VERSION ""

NS_ :

BS_:

BU_: GENERIC_GWMWakeup Generic_BCM TRM GWM _delete APIM SODL RTM FCIM PDM SCMH SCMG HSWM GPSM RSM SODR DDM RBM DSM SCME TSTR

BO_ 292 ClmtCtrlSeatSet_Cmd: 8 FCIM
 SG_ ClmtCtrlSeat_SetCmd_Psgr : 15|8@0+ (1,0) [0|254] "SED"  SCME
 SG_ ClmtCtrlSeat_SetCmd_Dvr : 7|8@0+ (1,0) [0|254] "SED"  SCME

BO_ 1284 DDM_Network_MgmtM: 8 DDM
 SG_ DDM_Network_Mgmt : 7|64@0+ (1,0) [0|1.844674407371E+019] "unitless"  PDM,GWM,TRM,RTM,FCIM,RBM,GPSM,DSM,SCME

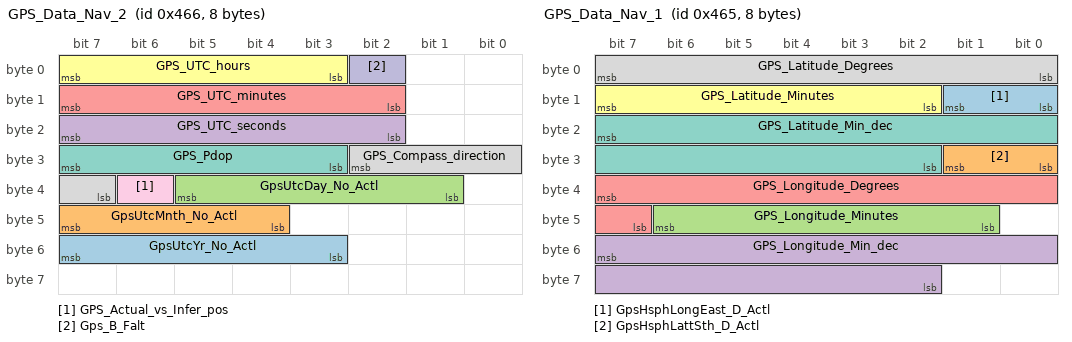
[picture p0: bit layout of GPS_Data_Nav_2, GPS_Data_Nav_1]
BO_ 1126 GPS_Data_Nav_2: 8 GPSM
 SG_ GpsUtcYr_No_Actl : 55|5@0+ (1,2010) [2010|2040] "Year"  RSM,APIM,GWM
 SG_ GpsUtcMnth_No_Actl : 47|4@0+ (1,1) [1|15] "Month"  RSM,APIM,GWM
 SG_ GpsUtcDay_No_Actl : 37|5@0+ (1,1) [1|31] "Day"  RSM,APIM,GWM
 SG_ GPS_UTC_seconds : 23|6@0+ (1,0) [0|59] "seconds"  RSM,APIM,GWM
 SG_ GPS_UTC_minutes : 15|6@0+ (1,0) [0|59] "Minutes"  RSM,APIM,GWM
 SG_ GPS_UTC_hours : 7|5@0+ (1,0) [0|23] "Hours"  RSM,APIM,GWM
 SG_ GPS_Pdop : 31|5@0+ (0.2,0) [0|5.8] "unitless"  RSM,APIM,GWM
 SG_ GPS_Compass_direction : 26|4@0+ (1,0) [0|15] "SED"  RSM,APIM,GWM
 SG_ GPS_Actual_vs_Infer_pos : 38|1@0+ (1,0) [0|1] "SED"  RSM,APIM,GWM
 SG_ Gps_B_Falt : 2|1@0+ (1,0) [0|1] "SED"  RSM,APIM,GWM

BO_ 1125 GPS_Data_Nav_1: 8 GPSM
 SG_ GpsHsphLongEast_D_Actl : 9|2@0+ (1,0) [0|3] "SED"  RSM,APIM,GWM
 SG_ GpsHsphLattSth_D_Actl : 25|2@0+ (1,0) [0|3] "SED"  RSM,APIM,GWM
 SG_ GPS_Longitude_Minutes : 46|6@0+ (1,0) [0|61] "Minutes"  RSM,APIM,GWM
 SG_ GPS_Longitude_Min_dec : 55|14@0+ (0.0001,0) [0|1.6381] "Minutes"  RSM,APIM,GWM
 SG_ GPS_Longitude_Degrees : 39|9@0+ (1,-179) [-179|330] "Degrees"  RSM,APIM,GWM
 SG_ GPS_Latitude_Minutes : 15|6@0+ (1,0) [0|61] "Minutes"  RSM,APIM,GWM
 SG_ GPS_Latitude_Min_dec : 23|14@0+ (0.0001,0) [0|1.6381] "Minutes"  RSM,APIM,GWM
 SG_ GPS_Latitude_Degrees : 7|8@0+ (1,-89) [-89|164] "Degrees"  RSM,APIM,GWM

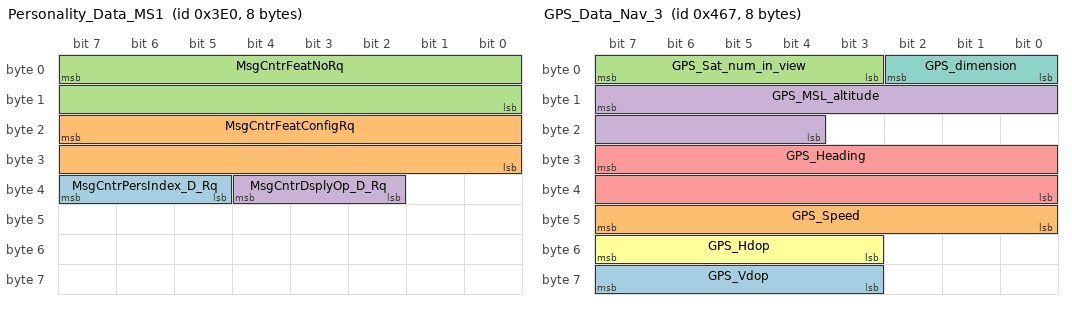
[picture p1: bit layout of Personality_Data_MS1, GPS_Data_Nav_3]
BO_ 992 Personality_Data_MS1: 8 GWM
 SG_ MsgCntrPersIndex_D_Rq : 39|3@0+ (1,0) [0|7] "SED"  DDM,FCIM,DSM
 SG_ MsgCntrFeatConfigRq : 23|16@0+ (1,0) [0|65535] "Undefined"  DDM,FCIM,DSM
 SG_ MsgCntrFeatNoRq : 7|16@0+ (1,0) [0|65535] "Number"  DDM,FCIM,DSM
 SG_ MsgCntrDsplyOp_D_Rq : 36|3@0+ (1,0) [0|7] "SED"  DDM,FCIM,DSM

BO_ 1127 GPS_Data_Nav_3: 8 GPSM
 SG_ GPS_Vdop : 63|5@0+ (0.2,0) [0|5.8] "unitless"  RSM,APIM,GWM
 SG_ GPS_Speed : 47|8@0+ (1,0) [0|253] "MPH"  RSM,APIM,GWM
 SG_ GPS_Sat_num_in_view : 7|5@0+ (1,0) [0|29] "unitless"  RSM,APIM,GWM
 SG_ GPS_MSL_altitude : 15|12@0+ (10,-20460) [-20460|20470] "feet"  RSM,APIM,GWM
 SG_ GPS_Heading : 31|16@0+ (0.01,0) [0|655.33] "Degrees"  RSM,APIM,GWM
 SG_ GPS_Hdop : 55|5@0+ (0.2,0) [0|5.8] "unitless"  RSM,APIM,GWM
 SG_ GPS_dimension : 2|3@0+ (1,0) [0|7] "SED"  RSM,APIM,GWM

BO_ 861 HSWheel_CC_Info_Stat: 8 HSWM
 SG_ SteWhlHeat_D_Stat : 7|4@0+ (1,0) [0|15] "SED"  FCIM

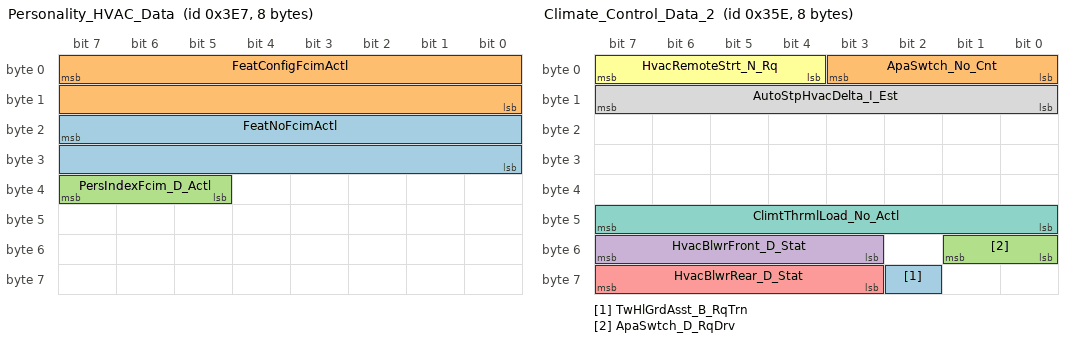
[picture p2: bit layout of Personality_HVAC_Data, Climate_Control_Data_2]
BO_ 999 Personality_HVAC_Data: 8 FCIM
 SG_ FeatNoFcimActl : 23|16@0+ (1,0) [0|65535] "Number"  GWM
 SG_ FeatConfigFcimActl : 7|16@0+ (1,0) [0|65535] "Undefined"  GWM
 SG_ PersIndexFcim_D_Actl : 39|3@0+ (1,0) [0|7] "SED"  GWM

BO_ 1998 TesterPhysicalResSODR: 8 SODR
 SG_ TesterPhysicalResSODR : 7|64@0+ (1,0) [0|1.84467E+019] "unitless"  TSTR

BO_ 1990 TesterPhysicalReqSODR: 8 TSTR
 SG_ TesterPhysicalReqSODR : 7|64@0+ (1,0) [0|1.84467E+019] "unitless"  SODR

BO_ 1996 TesterPhysicalResSODL: 8 SODL
 SG_ TesterPhysicalResSODL : 7|64@0+ (1,0) [0|1.84467E+019] "unitless"  TSTR

BO_ 1988 TesterPhysicalReqSODL: 8 TSTR
 SG_ TesterPhysicalReqSODL : 7|64@0+ (1,0) [0|1.84467E+019] "unitless"  SODL

BO_ 862 Climate_Control_Data_2: 8 FCIM
 SG_ TwHlGrdAsst_B_RqTrn : 58|1@0+ (1,0) [0|1] "SED"  GWM
 SG_ ApaSwtch_No_Cnt : 3|4@0+ (1,0) [0|15] "Unitless"  GWM
 SG_ ApaSwtch_D_RqDrv : 49|2@0+ (1,0) [0|3] "SED"  GWM
 SG_ HvacBlwrFront_D_Stat : 55|5@0+ (1,0) [0|31] "SED"  GWM
 SG_ HvacBlwrRear_D_Stat : 63|5@0+ (1,0) [0|31] "SED"  GWM
 SG_ HvacRemoteStrt_N_Rq : 7|4@0+ (100,450) [450|1950] "RPM"  GWM
 SG_ ClimtThrmlLoad_No_Actl : 47|8@0+ (1,0) [0|254] "unitless"  GWM
 SG_ AutoStpHvacDelta_I_Est : 15|8@0+ (1,-192) [-192|62] "ampere"  GWM

BO_ 828 Pass_Window_Stat: 8 PDM
 SG_ RearPassWindowPos : 4|3@0+ (1,0) [0|7] "SED"  FCIM,GWM,Generic_BCM
 SG_ PassWindowPosition : 7|3@0+ (1,0) [0|7] "SED"  FCIM,GWM,Generic_BCM

BO_ 2000 TesterPhysicalReqAPIM: 8 TSTR
 SG_ TesterPhysicalReqAPIM : 7|64@0+ (1,0) [0|1.84467E+019] "unitless"  APIM

BO_ 1894 TesterPhysicalReqRBM: 8 TSTR
 SG_ TesterPhysicalReqRBM : 7|64@0+ (1,0) [0|1.84467E+019] "unitless"  RBM

BO_ 1349 RBM_Network_MgmtM: 8 RBM
 SG_ RBM_Network_Mgmt : 7|64@0+ (1,0) [0|1.844674407371E+019] "unitless"  APIM,PDM,TRM,GWM,RTM,FCIM,GPSM,DSM,DDM,SCME

BO_ 1902 TesterPhysicalResRBM: 8 RBM
 SG_ TesterPhysicalResRBM : 7|64@0+ (1,0) [0|1.84467E+019] "unitless"  TSTR

BO_ 1860 TesterPhysicalReqDSM: 8 TSTR
 SG_ TesterPhysicalReqDSM : 7|64@0+ (1,0) [0|1.84467E+019] "unitless"  DSM

BO_ 1868 TesterPhysicalResDSM: 8 DSM
 SG_ TesterPhysicalResDSM : 7|64@0+ (1,0) [0|1.84467E+019] "unitless"  TSTR

BO_ 1918 TesterPhysicalResSCME: 8 SCME
 SG_ TesterPhysicalResSCME : 7|64@0+ (1,0) [0|1.84467E+019] "unitless"  TSTR

BO_ 1910 TesterPhysicalReqSCME: 8 TSTR
 SG_ TesterPhysicalReqSCME : 7|64@0+ (1,0) [0|1.84467E+019] "unitless"  SCME

BO_ 1814 TesterPhysicalReqGWM_M1: 8 TSTR
 SG_ TesterPhysicalReqGWM_M1 : 7|64@0+ (1,0) [0|1.84467E+019] "unitless"  GWM

BO_ 1822 TesterPhysicalResGWM_MS1: 8 GWM
 SG_ TesterPhysicalResGWM_M1 : 7|64@0+ (1,0) [0|1.84467E+019] "unitless"  TSTR

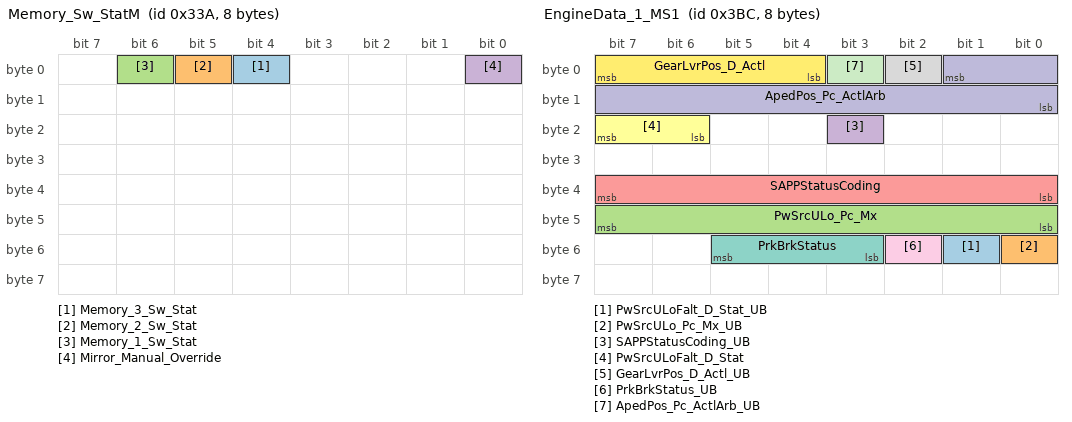
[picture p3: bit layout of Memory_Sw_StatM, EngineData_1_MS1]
BO_ 826 Memory_Sw_StatM: 8 DDM
 SG_ Memory_3_Sw_Stat : 4|1@0+ (1,0) [0|1] "SED"  DSM
 SG_ Memory_2_Sw_Stat : 5|1@0+ (1,0) [0|1] "SED"  DSM
 SG_ Memory_1_Sw_Stat : 6|1@0+ (1,0) [0|1] "SED"  DSM
 SG_ Mirror_Manual_Override : 0|1@0+ (1,0) [0|1] "SED"  DSM

BO_ 853 Clmt_Button_Stat1: 8 FCIM
 SG_ RHS_Cond_Seat_Status : 63|3@0+ (1,0) [0|7] "SED"  GWM
 SG_ LHS_Cond_Seat_Status : 10|3@0+ (1,0) [0|7] "SED"  GWM
 SG_ Htd_Strg_Whl_Status : 27|2@0+ (1,0) [0|3] "SED"  GWM
 SG_ Htd_Strg_Whl_Btn_Stt : 29|2@0+ (1,0) [0|3] "SED"  GWM
 SG_ Defrost_Btn_Stt : 3|2@0+ (1,0) [0|3] "SED"  GWM
 SG_ CC_Fr_Btn_User_Adj : 15|5@0+ (1,0) [0|31] "SED"  GWM
 SG_ RHS_Htd_Seat_Btn_Stt : 53|2@0+ (1,0) [0|3] "SED"  GWM
 SG_ RHS_Cld_Seat_Btn_Stt : 55|2@0+ (1,0) [0|3] "SED"  GWM
 SG_ Outside_Btn_Stt : 47|2@0+ (1,0) [0|3] "SED"  GWM
 SG_ LHS_Htd_Seat_Btn_Stt : 39|2@0+ (1,0) [0|3] "SED"  GWM
 SG_ LHS_Cld_Seat_Btn_Stt : 25|2@0+ (1,0) [0|3] "SED"  GWM
 SG_ Htd_Frt_Wsh_Btn_Stt : 31|2@0+ (1,0) [0|3] "SED"  GWM
 SG_ Auto_Recirc_Btn_Stt : 5|2@0+ (1,0) [0|3] "SED"  GWM
 SG_ Recirc_Btn_Stt : 41|2@0+ (1,0) [0|3] "SED"  GWM
 SG_ Rear_Defrost_Btn_Stt : 43|2@0+ (1,0) [0|3] "SED"  GWM
 SG_ My_Temp_Btn_Stt : 33|2@0+ (1,0) [0|3] "SED"  GWM
 SG_ Max_Defrost_Btn_Stt : 35|2@0+ (1,0) [0|3] "SED"  GWM
 SG_ Max_AC_Btn_Stt : 37|2@0+ (1,0) [0|3] "SED"  GWM
 SG_ Front_AUTO_Label : 19|2@0+ (1,0) [0|3] "SED"  GWM
 SG_ Windscreen_Btn_Stt : 51|2@0+ (1,0) [0|3] "SED"  GWM
 SG_ Panel_Btn_Stt : 45|2@0+ (1,0) [0|3] "SED"  GWM
 SG_ Front_Power_Btn_Stt : 17|2@0+ (1,0) [0|3] "SED"  GWM
 SG_ Front_AUTO_Btn_Stt : 21|2@0+ (1,0) [0|3] "SED"  GWM
 SG_ Floor_Btn_Stt : 23|2@0+ (1,0) [0|3] "SED"  GWM
 SG_ Dual_Button_Stt : 1|2@0+ (1,0) [0|3] "SED"  GWM
 SG_ AC_Btn_Stt : 7|2@0+ (1,0) [0|3] "SED"  GWM

BO_ 1034 GGCC_Config_Mgmt_ID_1_MS1: 8 GWM
 SG_ VehicleGGCCData : 7|64@0+ (1,0) [0|1.84467E+019] "mixed"  TRM,PDM,RTM,DDM,FCIM,GPSM,RBM,SODL,SODR

BO_ 956 EngineData_1_MS1: 8 GWM
 SG_ PwSrcULoFalt_D_Stat_UB : 49|1@0+ (1,0) [0|1] "SED" Vector__XXX
 SG_ PwSrcULo_Pc_Mx_UB : 48|1@0+ (1,0) [0|1] "SED"  FCIM
 SG_ PwSrcULo_Pc_Mx : 47|8@0+ (0.4,0) [0|101.6] "%"  FCIM
 SG_ SAPPStatusCoding_UB : 19|1@0+ (1,0) [0|1] "SED"  FCIM,SODL,SODR
 SG_ SAPPStatusCoding : 39|8@0+ (1,0) [0|255] "unitless"  FCIM,SODL,SODR
 SG_ PwSrcULoFalt_D_Stat : 23|2@0+ (1,0) [0|3] "SED" Vector__XXX
 SG_ PrkBrkStatus : 53|3@0+ (1,0) [0|7] "SED"  FCIM
 SG_ GearLvrPos_D_Actl_UB : 2|1@0+ (1,0) [0|1] "SED"  RBM,FCIM,DSM,SCMG,SCMH,DDM,PDM,GPSM,SODL,SODR
 SG_ PrkBrkStatus_UB : 50|1@0+ (1,0) [0|1] "SED"  FCIM
 SG_ ApedPos_Pc_ActlArb : 1|10@0+ (0.1,0) [0|102.3] "%"  FCIM
 SG_ ApedPos_Pc_ActlArb_UB : 3|1@0+ (1,0) [0|1] "SED"  FCIM
 SG_ GearLvrPos_D_Actl : 7|4@0+ (1,0) [0|15] "SED"  RBM,FCIM,DSM,SCMG,SCMH,DDM,PDM,GPSM,SODR,SODL

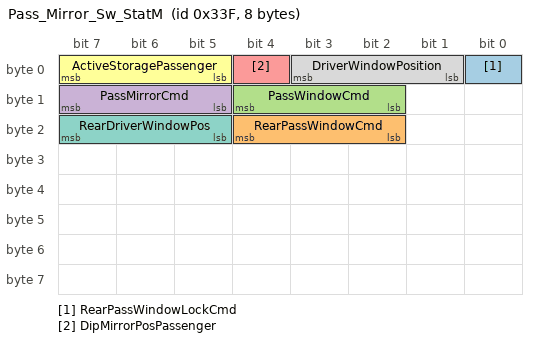
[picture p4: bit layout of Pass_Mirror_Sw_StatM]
BO_ 831 Pass_Mirror_Sw_StatM: 8 DDM
 SG_ RearPassWindowLockCmd : 0|1@0+ (1,0) [0|1] "SED"  PDM
 SG_ RearPassWindowCmd : 20|3@0+ (1,0) [0|7] "SED"  PDM
 SG_ PassWindowCmd : 12|3@0+ (1,0) [0|7] "SED"  PDM
 SG_ PassMirrorCmd : 15|3@0+ (1,0) [0|7] "SED"  PDM
 SG_ DipMirrorPosPassenger : 4|1@0+ (1,0) [0|1] "SED"  PDM
 SG_ ActiveStoragePassenger : 7|3@0+ (1,0) [0|7] "SED"  PDM
 SG_ RearDriverWindowPos : 23|3@0+ (1,0) [0|7] "SED"  FCIM,GWM
 SG_ DriverWindowPosition : 3|3@0+ (1,0) [0|7] "SED"  FCIM,Generic_BCM,GWM

BO_ 1820 TesterPhysicalResHSWM: 8 HSWM
 SG_ TesterPhysicalResHSWM : 7|64@0+ (1,0) [0|1.84467E+019] "unitless"  TSTR

BO_ 1812 TesterPhysicalReqHSWM: 8 TSTR
 SG_ TesterPhysicalReqHSWM : 7|64@0+ (1,0) [0|1.84467E+019] "unitless"  HSWM

BO_ 1291 DSM_Network_MgmtM: 8 DSM
 SG_ DSM_Network_Mgmt : 7|8@0+ (1,0) [0|254] "unitless"  APIM,PDM,TRM,GWM,RTM,FCIM,RBM,GPSM,DDM,SCME

BO_ 1319 SCME_Network_MgmtM: 8 SCME
 SG_ SCME_Network_Mgmt : 7|64@0+ (1,0) [0|1.844674407371E+019] "unitless"  APIM,PDM,TRM,RTM,FCIM,GWM,RBM,GPSM,DSM,DDM

BO_ 1388 GPSM_Network_MgmtM: 8 GPSM
 SG_ GPSM_Network_Mgmt : 7|64@0+ (1,0) [0|1.844674407371E+019] "unitless"  APIM,PDM,TRM,GWM,FCIM,RTM,SCME,DDM,DSM,RBM

BO_ 1801 TesterPhysicalResGPSM: 8 GPSM
 SG_ TesterPhysicalResGPSM : 7|64@0+ (1,0) [0|1.84467E+019] "unitless"  TSTR

BO_ 1793 TesterPhysicalReqGPSM: 8 TSTR
 SG_ TesterPhysicalReqGPSM : 7|64@0+ (1,0) [0|1.84467E+019] "unitless"  GPSM

BO_TX_BU_ 1126 : GWM,GPSM;
BO_TX_BU_ 1125 : GWM,GPSM;
BO_TX_BU_ 1127 : GWM,GPSM;
CM_ BO_ 1126 "Only NAV ACM & GPS need to Transmit this message. 
Non-NAV ACM shall not transmit it.";
CM_ BO_ 1125 "Only NAV ACM & GPS need to Transmit this message. 
Non-NAV ACM shall not transmit it.";
CM_ BO_ 1127 "Only NAV ACM & GPS need to Transmit this message. 
Non-NAV ACM shall not transmit it.";
CM_ BO_ 828 "Set GenSigSendType = NoSigSendType (Cyclic) for the following signals, D.Card 3/31/08
Driver_Lock_Sw_Stat
";
CM_ SG_ 1034 VehicleGGCCData "RCMGenSigTimeout=6000";
CM_ SG_ 956 ApedPos_Pc_ActlArb "ABSGenSigTimeoutTime=1000";
BA_DEF_ SG_  "U_V36X_MY18_5_Gas_Rx" ENUM  "No","Yes";
BA_DEF_ SG_  "U_V36X_MY18_5_Hev_Rx" ENUM  "No","Yes";
BA_DEF_ SG_  "U_U55x_MY18_Gas_Rx" ENUM  "No","Yes";
BA_DEF_ SG_  "U_V408_MY18_Gas_Rx" ENUM  "No","Yes";
BA_DEF_ SG_  "U_V408_MY18_Diesel_Rx" ENUM  "No","Yes";
BA_DEF_ SG_  "U_V36X_MY18_5_Diesel_Rx" ENUM  "No","Yes";
BA_DEF_ SG_  "U_V36X_MY19_5_Diesel_Rx" ENUM  "No","Yes";
BA_DEF_ SG_  "U_V363E_N_MY19_5_20_Gas_Rx" ENUM  "No","Yes";
BA_DEF_ SG_  "U_V363E_N_MY19_5_20_Diesel_Rx" ENUM  "No","Yes";
BA_DEF_ SG_  "U_U55x_MY18_Gas_Tx" ENUM  "No","Yes";
BA_DEF_ SG_  "GenSigTimeoutTime_SCMJ" INT 0 100000;
BA_DEF_ BO_  "FrameGatewayNetwork" STRING ;
BA_DEF_ SG_  "U_CD42_MY16_Diesel_Rx" ENUM  "No","Yes";
BA_DEF_ SG_  "U_CD42_MY16_Gas_Rx" ENUM  "No","Yes";
BA_DEF_ SG_  "U_CD43_MY17_Gas_Rx" ENUM  "No","Yes";
BA_DEF_ SG_  "U_P552_MY17_Gas_Rx" ENUM  "No","Yes";
BA_DEF_ SG_  "U_P552_MY17_Gas_Tx" ENUM  "No","Yes";
BA_DEF_ SG_  "GenSigTimeoutTime_SOBDMD_AHCM_F" INT 0 100000;
BA_DEF_ SG_  "GenSigTimeoutTime_SFMA" INT 0 100000;
BA_DEF_ SG_  "GenSigTimeoutTime_SFMB" INT 0 100000;
BA_DEF_ SG_  "GenSigTimeoutTime_SCMD" INT 0 100000;
BA_DEF_ SG_  "GenSigTimeoutTime_DCMH" INT 0 100000;
BA_DEF_ SG_  "GenSigTimeoutTime_DCMG" INT 0 100000;
BA_DEF_ SG_  "GenSigTimeoutTime_DCMF" INT 0 100000;
BA_DEF_ SG_  "GenSigTimeoutTime_DCME" INT 0 100000;
BA_DEF_ SG_  "GenSigTimeoutTime_BCMB_ABM" INT 0 100000;
BA_DEF_ SG_  "GenSigTimeoutTime_SCMC" INT 0 100000;
BA_DEF_ SG_  "GenSigTimeoutTime_BCMB_CAPM" INT 0 100000;
BA_DEF_ SG_  "GenSigTimeoutTime_GFM_ASM" INT 0 100000;
BA_DEF_ SG_  "GenSigTimeoutTime_SCMB_PSM" INT 0 100000;
BA_DEF_ SG_  "GenSigTimeoutTime_BCMB_ALCM" INT 0 100000;
BA_DEF_ SG_  "U_CD42_MY15_Diesel_Rx" ENUM  "No","Yes";
BA_DEF_ SG_  "U_CD42_MY15_Gas_Rx" ENUM  "No","Yes";
BA_DEF_ SG_  "U_U502_MY16_Gas_Rx" ENUM  "No","Yes";
BA_DEF_ SG_  "U_P558_MY17_Gas_Rx" ENUM  "No","Yes";
BA_DEF_ SG_  "U_P558_MY17_Diesel_Rx" ENUM  "No","Yes";
BA_DEF_ SG_  "U_CD42_MY15_Diesel_Tx" ENUM  "No","Yes";
BA_DEF_ SG_  "U_CD42_MY15_Gas_Tx" ENUM  "No","Yes";
BA_DEF_ SG_  "U_CD4_MY15_Diesel_Tx" ENUM  "No","Yes";
BA_DEF_ SG_  "U_CD4_MY15_Gas_Tx" ENUM  "No","Yes";
BA_DEF_ SG_  "U_CD4_MY15_Hev_Tx" ENUM  "No","Yes";
BA_DEF_ SG_  "U_CD4_MY15_Phev_Tx" ENUM  "No","Yes";
BA_DEF_ SG_  "U_P558_MY17_Gas_Tx" ENUM  "No","Yes";
BA_DEF_ SG_  "U_P558_MY17_Diesel_Tx" ENUM  "No","Yes";
BA_DEF_ SG_  "GenSigTimeoutTime_SCMF" INT 0 100000;
BA_DEF_ SG_  "GenSigTimeoutTime_RGTM" INT 0 100000;
BA_DEF_ SG_  "GenSigTimeoutTime_GENERIC" INT 0 100000;
BA_DEF_ SG_  "GenSigTimeoutTime_AHCM_FOH" INT 0 100000;
BA_DEF_ SG_  "GenSigTimeoutTime_RLCMA" INT 0 100000;
BA_DEF_ SG_  "GenSigTimeoutTime_BCMB" INT 0 100000;
BA_DEF_ SG_  "GenSigTimeoutTime_RHVAC" INT 0 100000;
BA_DEF_ SG_  "GenSigTimeoutTime_MRCMB" INT 0 100000;
BA_DEF_ SG_  "GenSigTimeoutTime_MRCMA" INT 0 100000;
BA_DEF_ SG_  "GenSigTimeoutTime_HVAC_RCCM" INT 0 100000;
BA_DEF_ SG_  "Gateway_ID" INT 0 0;
BA_DEF_ SG_  "GenSigTimeoutTime__delete" INT 0 100000;
BA_DEF_ SG_  "GenSigTimeoutTime_APIM" INT 0 100000;
BA_DEF_ SG_  "GenSigTimeoutTime_Generic_BCM" INT 0 100000;
BA_DEF_ SG_  "GenSigTimeoutTime_RSM" INT 0 100000;
BA_DEF_ SG_  "GenSigTimeoutTime_PDM" INT 0 100000;
BA_DEF_ SG_  "GenSigTimeoutTime_TRM" INT 0 100000;
BA_DEF_ SG_  "GenSigTimeoutTime_SCMG" INT 0 100000;
BA_DEF_ SG_  "GenSigTimeoutTime_SCMH" INT 0 100000;
BA_DEF_ SG_  "GenSigTimeoutTime_RTM" INT 0 100000;
BA_DEF_ SG_  "GenSigTimeoutTime_GWM" INT 0 100000;
BA_DEF_ SG_  "GenSigTimeoutTime_FCIM" INT 0 100000;
BA_DEF_ SG_  "GenSigTimeoutTime_HSWM" INT 0 100000;
BA_DEF_ SG_  "GenSigTimeoutTime_GPSM" INT 0 100000;
BA_DEF_ SG_  "GenSigTimeoutTime_RBM" INT 0 100000;
BA_DEF_ SG_  "GenSigTimeoutTime_DDM" INT 0 100000;
BA_DEF_ SG_  "GenSigTimeoutTime_DSM" INT 0 100000;
BA_DEF_ SG_  "GenSigTimeoutTime_SODR" INT 0 100000;
BA_DEF_ SG_  "GenSigTimeoutTime_SODL" INT 0 100000;
BA_DEF_ SG_  "GenSigTimeoutTime_TSTR" INT 0 100000;
BA_DEF_ SG_  "GenSigTimeoutTime_SCME" INT 0 100000;
BA_DEF_ BO_  "FrameGatewayMS1" HEX 0 1407;
BA_DEF_ BO_  "FrameGatewayHS3" HEX 0 1407;
BA_DEF_ BO_  "FrameGatewayHS2" HEX 0 1407;
BA_DEF_ BO_  "FrameGatewayHS1" HEX 0 1407;
BA_DEF_ BO_  "NetworkInitialization" ENUM  "No","Yes";
BA_DEF_ BO_  "FrameGatewayId" HEX 0 1407;
BA_DEF_ BO_  "EventRateOfChange" INT 10 10000;
BA_DEF_ BO_  "GenMsgStartDelayTime" INT 0 10000;
BA_DEF_ BO_  "GenMsgNrOfRepetition" INT 0 100;
BA_DEF_ BO_  "GenMsgDelayTime" INT 0 1000;
BA_DEF_ BO_  "GenMsgCycleTime" INT 0 100000;
BA_DEF_ BO_  "GenMsgSendType" ENUM  "FixedPeriodic","Event","EnabledPeriodic","NotUsed","NotUsed","EventPeriodic","NotUsed","NotUsed","NoMsgSendType";
BA_DEF_ SG_  "U_CD4_MY14_Phev_Tx" ENUM  "No","Yes";
BA_DEF_ SG_  "U_CD4_MY14_Hev_Tx" ENUM  "No","Yes";
BA_DEF_ SG_  "U_CD4_MY14_Gas_Tx" ENUM  "No","Yes";
BA_DEF_ SG_  "U_CD4_MY14_Diesel_Tx" ENUM  "No","Yes";
BA_DEF_ SG_  "U_CD43_MY16_Gas_Tx" ENUM  "No","Yes";
BA_DEF_ SG_  "U_UP375_MY15_Diesel_Tx" ENUM  "No","Yes";
BA_DEF_ SG_  "U_UP375_MY15_Gas_Tx" ENUM  "No","Yes";
BA_DEF_ SG_  "U_U502_MY15_Gas_Tx" ENUM  "No","Yes";
BA_DEF_ SG_  "U_B562LC_MY14_Gas_Tx" ENUM  "No","Yes";
BA_DEF_ SG_  "U_B562LC_MY14_Diesel_Tx" ENUM  "No","Yes";
BA_DEF_ SG_  "U_C489_MY14_Gas_Tx" ENUM  "No","Yes";
BA_DEF_ SG_  "U_S550_MY15_Gas_Tx" ENUM  "No","Yes";
BA_DEF_ SG_  "U_P552_MY15_Gas_Tx" ENUM  "No","Yes";
BA_DEF_ SG_  "U_CD42_MY14_Gas_Tx" ENUM  "No","Yes";
BA_DEF_ SG_  "U_CD42_MY14_Diesel_Tx" ENUM  "No","Yes";
BA_DEF_ SG_  "U_CD4_MY13_Phev_Tx" ENUM  "No","Yes";
BA_DEF_ SG_  "U_CD4_MY13_Hev_Tx" ENUM  "No","Yes";
BA_DEF_ SG_  "U_CD4_MY13_Gas_Tx" ENUM  "No","Yes";
BA_DEF_ SG_  "U_CD4_MY13_Diesel_Tx" ENUM  "No","Yes";
BA_DEF_ SG_  "U_CD4_MY14_Phev_Rx" ENUM  "No","Yes";
BA_DEF_ SG_  "U_CD4_MY14_Hev_Rx" ENUM  "No","Yes";
BA_DEF_ SG_  "U_CD4_MY14_Gas_Rx" ENUM  "No","Yes";
BA_DEF_ SG_  "U_CD4_MY14_Diesel_Rx" ENUM  "No","Yes";
BA_DEF_ SG_  "U_CD43_MY16_Gas_Rx" ENUM  "No","Yes";
BA_DEF_ SG_  "U_UP375_MY15_Diesel_Rx" ENUM  "No","Yes";
BA_DEF_ SG_  "U_UP375_MY15_Gas_Rx" ENUM  "No","Yes";
BA_DEF_ SG_  "U_B479_MY15_Gas_Rx" ENUM  "No","Yes";
BA_DEF_ SG_  "U_U502_MY15_Gas_Rx" ENUM  "No","Yes";
BA_DEF_ SG_  "U_B562LC_MY14_Gas_Rx" ENUM  "No","Yes";
BA_DEF_ SG_  "U_B562LC_MY14_Diesel_Rx" ENUM  "No","Yes";
BA_DEF_ SG_  "U_C489_MY14_Gas_Rx" ENUM  "No","Yes";
BA_DEF_ SG_  "U_S550_MY15_Gas_Rx" ENUM  "No","Yes";
BA_DEF_ SG_  "U_P552_MY15_Gas_Rx" ENUM  "No","Yes";
BA_DEF_ SG_  "U_CD42_MY14_Gas_Rx" ENUM  "No","Yes";
BA_DEF_ SG_  "U_CD42_MY14_Diesel_Rx" ENUM  "No","Yes";
BA_DEF_ SG_  "U_CD4_MY13_Phev_Rx" ENUM  "No","Yes";
BA_DEF_ SG_  "U_CD4_MY13_Hev_Rx" ENUM  "No","Yes";
BA_DEF_ SG_  "U_CD4_MY13_Gas_Rx" ENUM  "No","Yes";
BA_DEF_ SG_  "U_CD4_MY13_Diesel_Rx" ENUM  "No","Yes";
BA_DEF_ SG_  "ContentDependant" ENUM  "No","Yes";
BA_DEF_ SG_  "GenSigStartValue" INT 0 1000000000;
BA_DEF_ SG_  "UsedOnPgmDBC" ENUM  "No","Yes";
BA_DEF_ SG_  "CrossOver_LIN" ENUM  "No","Yes";
BA_DEF_ SG_  "CrossOver_InfoCAN" ENUM  "No","Yes";
BA_DEF_ SG_  "WakeupSignal" ENUM  "No","Yes";
BA_DEF_ SG_  "FMC_SIG_SSPEC" STRING ;
BA_DEF_ SG_  "GenSigMissingSourceValue" INT 0 1000000000;
BA_DEF_ SG_  "GenSigInactiveValue" INT 0 100000;
BA_DEF_ SG_  "GenSigSendType" ENUM  "Cyclic","OnWrite","vector_leerstring","OnChange","vector_leerstring","IfActive","vector_leerstring","NoSigSendType";
BA_DEF_ BO_  "DiagState" ENUM  "No","Yes";
BA_DEF_ BO_  "TpTxIndex" INT 0 255;
BA_DEF_ BO_  "DiagRequest" ENUM  "No","Yes";
BA_DEF_ BO_  "DiagResponse" ENUM  "No","Yes";
BA_DEF_ BO_  "NmMessage" ENUM  "No","Yes";
BA_DEF_ BO_  "GenMsgILSupport" ENUM  "No","Yes";
BA_DEF_DEF_  "U_V36X_MY18_5_Gas_Rx" "No";
BA_DEF_DEF_  "U_V36X_MY18_5_Hev_Rx" "No";
BA_DEF_DEF_  "U_U55x_MY18_Gas_Rx" "No";
BA_DEF_DEF_  "U_V408_MY18_Gas_Rx" "No";
BA_DEF_DEF_  "U_V408_MY18_Diesel_Rx" "No";
BA_DEF_DEF_  "U_V36X_MY18_5_Diesel_Rx" "No";
BA_DEF_DEF_  "U_V36X_MY19_5_Diesel_Rx" "No";
BA_DEF_DEF_  "U_V363E_N_MY19_5_20_Gas_Rx" "No";
BA_DEF_DEF_  "U_V363E_N_MY19_5_20_Diesel_Rx" "No";
BA_DEF_DEF_  "U_U55x_MY18_Gas_Tx" "No";
BA_DEF_DEF_  "GenSigTimeoutTime_SCMJ" 5000;
BA_DEF_DEF_  "FrameGatewayNetwork" "NONE";
BA_DEF_DEF_  "U_CD42_MY16_Diesel_Rx" "No";
BA_DEF_DEF_  "U_CD42_MY16_Gas_Rx" "No";
BA_DEF_DEF_  "U_CD43_MY17_Gas_Rx" "No";
BA_DEF_DEF_  "U_P552_MY17_Gas_Rx" "No";
BA_DEF_DEF_  "U_P552_MY17_Gas_Tx" "No";
BA_DEF_DEF_  "GenSigTimeoutTime_SOBDMD_AHCM_F" 5000;
BA_DEF_DEF_  "GenSigTimeoutTime_SFMA" 5000;
BA_DEF_DEF_  "GenSigTimeoutTime_SFMB" 5000;
BA_DEF_DEF_  "GenSigTimeoutTime_SCMD" 5000;
BA_DEF_DEF_  "GenSigTimeoutTime_DCMH" 5000;
BA_DEF_DEF_  "GenSigTimeoutTime_DCMG" 5000;
BA_DEF_DEF_  "GenSigTimeoutTime_DCMF" 5000;
BA_DEF_DEF_  "GenSigTimeoutTime_DCME" 5000;
BA_DEF_DEF_  "GenSigTimeoutTime_BCMB_ABM" 5000;
BA_DEF_DEF_  "GenSigTimeoutTime_SCMC" 5000;
BA_DEF_DEF_  "GenSigTimeoutTime_BCMB_CAPM" 5000;
BA_DEF_DEF_  "GenSigTimeoutTime_GFM_ASM" 5000;
BA_DEF_DEF_  "GenSigTimeoutTime_SCMB_PSM" 5000;
BA_DEF_DEF_  "GenSigTimeoutTime_BCMB_ALCM" 5000;
BA_DEF_DEF_  "U_CD42_MY15_Diesel_Rx" "No";
BA_DEF_DEF_  "U_CD42_MY15_Gas_Rx" "No";
BA_DEF_DEF_  "U_U502_MY16_Gas_Rx" "No";
BA_DEF_DEF_  "U_P558_MY17_Gas_Rx" "No";
BA_DEF_DEF_  "U_P558_MY17_Diesel_Rx" "No";
BA_DEF_DEF_  "U_CD42_MY15_Diesel_Tx" "No";
BA_DEF_DEF_  "U_CD42_MY15_Gas_Tx" "No";
BA_DEF_DEF_  "U_CD4_MY15_Diesel_Tx" "No";
BA_DEF_DEF_  "U_CD4_MY15_Gas_Tx" "No";
BA_DEF_DEF_  "U_CD4_MY15_Hev_Tx" "No";
BA_DEF_DEF_  "U_CD4_MY15_Phev_Tx" "No";
BA_DEF_DEF_  "U_P558_MY17_Gas_Tx" "No";
BA_DEF_DEF_  "U_P558_MY17_Diesel_Tx" "No";
BA_DEF_DEF_  "GenSigTimeoutTime_SCMF" 5000;
BA_DEF_DEF_  "GenSigTimeoutTime_RGTM" 5000;
BA_DEF_DEF_  "GenSigTimeoutTime_GENERIC" 5000;
BA_DEF_DEF_  "GenSigTimeoutTime_AHCM_FOH" 5000;
BA_DEF_DEF_  "GenSigTimeoutTime_RLCMA" 5000;
BA_DEF_DEF_  "GenSigTimeoutTime_BCMB" 5000;
BA_DEF_DEF_  "GenSigTimeoutTime_RHVAC" 5000;
BA_DEF_DEF_  "GenSigTimeoutTime_MRCMB" 5000;
BA_DEF_DEF_  "GenSigTimeoutTime_MRCMA" 5000;
BA_DEF_DEF_  "GenSigTimeoutTime_HVAC_RCCM" 5000;
BA_DEF_DEF_  "Gateway_ID" 0;
BA_DEF_DEF_  "GenSigTimeoutTime__delete" 5000;
BA_DEF_DEF_  "GenSigTimeoutTime_APIM" 5000;
BA_DEF_DEF_  "GenSigTimeoutTime_Generic_BCM" 5000;
BA_DEF_DEF_  "GenSigTimeoutTime_RSM" 5000;
BA_DEF_DEF_  "GenSigTimeoutTime_PDM" 5000;
BA_DEF_DEF_  "GenSigTimeoutTime_TRM" 5000;
BA_DEF_DEF_  "GenSigTimeoutTime_SCMG" 5000;
BA_DEF_DEF_  "GenSigTimeoutTime_SCMH" 5000;
BA_DEF_DEF_  "GenSigTimeoutTime_RTM" 5000;
BA_DEF_DEF_  "GenSigTimeoutTime_GWM" 5000;
BA_DEF_DEF_  "GenSigTimeoutTime_FCIM" 5000;
BA_DEF_DEF_  "GenSigTimeoutTime_HSWM" 5000;
BA_DEF_DEF_  "GenSigTimeoutTime_GPSM" 5000;
BA_DEF_DEF_  "GenSigTimeoutTime_RBM" 5000;
BA_DEF_DEF_  "GenSigTimeoutTime_DDM" 5000;
BA_DEF_DEF_  "GenSigTimeoutTime_DSM" 5000;
BA_DEF_DEF_  "GenSigTimeoutTime_SODR" 5000;
BA_DEF_DEF_  "GenSigTimeoutTime_SODL" 5000;
BA_DEF_DEF_  "GenSigTimeoutTime_TSTR" 5000;
BA_DEF_DEF_  "GenSigTimeoutTime_SCME" 5000;
BA_DEF_DEF_  "FrameGatewayMS1" 0;
BA_DEF_DEF_  "FrameGatewayHS3" 0;
BA_DEF_DEF_  "FrameGatewayHS2" 0;
BA_DEF_DEF_  "FrameGatewayHS1" 0;
BA_DEF_DEF_  "NetworkInitialization" "No";
BA_DEF_DEF_  "FrameGatewayId" 0;
BA_DEF_DEF_  "EventRateOfChange" 10000;
BA_DEF_DEF_  "GenMsgStartDelayTime" 0;
BA_DEF_DEF_  "GenMsgNrOfRepetition" 1;
BA_DEF_DEF_  "GenMsgDelayTime" 20;
BA_DEF_DEF_  "GenMsgCycleTime" 0;
BA_DEF_DEF_  "GenMsgSendType" "NoMsgSendType";
BA_DEF_DEF_  "U_CD4_MY14_Phev_Tx" "No";
BA_DEF_DEF_  "U_CD4_MY14_Hev_Tx" "No";
BA_DEF_DEF_  "U_CD4_MY14_Gas_Tx" "No";
BA_DEF_DEF_  "U_CD4_MY14_Diesel_Tx" "No";
BA_DEF_DEF_  "U_CD43_MY16_Gas_Tx" "No";
BA_DEF_DEF_  "U_UP375_MY15_Diesel_Tx" "No";
BA_DEF_DEF_  "U_UP375_MY15_Gas_Tx" "No";
BA_DEF_DEF_  "U_U502_MY15_Gas_Tx" "No";
BA_DEF_DEF_  "U_B562LC_MY14_Gas_Tx" "No";
BA_DEF_DEF_  "U_B562LC_MY14_Diesel_Tx" "No";
BA_DEF_DEF_  "U_C489_MY14_Gas_Tx" "No";
BA_DEF_DEF_  "U_S550_MY15_Gas_Tx" "No";
BA_DEF_DEF_  "U_P552_MY15_Gas_Tx" "No";
BA_DEF_DEF_  "U_CD42_MY14_Gas_Tx" "No";
BA_DEF_DEF_  "U_CD42_MY14_Diesel_Tx" "No";
BA_DEF_DEF_  "U_CD4_MY13_Phev_Tx" "No";
BA_DEF_DEF_  "U_CD4_MY13_Hev_Tx" "No";
BA_DEF_DEF_  "U_CD4_MY13_Gas_Tx" "No";
BA_DEF_DEF_  "U_CD4_MY13_Diesel_Tx" "No";
BA_DEF_DEF_  "U_CD4_MY14_Phev_Rx" "No";
BA_DEF_DEF_  "U_CD4_MY14_Hev_Rx" "No";
BA_DEF_DEF_  "U_CD4_MY14_Gas_Rx" "No";
BA_DEF_DEF_  "U_CD4_MY14_Diesel_Rx" "No";
BA_DEF_DEF_  "U_CD43_MY16_Gas_Rx" "No";
BA_DEF_DEF_  "U_UP375_MY15_Diesel_Rx" "No";
BA_DEF_DEF_  "U_UP375_MY15_Gas_Rx" "No";
BA_DEF_DEF_  "U_B479_MY15_Gas_Rx" "No";
BA_DEF_DEF_  "U_U502_MY15_Gas_Rx" "No";
BA_DEF_DEF_  "U_B562LC_MY14_Gas_Rx" "No";
BA_DEF_DEF_  "U_B562LC_MY14_Diesel_Rx" "No";
BA_DEF_DEF_  "U_C489_MY14_Gas_Rx" "No";
BA_DEF_DEF_  "U_S550_MY15_Gas_Rx" "No";
BA_DEF_DEF_  "U_P552_MY15_Gas_Rx" "No";
BA_DEF_DEF_  "U_CD42_MY14_Gas_Rx" "No";
BA_DEF_DEF_  "U_CD42_MY14_Diesel_Rx" "No";
BA_DEF_DEF_  "U_CD4_MY13_Phev_Rx" "No";
BA_DEF_DEF_  "U_CD4_MY13_Hev_Rx" "No";
BA_DEF_DEF_  "U_CD4_MY13_Gas_Rx" "No";
BA_DEF_DEF_  "U_CD4_MY13_Diesel_Rx" "No";
BA_DEF_DEF_  "ContentDependant" "No";
BA_DEF_DEF_  "GenSigStartValue" 0;
BA_DEF_DEF_  "UsedOnPgmDBC" "Yes";
BA_DEF_DEF_  "CrossOver_LIN" "No";
BA_DEF_DEF_  "CrossOver_InfoCAN" "No";
BA_DEF_DEF_  "WakeupSignal" "No";
BA_DEF_DEF_  "FMC_SIG_SSPEC" "Unknown";
BA_DEF_DEF_  "GenSigMissingSourceValue" 0;
BA_DEF_DEF_  "GenSigInactiveValue" 0;
BA_DEF_DEF_  "GenSigSendType" "NoSigSendType";
BA_DEF_DEF_  "DiagState" "No";
BA_DEF_DEF_  "TpTxIndex" 0;
BA_DEF_DEF_  "DiagRequest" "No";
BA_DEF_DEF_  "DiagResponse" "No";
BA_DEF_DEF_  "NmMessage" "No";
BA_DEF_DEF_  "GenMsgILSupport" "Yes";
BA_ "GenMsgSendType" BO_ 292 5;
BA_ "GenMsgCycleTime" BO_ 292 1000;
BA_ "GenMsgILSupport" BO_ 1284 0;
BA_ "NmMessage" BO_ 1284 1;
BA_ "GenMsgSendType" BO_ 1284 1;
BA_ "FrameGatewayNetwork" BO_ 1126 "HS3_CAN";
BA_ "GenMsgSendType" BO_ 1126 1;
BA_ "GenMsgDelayTime" BO_ 1126 50;
BA_ "EventRateOfChange" BO_ 1126 1000;
BA_ "FrameGatewayId" BO_ 1126 1123;
BA_ "FrameGatewayNetwork" BO_ 1125 "HS3_CAN";
BA_ "GenMsgSendType" BO_ 1125 1;
BA_ "GenMsgDelayTime" BO_ 1125 50;
BA_ "EventRateOfChange" BO_ 1125 1000;
BA_ "FrameGatewayId" BO_ 1125 1122;
BA_ "FrameGatewayNetwork" BO_ 992 "HS3_CAN";
BA_ "FrameGatewayId" BO_ 992 992;
BA_ "FrameGatewayHS3" BO_ 992 992;
BA_ "FrameGatewayNetwork" BO_ 1127 "HS3_CAN";
BA_ "GenMsgSendType" BO_ 1127 1;
BA_ "GenMsgDelayTime" BO_ 1127 50;
BA_ "EventRateOfChange" BO_ 1127 1000;
BA_ "FrameGatewayId" BO_ 1127 1124;
BA_ "GenMsgSendType" BO_ 861 5;
BA_ "GenMsgCycleTime" BO_ 861 1000;
BA_ "GenMsgSendType" BO_ 999 5;
BA_ "GenMsgCycleTime" BO_ 999 1000;
BA_ "GenMsgILSupport" BO_ 1998 0;
BA_ "DiagResponse" BO_ 1998 1;
BA_ "GenMsgSendType" BO_ 1998 1;
BA_ "GenMsgDelayTime" BO_ 1998 0;
BA_ "GenMsgILSupport" BO_ 1990 0;
BA_ "DiagRequest" BO_ 1990 1;
BA_ "GenMsgSendType" BO_ 1990 1;
BA_ "GenMsgDelayTime" BO_ 1990 0;
BA_ "GenMsgILSupport" BO_ 1996 0;
BA_ "DiagResponse" BO_ 1996 1;
BA_ "GenMsgSendType" BO_ 1996 1;
BA_ "GenMsgDelayTime" BO_ 1996 0;
BA_ "GenMsgILSupport" BO_ 1988 0;
BA_ "DiagRequest" BO_ 1988 1;
BA_ "GenMsgSendType" BO_ 1988 1;
BA_ "GenMsgDelayTime" BO_ 1988 0;
BA_ "GenMsgSendType" BO_ 862 5;
BA_ "GenMsgCycleTime" BO_ 862 1000;
BA_ "GenMsgSendType" BO_ 828 5;
BA_ "GenMsgCycleTime" BO_ 828 1000;
BA_ "GenMsgILSupport" BO_ 2000 0;
BA_ "DiagRequest" BO_ 2000 1;
BA_ "GenMsgSendType" BO_ 2000 1;
BA_ "GenMsgDelayTime" BO_ 2000 0;
BA_ "GenMsgILSupport" BO_ 1894 0;
BA_ "DiagRequest" BO_ 1894 1;
BA_ "GenMsgSendType" BO_ 1894 1;
BA_ "GenMsgDelayTime" BO_ 1894 0;
BA_ "GenMsgILSupport" BO_ 1349 0;
BA_ "NmMessage" BO_ 1349 1;
BA_ "GenMsgSendType" BO_ 1349 1;
BA_ "GenMsgILSupport" BO_ 1902 0;
BA_ "DiagResponse" BO_ 1902 1;
BA_ "GenMsgSendType" BO_ 1902 1;
BA_ "GenMsgDelayTime" BO_ 1902 0;
BA_ "GenMsgILSupport" BO_ 1860 0;
BA_ "DiagRequest" BO_ 1860 1;
BA_ "GenMsgSendType" BO_ 1860 1;
BA_ "GenMsgDelayTime" BO_ 1860 0;
BA_ "GenMsgILSupport" BO_ 1868 0;
BA_ "DiagResponse" BO_ 1868 1;
BA_ "GenMsgSendType" BO_ 1868 1;
BA_ "GenMsgDelayTime" BO_ 1868 0;
BA_ "GenMsgILSupport" BO_ 1918 0;
BA_ "DiagResponse" BO_ 1918 1;
BA_ "GenMsgSendType" BO_ 1918 1;
BA_ "GenMsgDelayTime" BO_ 1918 0;
BA_ "GenMsgILSupport" BO_ 1910 0;
BA_ "DiagRequest" BO_ 1910 1;
BA_ "GenMsgSendType" BO_ 1910 1;
BA_ "GenMsgDelayTime" BO_ 1910 0;
BA_ "GenMsgILSupport" BO_ 1814 0;
BA_ "DiagRequest" BO_ 1814 1;
BA_ "GenMsgSendType" BO_ 1814 1;
BA_ "GenMsgDelayTime" BO_ 1814 0;
BA_ "GenMsgILSupport" BO_ 1822 0;
BA_ "DiagResponse" BO_ 1822 1;
BA_ "GenMsgSendType" BO_ 1822 1;
BA_ "GenMsgDelayTime" BO_ 1822 0;
BA_ "GenMsgSendType" BO_ 826 5;
BA_ "GenMsgCycleTime" BO_ 826 100;
BA_ "GenMsgStartDelayTime" BO_ 826 100;
BA_ "GenMsgSendType" BO_ 853 5;
BA_ "GenMsgCycleTime" BO_ 853 1000;
BA_ "FrameGatewayNetwork" BO_ 1034 "HS1_CAN";
BA_ "FrameGatewayId" BO_ 1034 1034;
BA_ "FrameGatewayHS1" BO_ 1034 1034;
BA_ "GenMsgSendType" BO_ 956 0;
BA_ "GenMsgCycleTime" BO_ 956 50;
BA_ "NetworkInitialization" BO_ 956 1;
BA_ "GenMsgSendType" BO_ 831 5;
BA_ "GenMsgCycleTime" BO_ 831 1000;
BA_ "GenMsgILSupport" BO_ 1820 0;
BA_ "DiagResponse" BO_ 1820 1;
BA_ "GenMsgSendType" BO_ 1820 1;
BA_ "GenMsgDelayTime" BO_ 1820 0;
BA_ "GenMsgILSupport" BO_ 1812 0;
BA_ "DiagRequest" BO_ 1812 1;
BA_ "GenMsgSendType" BO_ 1812 1;
BA_ "GenMsgDelayTime" BO_ 1812 0;
BA_ "GenMsgILSupport" BO_ 1291 0;
BA_ "NmMessage" BO_ 1291 1;
BA_ "GenMsgSendType" BO_ 1291 1;
BA_ "GenMsgILSupport" BO_ 1319 0;
BA_ "NmMessage" BO_ 1319 1;
BA_ "GenMsgSendType" BO_ 1319 1;
BA_ "GenMsgILSupport" BO_ 1388 0;
BA_ "NmMessage" BO_ 1388 1;
BA_ "GenMsgSendType" BO_ 1388 1;
BA_ "GenMsgILSupport" BO_ 1801 0;
BA_ "DiagResponse" BO_ 1801 1;
BA_ "GenMsgSendType" BO_ 1801 1;
BA_ "GenMsgDelayTime" BO_ 1801 0;
BA_ "GenMsgILSupport" BO_ 1793 0;
BA_ "DiagRequest" BO_ 1793 1;
BA_ "GenMsgSendType" BO_ 1793 1;
BA_ "GenMsgDelayTime" BO_ 1793 0;
BA_ "GenSigSendType" SG_ 292 ClmtCtrlSeat_SetCmd_Psgr 3;
BA_ "U_CD4_MY13_Diesel_Rx" SG_ 292 ClmtCtrlSeat_SetCmd_Psgr 1;
BA_ "U_CD4_MY13_Gas_Rx" SG_ 292 ClmtCtrlSeat_SetCmd_Psgr 1;
BA_ "U_CD4_MY13_Hev_Rx" SG_ 292 ClmtCtrlSeat_SetCmd_Psgr 1;
BA_ "U_CD4_MY13_Phev_Rx" SG_ 292 ClmtCtrlSeat_SetCmd_Psgr 1;
BA_ "U_CD42_MY14_Diesel_Rx" SG_ 292 ClmtCtrlSeat_SetCmd_Psgr 1;
BA_ "U_CD42_MY14_Gas_Rx" SG_ 292 ClmtCtrlSeat_SetCmd_Psgr 1;
BA_ "U_P552_MY15_Gas_Rx" SG_ 292 ClmtCtrlSeat_SetCmd_Psgr 1;
BA_ "U_S550_MY15_Gas_Rx" SG_ 292 ClmtCtrlSeat_SetCmd_Psgr 1;
BA_ "U_C489_MY14_Gas_Rx" SG_ 292 ClmtCtrlSeat_SetCmd_Psgr 1;
BA_ "U_U502_MY15_Gas_Rx" SG_ 292 ClmtCtrlSeat_SetCmd_Psgr 1;
BA_ "U_CD43_MY16_Gas_Rx" SG_ 292 ClmtCtrlSeat_SetCmd_Psgr 1;
BA_ "U_CD4_MY14_Diesel_Rx" SG_ 292 ClmtCtrlSeat_SetCmd_Psgr 1;
BA_ "U_CD4_MY14_Gas_Rx" SG_ 292 ClmtCtrlSeat_SetCmd_Psgr 1;
BA_ "U_CD4_MY14_Hev_Rx" SG_ 292 ClmtCtrlSeat_SetCmd_Psgr 1;
BA_ "U_CD4_MY14_Phev_Rx" SG_ 292 ClmtCtrlSeat_SetCmd_Psgr 1;
BA_ "U_CD4_MY13_Diesel_Tx" SG_ 292 ClmtCtrlSeat_SetCmd_Psgr 1;
BA_ "U_CD4_MY13_Gas_Tx" SG_ 292 ClmtCtrlSeat_SetCmd_Psgr 1;
BA_ "U_CD4_MY13_Hev_Tx" SG_ 292 ClmtCtrlSeat_SetCmd_Psgr 1;
BA_ "U_CD4_MY13_Phev_Tx" SG_ 292 ClmtCtrlSeat_SetCmd_Psgr 1;
BA_ "U_CD42_MY14_Diesel_Tx" SG_ 292 ClmtCtrlSeat_SetCmd_Psgr 1;
BA_ "U_CD42_MY14_Gas_Tx" SG_ 292 ClmtCtrlSeat_SetCmd_Psgr 1;
BA_ "U_P552_MY15_Gas_Tx" SG_ 292 ClmtCtrlSeat_SetCmd_Psgr 1;
BA_ "U_S550_MY15_Gas_Tx" SG_ 292 ClmtCtrlSeat_SetCmd_Psgr 1;
BA_ "U_C489_MY14_Gas_Tx" SG_ 292 ClmtCtrlSeat_SetCmd_Psgr 1;
BA_ "U_U502_MY15_Gas_Tx" SG_ 292 ClmtCtrlSeat_SetCmd_Psgr 1;
BA_ "U_UP375_MY15_Gas_Tx" SG_ 292 ClmtCtrlSeat_SetCmd_Psgr 1;
BA_ "U_UP375_MY15_Diesel_Tx" SG_ 292 ClmtCtrlSeat_SetCmd_Psgr 1;
BA_ "U_CD43_MY16_Gas_Tx" SG_ 292 ClmtCtrlSeat_SetCmd_Psgr 1;
BA_ "GenSigSendType" SG_ 292 ClmtCtrlSeat_SetCmd_Dvr 3;
BA_ "U_CD4_MY13_Diesel_Rx" SG_ 292 ClmtCtrlSeat_SetCmd_Dvr 1;
BA_ "U_CD4_MY13_Gas_Rx" SG_ 292 ClmtCtrlSeat_SetCmd_Dvr 1;
BA_ "U_CD4_MY13_Hev_Rx" SG_ 292 ClmtCtrlSeat_SetCmd_Dvr 1;
BA_ "U_CD4_MY13_Phev_Rx" SG_ 292 ClmtCtrlSeat_SetCmd_Dvr 1;
BA_ "U_CD42_MY14_Diesel_Rx" SG_ 292 ClmtCtrlSeat_SetCmd_Dvr 1;
BA_ "U_CD42_MY14_Gas_Rx" SG_ 292 ClmtCtrlSeat_SetCmd_Dvr 1;
BA_ "U_P552_MY15_Gas_Rx" SG_ 292 ClmtCtrlSeat_SetCmd_Dvr 1;
BA_ "U_S550_MY15_Gas_Rx" SG_ 292 ClmtCtrlSeat_SetCmd_Dvr 1;
BA_ "U_C489_MY14_Gas_Rx" SG_ 292 ClmtCtrlSeat_SetCmd_Dvr 1;
BA_ "U_U502_MY15_Gas_Rx" SG_ 292 ClmtCtrlSeat_SetCmd_Dvr 1;
BA_ "U_CD43_MY16_Gas_Rx" SG_ 292 ClmtCtrlSeat_SetCmd_Dvr 1;
BA_ "U_CD4_MY14_Diesel_Rx" SG_ 292 ClmtCtrlSeat_SetCmd_Dvr 1;
BA_ "U_CD4_MY14_Gas_Rx" SG_ 292 ClmtCtrlSeat_SetCmd_Dvr 1;
BA_ "U_CD4_MY14_Hev_Rx" SG_ 292 ClmtCtrlSeat_SetCmd_Dvr 1;
BA_ "U_CD4_MY14_Phev_Rx" SG_ 292 ClmtCtrlSeat_SetCmd_Dvr 1;
BA_ "U_CD4_MY13_Diesel_Tx" SG_ 292 ClmtCtrlSeat_SetCmd_Dvr 1;
BA_ "U_CD4_MY13_Gas_Tx" SG_ 292 ClmtCtrlSeat_SetCmd_Dvr 1;
BA_ "U_CD4_MY13_Hev_Tx" SG_ 292 ClmtCtrlSeat_SetCmd_Dvr 1;
BA_ "U_CD4_MY13_Phev_Tx" SG_ 292 ClmtCtrlSeat_SetCmd_Dvr 1;
BA_ "U_CD42_MY14_Diesel_Tx" SG_ 292 ClmtCtrlSeat_SetCmd_Dvr 1;
BA_ "U_CD42_MY14_Gas_Tx" SG_ 292 ClmtCtrlSeat_SetCmd_Dvr 1;
BA_ "U_P552_MY15_Gas_Tx" SG_ 292 ClmtCtrlSeat_SetCmd_Dvr 1;
BA_ "U_S550_MY15_Gas_Tx" SG_ 292 ClmtCtrlSeat_SetCmd_Dvr 1;
BA_ "U_C489_MY14_Gas_Tx" SG_ 292 ClmtCtrlSeat_SetCmd_Dvr 1;
BA_ "U_U502_MY15_Gas_Tx" SG_ 292 ClmtCtrlSeat_SetCmd_Dvr 1;
BA_ "U_UP375_MY15_Gas_Tx" SG_ 292 ClmtCtrlSeat_SetCmd_Dvr 1;
BA_ "U_UP375_MY15_Diesel_Tx" SG_ 292 ClmtCtrlSeat_SetCmd_Dvr 1;
BA_ "U_CD43_MY16_Gas_Tx" SG_ 292 ClmtCtrlSeat_SetCmd_Dvr 1;
BA_ "GenSigSendType" SG_ 1284 DDM_Network_Mgmt 3;
BA_ "U_CD4_MY13_Diesel_Rx" SG_ 1284 DDM_Network_Mgmt 1;
BA_ "U_CD4_MY13_Gas_Rx" SG_ 1284 DDM_Network_Mgmt 1;
BA_ "U_CD4_MY13_Hev_Rx" SG_ 1284 DDM_Network_Mgmt 1;
BA_ "U_CD4_MY13_Phev_Rx" SG_ 1284 DDM_Network_Mgmt 1;
BA_ "U_CD42_MY14_Diesel_Rx" SG_ 1284 DDM_Network_Mgmt 1;
BA_ "U_CD42_MY14_Gas_Rx" SG_ 1284 DDM_Network_Mgmt 1;
BA_ "U_P552_MY15_Gas_Rx" SG_ 1284 DDM_Network_Mgmt 1;
BA_ "U_S550_MY15_Gas_Rx" SG_ 1284 DDM_Network_Mgmt 1;
BA_ "U_C489_MY14_Gas_Rx" SG_ 1284 DDM_Network_Mgmt 1;
BA_ "U_U502_MY15_Gas_Rx" SG_ 1284 DDM_Network_Mgmt 1;
BA_ "U_UP375_MY15_Gas_Rx" SG_ 1284 DDM_Network_Mgmt 1;
BA_ "U_UP375_MY15_Diesel_Rx" SG_ 1284 DDM_Network_Mgmt 1;
BA_ "U_CD43_MY16_Gas_Rx" SG_ 1284 DDM_Network_Mgmt 1;
BA_ "U_CD4_MY14_Diesel_Rx" SG_ 1284 DDM_Network_Mgmt 1;
BA_ "U_CD4_MY14_Gas_Rx" SG_ 1284 DDM_Network_Mgmt 1;
BA_ "U_CD4_MY14_Hev_Rx" SG_ 1284 DDM_Network_Mgmt 1;
BA_ "U_CD4_MY14_Phev_Rx" SG_ 1284 DDM_Network_Mgmt 1;
BA_ "U_CD4_MY13_Diesel_Tx" SG_ 1284 DDM_Network_Mgmt 1;
BA_ "U_CD4_MY13_Gas_Tx" SG_ 1284 DDM_Network_Mgmt 1;
BA_ "U_CD4_MY13_Hev_Tx" SG_ 1284 DDM_Network_Mgmt 1;
BA_ "U_CD4_MY13_Phev_Tx" SG_ 1284 DDM_Network_Mgmt 1;
BA_ "U_CD42_MY14_Diesel_Tx" SG_ 1284 DDM_Network_Mgmt 1;
BA_ "U_CD42_MY14_Gas_Tx" SG_ 1284 DDM_Network_Mgmt 1;
BA_ "U_P552_MY15_Gas_Tx" SG_ 1284 DDM_Network_Mgmt 1;
BA_ "U_S550_MY15_Gas_Tx" SG_ 1284 DDM_Network_Mgmt 1;
BA_ "U_C489_MY14_Gas_Tx" SG_ 1284 DDM_Network_Mgmt 1;
BA_ "U_U502_MY15_Gas_Tx" SG_ 1284 DDM_Network_Mgmt 1;
BA_ "U_UP375_MY15_Gas_Tx" SG_ 1284 DDM_Network_Mgmt 1;
BA_ "U_UP375_MY15_Diesel_Tx" SG_ 1284 DDM_Network_Mgmt 1;
BA_ "U_CD43_MY16_Gas_Tx" SG_ 1284 DDM_Network_Mgmt 1;
BA_ "U_CD4_MY14_Diesel_Tx" SG_ 1284 DDM_Network_Mgmt 1;
BA_ "U_CD4_MY14_Gas_Tx" SG_ 1284 DDM_Network_Mgmt 1;
BA_ "U_CD4_MY14_Hev_Tx" SG_ 1284 DDM_Network_Mgmt 1;
BA_ "U_CD4_MY14_Phev_Tx" SG_ 1284 DDM_Network_Mgmt 1;
BA_ "CrossOver_InfoCAN" SG_ 1126 GpsUtcYr_No_Actl 1;
BA_ "U_CD4_MY13_Diesel_Rx" SG_ 1126 GpsUtcYr_No_Actl 1;
BA_ "U_CD4_MY13_Gas_Rx" SG_ 1126 GpsUtcYr_No_Actl 1;
BA_ "U_CD4_MY13_Hev_Rx" SG_ 1126 GpsUtcYr_No_Actl 1;
BA_ "U_CD4_MY13_Phev_Rx" SG_ 1126 GpsUtcYr_No_Actl 1;
BA_ "U_CD42_MY14_Diesel_Rx" SG_ 1126 GpsUtcYr_No_Actl 1;
BA_ "U_CD42_MY14_Gas_Rx" SG_ 1126 GpsUtcYr_No_Actl 1;
BA_ "U_P552_MY15_Gas_Rx" SG_ 1126 GpsUtcYr_No_Actl 1;
BA_ "U_S550_MY15_Gas_Rx" SG_ 1126 GpsUtcYr_No_Actl 1;
BA_ "U_C489_MY14_Gas_Rx" SG_ 1126 GpsUtcYr_No_Actl 1;
BA_ "U_U502_MY15_Gas_Rx" SG_ 1126 GpsUtcYr_No_Actl 1;
BA_ "U_UP375_MY15_Gas_Rx" SG_ 1126 GpsUtcYr_No_Actl 1;
BA_ "U_UP375_MY15_Diesel_Rx" SG_ 1126 GpsUtcYr_No_Actl 1;
BA_ "U_CD43_MY16_Gas_Rx" SG_ 1126 GpsUtcYr_No_Actl 1;
BA_ "U_CD4_MY14_Diesel_Rx" SG_ 1126 GpsUtcYr_No_Actl 1;
BA_ "U_CD4_MY14_Gas_Rx" SG_ 1126 GpsUtcYr_No_Actl 1;
BA_ "U_CD4_MY14_Hev_Rx" SG_ 1126 GpsUtcYr_No_Actl 1;
BA_ "U_CD4_MY14_Phev_Rx" SG_ 1126 GpsUtcYr_No_Actl 1;
BA_ "U_CD4_MY13_Diesel_Tx" SG_ 1126 GpsUtcYr_No_Actl 1;
BA_ "U_CD4_MY13_Gas_Tx" SG_ 1126 GpsUtcYr_No_Actl 1;
BA_ "U_CD4_MY13_Hev_Tx" SG_ 1126 GpsUtcYr_No_Actl 1;
BA_ "U_CD4_MY13_Phev_Tx" SG_ 1126 GpsUtcYr_No_Actl 1;
BA_ "U_CD42_MY14_Diesel_Tx" SG_ 1126 GpsUtcYr_No_Actl 1;
BA_ "U_CD42_MY14_Gas_Tx" SG_ 1126 GpsUtcYr_No_Actl 1;
BA_ "U_P552_MY15_Gas_Tx" SG_ 1126 GpsUtcYr_No_Actl 1;
BA_ "U_S550_MY15_Gas_Tx" SG_ 1126 GpsUtcYr_No_Actl 1;
BA_ "U_C489_MY14_Gas_Tx" SG_ 1126 GpsUtcYr_No_Actl 1;
BA_ "U_U502_MY15_Gas_Tx" SG_ 1126 GpsUtcYr_No_Actl 1;
BA_ "U_UP375_MY15_Gas_Tx" SG_ 1126 GpsUtcYr_No_Actl 1;
BA_ "U_UP375_MY15_Diesel_Tx" SG_ 1126 GpsUtcYr_No_Actl 1;
BA_ "U_CD43_MY16_Gas_Tx" SG_ 1126 GpsUtcYr_No_Actl 1;
BA_ "CrossOver_InfoCAN" SG_ 1126 GpsUtcMnth_No_Actl 1;
BA_ "U_CD4_MY13_Diesel_Rx" SG_ 1126 GpsUtcMnth_No_Actl 1;
BA_ "U_CD4_MY13_Gas_Rx" SG_ 1126 GpsUtcMnth_No_Actl 1;
BA_ "U_CD4_MY13_Hev_Rx" SG_ 1126 GpsUtcMnth_No_Actl 1;
BA_ "U_CD4_MY13_Phev_Rx" SG_ 1126 GpsUtcMnth_No_Actl 1;
BA_ "U_CD42_MY14_Diesel_Rx" SG_ 1126 GpsUtcMnth_No_Actl 1;
BA_ "U_CD42_MY14_Gas_Rx" SG_ 1126 GpsUtcMnth_No_Actl 1;
BA_ "U_P552_MY15_Gas_Rx" SG_ 1126 GpsUtcMnth_No_Actl 1;
BA_ "U_S550_MY15_Gas_Rx" SG_ 1126 GpsUtcMnth_No_Actl 1;
BA_ "U_C489_MY14_Gas_Rx" SG_ 1126 GpsUtcMnth_No_Actl 1;
BA_ "U_U502_MY15_Gas_Rx" SG_ 1126 GpsUtcMnth_No_Actl 1;
BA_ "U_UP375_MY15_Gas_Rx" SG_ 1126 GpsUtcMnth_No_Actl 1;
BA_ "U_UP375_MY15_Diesel_Rx" SG_ 1126 GpsUtcMnth_No_Actl 1;
BA_ "U_CD43_MY16_Gas_Rx" SG_ 1126 GpsUtcMnth_No_Actl 1;
BA_ "U_CD4_MY14_Diesel_Rx" SG_ 1126 GpsUtcMnth_No_Actl 1;
BA_ "U_CD4_MY14_Gas_Rx" SG_ 1126 GpsUtcMnth_No_Actl 1;
BA_ "U_CD4_MY14_Hev_Rx" SG_ 1126 GpsUtcMnth_No_Actl 1;
BA_ "U_CD4_MY14_Phev_Rx" SG_ 1126 GpsUtcMnth_No_Actl 1;
BA_ "U_CD4_MY13_Diesel_Tx" SG_ 1126 GpsUtcMnth_No_Actl 1;
BA_ "U_CD4_MY13_Gas_Tx" SG_ 1126 GpsUtcMnth_No_Actl 1;
BA_ "U_CD4_MY13_Hev_Tx" SG_ 1126 GpsUtcMnth_No_Actl 1;
BA_ "U_CD4_MY13_Phev_Tx" SG_ 1126 GpsUtcMnth_No_Actl 1;
BA_ "U_CD42_MY14_Diesel_Tx" SG_ 1126 GpsUtcMnth_No_Actl 1;
BA_ "U_CD42_MY14_Gas_Tx" SG_ 1126 GpsUtcMnth_No_Actl 1;
BA_ "U_P552_MY15_Gas_Tx" SG_ 1126 GpsUtcMnth_No_Actl 1;
BA_ "U_S550_MY15_Gas_Tx" SG_ 1126 GpsUtcMnth_No_Actl 1;
BA_ "U_C489_MY14_Gas_Tx" SG_ 1126 GpsUtcMnth_No_Actl 1;
BA_ "U_U502_MY15_Gas_Tx" SG_ 1126 GpsUtcMnth_No_Actl 1;
BA_ "U_UP375_MY15_Gas_Tx" SG_ 1126 GpsUtcMnth_No_Actl 1;
BA_ "U_UP375_MY15_Diesel_Tx" SG_ 1126 GpsUtcMnth_No_Actl 1;
BA_ "U_CD43_MY16_Gas_Tx" SG_ 1126 GpsUtcMnth_No_Actl 1;
BA_ "CrossOver_InfoCAN" SG_ 1126 GpsUtcDay_No_Actl 1;
BA_ "U_CD4_MY13_Diesel_Rx" SG_ 1126 GpsUtcDay_No_Actl 1;
BA_ "U_CD4_MY13_Gas_Rx" SG_ 1126 GpsUtcDay_No_Actl 1;
BA_ "U_CD4_MY13_Hev_Rx" SG_ 1126 GpsUtcDay_No_Actl 1;
BA_ "U_CD4_MY13_Phev_Rx" SG_ 1126 GpsUtcDay_No_Actl 1;
BA_ "U_CD42_MY14_Diesel_Rx" SG_ 1126 GpsUtcDay_No_Actl 1;
BA_ "U_CD42_MY14_Gas_Rx" SG_ 1126 GpsUtcDay_No_Actl 1;
BA_ "U_P552_MY15_Gas_Rx" SG_ 1126 GpsUtcDay_No_Actl 1;
BA_ "U_S550_MY15_Gas_Rx" SG_ 1126 GpsUtcDay_No_Actl 1;
BA_ "U_C489_MY14_Gas_Rx" SG_ 1126 GpsUtcDay_No_Actl 1;
BA_ "U_U502_MY15_Gas_Rx" SG_ 1126 GpsUtcDay_No_Actl 1;
BA_ "U_UP375_MY15_Gas_Rx" SG_ 1126 GpsUtcDay_No_Actl 1;
BA_ "U_UP375_MY15_Diesel_Rx" SG_ 1126 GpsUtcDay_No_Actl 1;
BA_ "U_CD43_MY16_Gas_Rx" SG_ 1126 GpsUtcDay_No_Actl 1;
BA_ "U_CD4_MY14_Diesel_Rx" SG_ 1126 GpsUtcDay_No_Actl 1;
BA_ "U_CD4_MY14_Gas_Rx" SG_ 1126 GpsUtcDay_No_Actl 1;
BA_ "U_CD4_MY14_Hev_Rx" SG_ 1126 GpsUtcDay_No_Actl 1;
BA_ "U_CD4_MY14_Phev_Rx" SG_ 1126 GpsUtcDay_No_Actl 1;
BA_ "U_CD4_MY13_Diesel_Tx" SG_ 1126 GpsUtcDay_No_Actl 1;
BA_ "U_CD4_MY13_Gas_Tx" SG_ 1126 GpsUtcDay_No_Actl 1;
BA_ "U_CD4_MY13_Hev_Tx" SG_ 1126 GpsUtcDay_No_Actl 1;
BA_ "U_CD4_MY13_Phev_Tx" SG_ 1126 GpsUtcDay_No_Actl 1;
BA_ "U_CD42_MY14_Diesel_Tx" SG_ 1126 GpsUtcDay_No_Actl 1;
BA_ "U_CD42_MY14_Gas_Tx" SG_ 1126 GpsUtcDay_No_Actl 1;
BA_ "U_P552_MY15_Gas_Tx" SG_ 1126 GpsUtcDay_No_Actl 1;
BA_ "U_S550_MY15_Gas_Tx" SG_ 1126 GpsUtcDay_No_Actl 1;
BA_ "U_C489_MY14_Gas_Tx" SG_ 1126 GpsUtcDay_No_Actl 1;
BA_ "U_U502_MY15_Gas_Tx" SG_ 1126 GpsUtcDay_No_Actl 1;
BA_ "U_UP375_MY15_Gas_Tx" SG_ 1126 GpsUtcDay_No_Actl 1;
BA_ "U_UP375_MY15_Diesel_Tx" SG_ 1126 GpsUtcDay_No_Actl 1;
BA_ "U_CD43_MY16_Gas_Tx" SG_ 1126 GpsUtcDay_No_Actl 1;
BA_ "CrossOver_InfoCAN" SG_ 1126 GPS_UTC_seconds 1;
BA_ "U_CD4_MY13_Diesel_Rx" SG_ 1126 GPS_UTC_seconds 1;
BA_ "U_CD4_MY13_Gas_Rx" SG_ 1126 GPS_UTC_seconds 1;
BA_ "U_CD4_MY13_Hev_Rx" SG_ 1126 GPS_UTC_seconds 1;
BA_ "U_CD4_MY13_Phev_Rx" SG_ 1126 GPS_UTC_seconds 1;
BA_ "U_CD42_MY14_Diesel_Rx" SG_ 1126 GPS_UTC_seconds 1;
BA_ "U_CD42_MY14_Gas_Rx" SG_ 1126 GPS_UTC_seconds 1;
BA_ "U_P552_MY15_Gas_Rx" SG_ 1126 GPS_UTC_seconds 1;
BA_ "U_S550_MY15_Gas_Rx" SG_ 1126 GPS_UTC_seconds 1;
BA_ "U_C489_MY14_Gas_Rx" SG_ 1126 GPS_UTC_seconds 1;
BA_ "U_U502_MY15_Gas_Rx" SG_ 1126 GPS_UTC_seconds 1;
BA_ "U_UP375_MY15_Gas_Rx" SG_ 1126 GPS_UTC_seconds 1;
BA_ "U_UP375_MY15_Diesel_Rx" SG_ 1126 GPS_UTC_seconds 1;
BA_ "U_CD43_MY16_Gas_Rx" SG_ 1126 GPS_UTC_seconds 1;
BA_ "U_CD4_MY14_Diesel_Rx" SG_ 1126 GPS_UTC_seconds 1;
BA_ "U_CD4_MY14_Gas_Rx" SG_ 1126 GPS_UTC_seconds 1;
BA_ "U_CD4_MY14_Hev_Rx" SG_ 1126 GPS_UTC_seconds 1;
BA_ "U_CD4_MY14_Phev_Rx" SG_ 1126 GPS_UTC_seconds 1;
BA_ "U_CD4_MY13_Diesel_Tx" SG_ 1126 GPS_UTC_seconds 1;
BA_ "U_CD4_MY13_Gas_Tx" SG_ 1126 GPS_UTC_seconds 1;
BA_ "U_CD4_MY13_Hev_Tx" SG_ 1126 GPS_UTC_seconds 1;
BA_ "U_CD4_MY13_Phev_Tx" SG_ 1126 GPS_UTC_seconds 1;
BA_ "U_CD42_MY14_Diesel_Tx" SG_ 1126 GPS_UTC_seconds 1;
BA_ "U_CD42_MY14_Gas_Tx" SG_ 1126 GPS_UTC_seconds 1;
BA_ "U_P552_MY15_Gas_Tx" SG_ 1126 GPS_UTC_seconds 1;
BA_ "U_S550_MY15_Gas_Tx" SG_ 1126 GPS_UTC_seconds 1;
BA_ "U_C489_MY14_Gas_Tx" SG_ 1126 GPS_UTC_seconds 1;
BA_ "U_U502_MY15_Gas_Tx" SG_ 1126 GPS_UTC_seconds 1;
BA_ "U_UP375_MY15_Gas_Tx" SG_ 1126 GPS_UTC_seconds 1;
BA_ "U_UP375_MY15_Diesel_Tx" SG_ 1126 GPS_UTC_seconds 1;
BA_ "U_CD43_MY16_Gas_Tx" SG_ 1126 GPS_UTC_seconds 1;
BA_ "CrossOver_InfoCAN" SG_ 1126 GPS_UTC_minutes 1;
BA_ "U_CD4_MY13_Diesel_Rx" SG_ 1126 GPS_UTC_minutes 1;
BA_ "U_CD4_MY13_Gas_Rx" SG_ 1126 GPS_UTC_minutes 1;
BA_ "U_CD4_MY13_Hev_Rx" SG_ 1126 GPS_UTC_minutes 1;
BA_ "U_CD4_MY13_Phev_Rx" SG_ 1126 GPS_UTC_minutes 1;
BA_ "U_CD42_MY14_Diesel_Rx" SG_ 1126 GPS_UTC_minutes 1;
BA_ "U_CD42_MY14_Gas_Rx" SG_ 1126 GPS_UTC_minutes 1;
BA_ "U_P552_MY15_Gas_Rx" SG_ 1126 GPS_UTC_minutes 1;
BA_ "U_S550_MY15_Gas_Rx" SG_ 1126 GPS_UTC_minutes 1;
BA_ "U_C489_MY14_Gas_Rx" SG_ 1126 GPS_UTC_minutes 1;
BA_ "U_U502_MY15_Gas_Rx" SG_ 1126 GPS_UTC_minutes 1;
BA_ "U_UP375_MY15_Gas_Rx" SG_ 1126 GPS_UTC_minutes 1;
BA_ "U_UP375_MY15_Diesel_Rx" SG_ 1126 GPS_UTC_minutes 1;
BA_ "U_CD43_MY16_Gas_Rx" SG_ 1126 GPS_UTC_minutes 1;
BA_ "U_CD4_MY14_Diesel_Rx" SG_ 1126 GPS_UTC_minutes 1;
BA_ "U_CD4_MY14_Gas_Rx" SG_ 1126 GPS_UTC_minutes 1;
BA_ "U_CD4_MY14_Hev_Rx" SG_ 1126 GPS_UTC_minutes 1;
BA_ "U_CD4_MY14_Phev_Rx" SG_ 1126 GPS_UTC_minutes 1;
BA_ "U_CD4_MY13_Diesel_Tx" SG_ 1126 GPS_UTC_minutes 1;
BA_ "U_CD4_MY13_Gas_Tx" SG_ 1126 GPS_UTC_minutes 1;
BA_ "U_CD4_MY13_Hev_Tx" SG_ 1126 GPS_UTC_minutes 1;
BA_ "U_CD4_MY13_Phev_Tx" SG_ 1126 GPS_UTC_minutes 1;
BA_ "U_CD42_MY14_Diesel_Tx" SG_ 1126 GPS_UTC_minutes 1;
BA_ "U_CD42_MY14_Gas_Tx" SG_ 1126 GPS_UTC_minutes 1;
BA_ "U_P552_MY15_Gas_Tx" SG_ 1126 GPS_UTC_minutes 1;
BA_ "U_S550_MY15_Gas_Tx" SG_ 1126 GPS_UTC_minutes 1;
BA_ "U_C489_MY14_Gas_Tx" SG_ 1126 GPS_UTC_minutes 1;
BA_ "U_U502_MY15_Gas_Tx" SG_ 1126 GPS_UTC_minutes 1;
BA_ "U_UP375_MY15_Gas_Tx" SG_ 1126 GPS_UTC_minutes 1;
BA_ "U_UP375_MY15_Diesel_Tx" SG_ 1126 GPS_UTC_minutes 1;
BA_ "U_CD43_MY16_Gas_Tx" SG_ 1126 GPS_UTC_minutes 1;
BA_ "CrossOver_InfoCAN" SG_ 1126 GPS_UTC_hours 1;
BA_ "U_CD4_MY13_Diesel_Rx" SG_ 1126 GPS_UTC_hours 1;
BA_ "U_CD4_MY13_Gas_Rx" SG_ 1126 GPS_UTC_hours 1;
BA_ "U_CD4_MY13_Hev_Rx" SG_ 1126 GPS_UTC_hours 1;
BA_ "U_CD4_MY13_Phev_Rx" SG_ 1126 GPS_UTC_hours 1;
BA_ "U_CD42_MY14_Diesel_Rx" SG_ 1126 GPS_UTC_hours 1;
BA_ "U_CD42_MY14_Gas_Rx" SG_ 1126 GPS_UTC_hours 1;
BA_ "U_P552_MY15_Gas_Rx" SG_ 1126 GPS_UTC_hours 1;
BA_ "U_S550_MY15_Gas_Rx" SG_ 1126 GPS_UTC_hours 1;
BA_ "U_C489_MY14_Gas_Rx" SG_ 1126 GPS_UTC_hours 1;
BA_ "U_U502_MY15_Gas_Rx" SG_ 1126 GPS_UTC_hours 1;
BA_ "U_UP375_MY15_Gas_Rx" SG_ 1126 GPS_UTC_hours 1;
BA_ "U_UP375_MY15_Diesel_Rx" SG_ 1126 GPS_UTC_hours 1;
BA_ "U_CD43_MY16_Gas_Rx" SG_ 1126 GPS_UTC_hours 1;
BA_ "U_CD4_MY14_Diesel_Rx" SG_ 1126 GPS_UTC_hours 1;
BA_ "U_CD4_MY14_Gas_Rx" SG_ 1126 GPS_UTC_hours 1;
BA_ "U_CD4_MY14_Hev_Rx" SG_ 1126 GPS_UTC_hours 1;
BA_ "U_CD4_MY14_Phev_Rx" SG_ 1126 GPS_UTC_hours 1;
BA_ "U_CD4_MY13_Diesel_Tx" SG_ 1126 GPS_UTC_hours 1;
BA_ "U_CD4_MY13_Gas_Tx" SG_ 1126 GPS_UTC_hours 1;
BA_ "U_CD4_MY13_Hev_Tx" SG_ 1126 GPS_UTC_hours 1;
BA_ "U_CD4_MY13_Phev_Tx" SG_ 1126 GPS_UTC_hours 1;
BA_ "U_CD42_MY14_Diesel_Tx" SG_ 1126 GPS_UTC_hours 1;
BA_ "U_CD42_MY14_Gas_Tx" SG_ 1126 GPS_UTC_hours 1;
BA_ "U_P552_MY15_Gas_Tx" SG_ 1126 GPS_UTC_hours 1;
BA_ "U_S550_MY15_Gas_Tx" SG_ 1126 GPS_UTC_hours 1;
BA_ "U_C489_MY14_Gas_Tx" SG_ 1126 GPS_UTC_hours 1;
BA_ "U_U502_MY15_Gas_Tx" SG_ 1126 GPS_UTC_hours 1;
BA_ "U_UP375_MY15_Gas_Tx" SG_ 1126 GPS_UTC_hours 1;
BA_ "U_UP375_MY15_Diesel_Tx" SG_ 1126 GPS_UTC_hours 1;
BA_ "U_CD43_MY16_Gas_Tx" SG_ 1126 GPS_UTC_hours 1;
BA_ "CrossOver_InfoCAN" SG_ 1126 GPS_Pdop 1;
BA_ "U_CD4_MY13_Diesel_Rx" SG_ 1126 GPS_Pdop 1;
BA_ "U_CD4_MY13_Gas_Rx" SG_ 1126 GPS_Pdop 1;
BA_ "U_CD4_MY13_Hev_Rx" SG_ 1126 GPS_Pdop 1;
BA_ "U_CD4_MY13_Phev_Rx" SG_ 1126 GPS_Pdop 1;
BA_ "U_CD42_MY14_Diesel_Rx" SG_ 1126 GPS_Pdop 1;
BA_ "U_CD42_MY14_Gas_Rx" SG_ 1126 GPS_Pdop 1;
BA_ "U_P552_MY15_Gas_Rx" SG_ 1126 GPS_Pdop 1;
BA_ "U_S550_MY15_Gas_Rx" SG_ 1126 GPS_Pdop 1;
BA_ "U_C489_MY14_Gas_Rx" SG_ 1126 GPS_Pdop 1;
BA_ "U_U502_MY15_Gas_Rx" SG_ 1126 GPS_Pdop 1;
BA_ "U_UP375_MY15_Gas_Rx" SG_ 1126 GPS_Pdop 1;
BA_ "U_UP375_MY15_Diesel_Rx" SG_ 1126 GPS_Pdop 1;
BA_ "U_CD43_MY16_Gas_Rx" SG_ 1126 GPS_Pdop 1;
BA_ "U_CD4_MY14_Diesel_Rx" SG_ 1126 GPS_Pdop 1;
BA_ "U_CD4_MY14_Gas_Rx" SG_ 1126 GPS_Pdop 1;
BA_ "U_CD4_MY14_Hev_Rx" SG_ 1126 GPS_Pdop 1;
BA_ "U_CD4_MY14_Phev_Rx" SG_ 1126 GPS_Pdop 1;
BA_ "U_CD4_MY13_Diesel_Tx" SG_ 1126 GPS_Pdop 1;
BA_ "U_CD4_MY13_Gas_Tx" SG_ 1126 GPS_Pdop 1;
BA_ "U_CD4_MY13_Hev_Tx" SG_ 1126 GPS_Pdop 1;
BA_ "U_CD4_MY13_Phev_Tx" SG_ 1126 GPS_Pdop 1;
BA_ "U_CD42_MY14_Diesel_Tx" SG_ 1126 GPS_Pdop 1;
BA_ "U_CD42_MY14_Gas_Tx" SG_ 1126 GPS_Pdop 1;
BA_ "U_P552_MY15_Gas_Tx" SG_ 1126 GPS_Pdop 1;
BA_ "U_S550_MY15_Gas_Tx" SG_ 1126 GPS_Pdop 1;
BA_ "U_C489_MY14_Gas_Tx" SG_ 1126 GPS_Pdop 1;
BA_ "U_U502_MY15_Gas_Tx" SG_ 1126 GPS_Pdop 1;
BA_ "U_UP375_MY15_Gas_Tx" SG_ 1126 GPS_Pdop 1;
BA_ "U_UP375_MY15_Diesel_Tx" SG_ 1126 GPS_Pdop 1;
BA_ "U_CD43_MY16_Gas_Tx" SG_ 1126 GPS_Pdop 1;
BA_ "CrossOver_InfoCAN" SG_ 1126 GPS_Compass_direction 1;
BA_ "U_CD4_MY13_Diesel_Rx" SG_ 1126 GPS_Compass_direction 1;
BA_ "U_CD4_MY13_Gas_Rx" SG_ 1126 GPS_Compass_direction 1;
BA_ "U_CD4_MY13_Hev_Rx" SG_ 1126 GPS_Compass_direction 1;
BA_ "U_CD4_MY13_Phev_Rx" SG_ 1126 GPS_Compass_direction 1;
BA_ "U_CD42_MY14_Diesel_Rx" SG_ 1126 GPS_Compass_direction 1;
BA_ "U_CD42_MY14_Gas_Rx" SG_ 1126 GPS_Compass_direction 1;
BA_ "U_P552_MY15_Gas_Rx" SG_ 1126 GPS_Compass_direction 1;
BA_ "U_S550_MY15_Gas_Rx" SG_ 1126 GPS_Compass_direction 1;
BA_ "U_C489_MY14_Gas_Rx" SG_ 1126 GPS_Compass_direction 1;
BA_ "U_U502_MY15_Gas_Rx" SG_ 1126 GPS_Compass_direction 1;
BA_ "U_UP375_MY15_Gas_Rx" SG_ 1126 GPS_Compass_direction 1;
BA_ "U_UP375_MY15_Diesel_Rx" SG_ 1126 GPS_Compass_direction 1;
BA_ "U_CD43_MY16_Gas_Rx" SG_ 1126 GPS_Compass_direction 1;
BA_ "U_CD4_MY14_Diesel_Rx" SG_ 1126 GPS_Compass_direction 1;
BA_ "U_CD4_MY14_Gas_Rx" SG_ 1126 GPS_Compass_direction 1;
BA_ "U_CD4_MY14_Hev_Rx" SG_ 1126 GPS_Compass_direction 1;
BA_ "U_CD4_MY14_Phev_Rx" SG_ 1126 GPS_Compass_direction 1;
BA_ "U_CD4_MY13_Diesel_Tx" SG_ 1126 GPS_Compass_direction 1;
BA_ "U_CD4_MY13_Gas_Tx" SG_ 1126 GPS_Compass_direction 1;
BA_ "U_CD4_MY13_Hev_Tx" SG_ 1126 GPS_Compass_direction 1;
BA_ "U_CD4_MY13_Phev_Tx" SG_ 1126 GPS_Compass_direction 1;
BA_ "U_CD42_MY14_Diesel_Tx" SG_ 1126 GPS_Compass_direction 1;
BA_ "U_CD42_MY14_Gas_Tx" SG_ 1126 GPS_Compass_direction 1;
BA_ "U_P552_MY15_Gas_Tx" SG_ 1126 GPS_Compass_direction 1;
BA_ "U_S550_MY15_Gas_Tx" SG_ 1126 GPS_Compass_direction 1;
BA_ "U_C489_MY14_Gas_Tx" SG_ 1126 GPS_Compass_direction 1;
BA_ "U_U502_MY15_Gas_Tx" SG_ 1126 GPS_Compass_direction 1;
BA_ "U_UP375_MY15_Gas_Tx" SG_ 1126 GPS_Compass_direction 1;
BA_ "U_UP375_MY15_Diesel_Tx" SG_ 1126 GPS_Compass_direction 1;
BA_ "U_CD43_MY16_Gas_Tx" SG_ 1126 GPS_Compass_direction 1;
BA_ "CrossOver_InfoCAN" SG_ 1126 GPS_Actual_vs_Infer_pos 1;
BA_ "GenSigSendType" SG_ 1126 GPS_Actual_vs_Infer_pos 1;
BA_ "U_CD4_MY13_Diesel_Rx" SG_ 1126 GPS_Actual_vs_Infer_pos 1;
BA_ "U_CD4_MY13_Gas_Rx" SG_ 1126 GPS_Actual_vs_Infer_pos 1;
BA_ "U_CD4_MY13_Hev_Rx" SG_ 1126 GPS_Actual_vs_Infer_pos 1;
BA_ "U_CD4_MY13_Phev_Rx" SG_ 1126 GPS_Actual_vs_Infer_pos 1;
BA_ "U_CD42_MY14_Diesel_Rx" SG_ 1126 GPS_Actual_vs_Infer_pos 1;
BA_ "U_CD42_MY14_Gas_Rx" SG_ 1126 GPS_Actual_vs_Infer_pos 1;
BA_ "U_P552_MY15_Gas_Rx" SG_ 1126 GPS_Actual_vs_Infer_pos 1;
BA_ "U_S550_MY15_Gas_Rx" SG_ 1126 GPS_Actual_vs_Infer_pos 1;
BA_ "U_C489_MY14_Gas_Rx" SG_ 1126 GPS_Actual_vs_Infer_pos 1;
BA_ "U_U502_MY15_Gas_Rx" SG_ 1126 GPS_Actual_vs_Infer_pos 1;
BA_ "U_UP375_MY15_Gas_Rx" SG_ 1126 GPS_Actual_vs_Infer_pos 1;
BA_ "U_UP375_MY15_Diesel_Rx" SG_ 1126 GPS_Actual_vs_Infer_pos 1;
BA_ "U_CD43_MY16_Gas_Rx" SG_ 1126 GPS_Actual_vs_Infer_pos 1;
BA_ "U_CD4_MY14_Diesel_Rx" SG_ 1126 GPS_Actual_vs_Infer_pos 1;
BA_ "U_CD4_MY14_Gas_Rx" SG_ 1126 GPS_Actual_vs_Infer_pos 1;
BA_ "U_CD4_MY14_Hev_Rx" SG_ 1126 GPS_Actual_vs_Infer_pos 1;
BA_ "U_CD4_MY14_Phev_Rx" SG_ 1126 GPS_Actual_vs_Infer_pos 1;
BA_ "U_CD4_MY13_Diesel_Tx" SG_ 1126 GPS_Actual_vs_Infer_pos 1;
BA_ "U_CD4_MY13_Gas_Tx" SG_ 1126 GPS_Actual_vs_Infer_pos 1;
BA_ "U_CD4_MY13_Hev_Tx" SG_ 1126 GPS_Actual_vs_Infer_pos 1;
BA_ "U_CD4_MY13_Phev_Tx" SG_ 1126 GPS_Actual_vs_Infer_pos 1;
BA_ "U_CD42_MY14_Diesel_Tx" SG_ 1126 GPS_Actual_vs_Infer_pos 1;
BA_ "U_CD42_MY14_Gas_Tx" SG_ 1126 GPS_Actual_vs_Infer_pos 1;
BA_ "U_P552_MY15_Gas_Tx" SG_ 1126 GPS_Actual_vs_Infer_pos 1;
BA_ "U_S550_MY15_Gas_Tx" SG_ 1126 GPS_Actual_vs_Infer_pos 1;
BA_ "U_C489_MY14_Gas_Tx" SG_ 1126 GPS_Actual_vs_Infer_pos 1;
BA_ "U_U502_MY15_Gas_Tx" SG_ 1126 GPS_Actual_vs_Infer_pos 1;
BA_ "U_UP375_MY15_Gas_Tx" SG_ 1126 GPS_Actual_vs_Infer_pos 1;
BA_ "U_UP375_MY15_Diesel_Tx" SG_ 1126 GPS_Actual_vs_Infer_pos 1;
BA_ "U_CD43_MY16_Gas_Tx" SG_ 1126 GPS_Actual_vs_Infer_pos 1;
BA_ "CrossOver_InfoCAN" SG_ 1126 Gps_B_Falt 1;
BA_ "U_CD4_MY13_Diesel_Rx" SG_ 1126 Gps_B_Falt 1;
BA_ "U_CD4_MY13_Gas_Rx" SG_ 1126 Gps_B_Falt 1;
BA_ "U_CD4_MY13_Hev_Rx" SG_ 1126 Gps_B_Falt 1;
BA_ "U_CD4_MY13_Phev_Rx" SG_ 1126 Gps_B_Falt 1;
BA_ "U_CD42_MY14_Diesel_Rx" SG_ 1126 Gps_B_Falt 1;
BA_ "U_CD42_MY14_Gas_Rx" SG_ 1126 Gps_B_Falt 1;
BA_ "U_P552_MY15_Gas_Rx" SG_ 1126 Gps_B_Falt 1;
BA_ "U_S550_MY15_Gas_Rx" SG_ 1126 Gps_B_Falt 1;
BA_ "U_C489_MY14_Gas_Rx" SG_ 1126 Gps_B_Falt 1;
BA_ "U_U502_MY15_Gas_Rx" SG_ 1126 Gps_B_Falt 1;
BA_ "U_UP375_MY15_Gas_Rx" SG_ 1126 Gps_B_Falt 1;
BA_ "U_UP375_MY15_Diesel_Rx" SG_ 1126 Gps_B_Falt 1;
BA_ "U_CD43_MY16_Gas_Rx" SG_ 1126 Gps_B_Falt 1;
BA_ "U_CD4_MY14_Diesel_Rx" SG_ 1126 Gps_B_Falt 1;
BA_ "U_CD4_MY14_Gas_Rx" SG_ 1126 Gps_B_Falt 1;
BA_ "U_CD4_MY14_Hev_Rx" SG_ 1126 Gps_B_Falt 1;
BA_ "U_CD4_MY14_Phev_Rx" SG_ 1126 Gps_B_Falt 1;
BA_ "U_CD4_MY13_Diesel_Tx" SG_ 1126 Gps_B_Falt 1;
BA_ "U_CD4_MY13_Gas_Tx" SG_ 1126 Gps_B_Falt 1;
BA_ "U_CD4_MY13_Hev_Tx" SG_ 1126 Gps_B_Falt 1;
BA_ "U_CD4_MY13_Phev_Tx" SG_ 1126 Gps_B_Falt 1;
BA_ "U_CD42_MY14_Diesel_Tx" SG_ 1126 Gps_B_Falt 1;
BA_ "U_CD42_MY14_Gas_Tx" SG_ 1126 Gps_B_Falt 1;
BA_ "U_P552_MY15_Gas_Tx" SG_ 1126 Gps_B_Falt 1;
BA_ "U_S550_MY15_Gas_Tx" SG_ 1126 Gps_B_Falt 1;
BA_ "U_C489_MY14_Gas_Tx" SG_ 1126 Gps_B_Falt 1;
BA_ "U_U502_MY15_Gas_Tx" SG_ 1126 Gps_B_Falt 1;
BA_ "U_UP375_MY15_Gas_Tx" SG_ 1126 Gps_B_Falt 1;
BA_ "U_UP375_MY15_Diesel_Tx" SG_ 1126 Gps_B_Falt 1;
BA_ "U_CD43_MY16_Gas_Tx" SG_ 1126 Gps_B_Falt 1;
BA_ "CrossOver_InfoCAN" SG_ 1125 GpsHsphLongEast_D_Actl 1;
BA_ "GenSigSendType" SG_ 1125 GpsHsphLongEast_D_Actl 1;
BA_ "U_CD4_MY13_Diesel_Rx" SG_ 1125 GpsHsphLongEast_D_Actl 1;
BA_ "U_CD4_MY13_Gas_Rx" SG_ 1125 GpsHsphLongEast_D_Actl 1;
BA_ "U_CD4_MY13_Hev_Rx" SG_ 1125 GpsHsphLongEast_D_Actl 1;
BA_ "U_CD4_MY13_Phev_Rx" SG_ 1125 GpsHsphLongEast_D_Actl 1;
BA_ "U_CD42_MY14_Diesel_Rx" SG_ 1125 GpsHsphLongEast_D_Actl 1;
BA_ "U_CD42_MY14_Gas_Rx" SG_ 1125 GpsHsphLongEast_D_Actl 1;
BA_ "U_P552_MY15_Gas_Rx" SG_ 1125 GpsHsphLongEast_D_Actl 1;
BA_ "U_S550_MY15_Gas_Rx" SG_ 1125 GpsHsphLongEast_D_Actl 1;
BA_ "U_C489_MY14_Gas_Rx" SG_ 1125 GpsHsphLongEast_D_Actl 1;
BA_ "U_U502_MY15_Gas_Rx" SG_ 1125 GpsHsphLongEast_D_Actl 1;
BA_ "U_UP375_MY15_Gas_Rx" SG_ 1125 GpsHsphLongEast_D_Actl 1;
BA_ "U_UP375_MY15_Diesel_Rx" SG_ 1125 GpsHsphLongEast_D_Actl 1;
BA_ "U_CD43_MY16_Gas_Rx" SG_ 1125 GpsHsphLongEast_D_Actl 1;
BA_ "U_CD4_MY14_Diesel_Rx" SG_ 1125 GpsHsphLongEast_D_Actl 1;
BA_ "U_CD4_MY14_Gas_Rx" SG_ 1125 GpsHsphLongEast_D_Actl 1;
BA_ "U_CD4_MY14_Hev_Rx" SG_ 1125 GpsHsphLongEast_D_Actl 1;
BA_ "U_CD4_MY14_Phev_Rx" SG_ 1125 GpsHsphLongEast_D_Actl 1;
BA_ "U_CD4_MY13_Diesel_Tx" SG_ 1125 GpsHsphLongEast_D_Actl 1;
BA_ "U_CD4_MY13_Gas_Tx" SG_ 1125 GpsHsphLongEast_D_Actl 1;
BA_ "U_CD4_MY13_Hev_Tx" SG_ 1125 GpsHsphLongEast_D_Actl 1;
BA_ "U_CD4_MY13_Phev_Tx" SG_ 1125 GpsHsphLongEast_D_Actl 1;
BA_ "U_CD42_MY14_Diesel_Tx" SG_ 1125 GpsHsphLongEast_D_Actl 1;
BA_ "U_CD42_MY14_Gas_Tx" SG_ 1125 GpsHsphLongEast_D_Actl 1;
BA_ "U_P552_MY15_Gas_Tx" SG_ 1125 GpsHsphLongEast_D_Actl 1;
BA_ "U_S550_MY15_Gas_Tx" SG_ 1125 GpsHsphLongEast_D_Actl 1;
BA_ "U_C489_MY14_Gas_Tx" SG_ 1125 GpsHsphLongEast_D_Actl 1;
BA_ "U_U502_MY15_Gas_Tx" SG_ 1125 GpsHsphLongEast_D_Actl 1;
BA_ "U_UP375_MY15_Gas_Tx" SG_ 1125 GpsHsphLongEast_D_Actl 1;
BA_ "U_UP375_MY15_Diesel_Tx" SG_ 1125 GpsHsphLongEast_D_Actl 1;
BA_ "U_CD43_MY16_Gas_Tx" SG_ 1125 GpsHsphLongEast_D_Actl 1;
BA_ "CrossOver_InfoCAN" SG_ 1125 GpsHsphLattSth_D_Actl 1;
BA_ "U_CD4_MY13_Diesel_Rx" SG_ 1125 GpsHsphLattSth_D_Actl 1;
BA_ "U_CD4_MY13_Gas_Rx" SG_ 1125 GpsHsphLattSth_D_Actl 1;
BA_ "U_CD4_MY13_Hev_Rx" SG_ 1125 GpsHsphLattSth_D_Actl 1;
BA_ "U_CD4_MY13_Phev_Rx" SG_ 1125 GpsHsphLattSth_D_Actl 1;
BA_ "U_CD42_MY14_Diesel_Rx" SG_ 1125 GpsHsphLattSth_D_Actl 1;
BA_ "U_CD42_MY14_Gas_Rx" SG_ 1125 GpsHsphLattSth_D_Actl 1;
BA_ "U_P552_MY15_Gas_Rx" SG_ 1125 GpsHsphLattSth_D_Actl 1;
BA_ "U_S550_MY15_Gas_Rx" SG_ 1125 GpsHsphLattSth_D_Actl 1;
BA_ "U_C489_MY14_Gas_Rx" SG_ 1125 GpsHsphLattSth_D_Actl 1;
BA_ "U_U502_MY15_Gas_Rx" SG_ 1125 GpsHsphLattSth_D_Actl 1;
BA_ "U_UP375_MY15_Gas_Rx" SG_ 1125 GpsHsphLattSth_D_Actl 1;
BA_ "U_UP375_MY15_Diesel_Rx" SG_ 1125 GpsHsphLattSth_D_Actl 1;
BA_ "U_CD43_MY16_Gas_Rx" SG_ 1125 GpsHsphLattSth_D_Actl 1;
BA_ "U_CD4_MY14_Diesel_Rx" SG_ 1125 GpsHsphLattSth_D_Actl 1;
BA_ "U_CD4_MY14_Gas_Rx" SG_ 1125 GpsHsphLattSth_D_Actl 1;
BA_ "U_CD4_MY14_Hev_Rx" SG_ 1125 GpsHsphLattSth_D_Actl 1;
BA_ "U_CD4_MY14_Phev_Rx" SG_ 1125 GpsHsphLattSth_D_Actl 1;
BA_ "U_CD4_MY13_Diesel_Tx" SG_ 1125 GpsHsphLattSth_D_Actl 1;
BA_ "U_CD4_MY13_Gas_Tx" SG_ 1125 GpsHsphLattSth_D_Actl 1;
BA_ "U_CD4_MY13_Hev_Tx" SG_ 1125 GpsHsphLattSth_D_Actl 1;
BA_ "U_CD4_MY13_Phev_Tx" SG_ 1125 GpsHsphLattSth_D_Actl 1;
BA_ "U_CD42_MY14_Diesel_Tx" SG_ 1125 GpsHsphLattSth_D_Actl 1;
BA_ "U_CD42_MY14_Gas_Tx" SG_ 1125 GpsHsphLattSth_D_Actl 1;
BA_ "U_P552_MY15_Gas_Tx" SG_ 1125 GpsHsphLattSth_D_Actl 1;
BA_ "U_S550_MY15_Gas_Tx" SG_ 1125 GpsHsphLattSth_D_Actl 1;
BA_ "U_C489_MY14_Gas_Tx" SG_ 1125 GpsHsphLattSth_D_Actl 1;
BA_ "U_U502_MY15_Gas_Tx" SG_ 1125 GpsHsphLattSth_D_Actl 1;
BA_ "U_UP375_MY15_Gas_Tx" SG_ 1125 GpsHsphLattSth_D_Actl 1;
BA_ "U_UP375_MY15_Diesel_Tx" SG_ 1125 GpsHsphLattSth_D_Actl 1;
BA_ "U_CD43_MY16_Gas_Tx" SG_ 1125 GpsHsphLattSth_D_Actl 1;
BA_ "CrossOver_InfoCAN" SG_ 1125 GPS_Longitude_Minutes 1;
BA_ "U_CD4_MY13_Diesel_Rx" SG_ 1125 GPS_Longitude_Minutes 1;
BA_ "U_CD4_MY13_Gas_Rx" SG_ 1125 GPS_Longitude_Minutes 1;
BA_ "U_CD4_MY13_Hev_Rx" SG_ 1125 GPS_Longitude_Minutes 1;
BA_ "U_CD4_MY13_Phev_Rx" SG_ 1125 GPS_Longitude_Minutes 1;
BA_ "U_CD42_MY14_Diesel_Rx" SG_ 1125 GPS_Longitude_Minutes 1;
BA_ "U_CD42_MY14_Gas_Rx" SG_ 1125 GPS_Longitude_Minutes 1;
BA_ "U_P552_MY15_Gas_Rx" SG_ 1125 GPS_Longitude_Minutes 1;
BA_ "U_S550_MY15_Gas_Rx" SG_ 1125 GPS_Longitude_Minutes 1;
BA_ "U_C489_MY14_Gas_Rx" SG_ 1125 GPS_Longitude_Minutes 1;
BA_ "U_U502_MY15_Gas_Rx" SG_ 1125 GPS_Longitude_Minutes 1;
BA_ "U_UP375_MY15_Gas_Rx" SG_ 1125 GPS_Longitude_Minutes 1;
BA_ "U_UP375_MY15_Diesel_Rx" SG_ 1125 GPS_Longitude_Minutes 1;
BA_ "U_CD43_MY16_Gas_Rx" SG_ 1125 GPS_Longitude_Minutes 1;
BA_ "U_CD4_MY14_Diesel_Rx" SG_ 1125 GPS_Longitude_Minutes 1;
BA_ "U_CD4_MY14_Gas_Rx" SG_ 1125 GPS_Longitude_Minutes 1;
BA_ "U_CD4_MY14_Hev_Rx" SG_ 1125 GPS_Longitude_Minutes 1;
BA_ "U_CD4_MY14_Phev_Rx" SG_ 1125 GPS_Longitude_Minutes 1;
BA_ "U_CD4_MY13_Diesel_Tx" SG_ 1125 GPS_Longitude_Minutes 1;
BA_ "U_CD4_MY13_Gas_Tx" SG_ 1125 GPS_Longitude_Minutes 1;
BA_ "U_CD4_MY13_Hev_Tx" SG_ 1125 GPS_Longitude_Minutes 1;
BA_ "U_CD4_MY13_Phev_Tx" SG_ 1125 GPS_Longitude_Minutes 1;
BA_ "U_CD42_MY14_Diesel_Tx" SG_ 1125 GPS_Longitude_Minutes 1;
BA_ "U_CD42_MY14_Gas_Tx" SG_ 1125 GPS_Longitude_Minutes 1;
BA_ "U_P552_MY15_Gas_Tx" SG_ 1125 GPS_Longitude_Minutes 1;
BA_ "U_S550_MY15_Gas_Tx" SG_ 1125 GPS_Longitude_Minutes 1;
BA_ "U_C489_MY14_Gas_Tx" SG_ 1125 GPS_Longitude_Minutes 1;
BA_ "U_U502_MY15_Gas_Tx" SG_ 1125 GPS_Longitude_Minutes 1;
BA_ "U_UP375_MY15_Gas_Tx" SG_ 1125 GPS_Longitude_Minutes 1;
BA_ "U_UP375_MY15_Diesel_Tx" SG_ 1125 GPS_Longitude_Minutes 1;
BA_ "U_CD43_MY16_Gas_Tx" SG_ 1125 GPS_Longitude_Minutes 1;
BA_ "CrossOver_InfoCAN" SG_ 1125 GPS_Longitude_Min_dec 1;
BA_ "U_CD4_MY13_Diesel_Rx" SG_ 1125 GPS_Longitude_Min_dec 1;
BA_ "U_CD4_MY13_Gas_Rx" SG_ 1125 GPS_Longitude_Min_dec 1;
BA_ "U_CD4_MY13_Hev_Rx" SG_ 1125 GPS_Longitude_Min_dec 1;
BA_ "U_CD4_MY13_Phev_Rx" SG_ 1125 GPS_Longitude_Min_dec 1;
BA_ "U_CD42_MY14_Diesel_Rx" SG_ 1125 GPS_Longitude_Min_dec 1;
BA_ "U_CD42_MY14_Gas_Rx" SG_ 1125 GPS_Longitude_Min_dec 1;
BA_ "U_P552_MY15_Gas_Rx" SG_ 1125 GPS_Longitude_Min_dec 1;
BA_ "U_S550_MY15_Gas_Rx" SG_ 1125 GPS_Longitude_Min_dec 1;
BA_ "U_C489_MY14_Gas_Rx" SG_ 1125 GPS_Longitude_Min_dec 1;
BA_ "U_U502_MY15_Gas_Rx" SG_ 1125 GPS_Longitude_Min_dec 1;
BA_ "U_UP375_MY15_Gas_Rx" SG_ 1125 GPS_Longitude_Min_dec 1;
BA_ "U_UP375_MY15_Diesel_Rx" SG_ 1125 GPS_Longitude_Min_dec 1;
BA_ "U_CD43_MY16_Gas_Rx" SG_ 1125 GPS_Longitude_Min_dec 1;
BA_ "U_CD4_MY14_Diesel_Rx" SG_ 1125 GPS_Longitude_Min_dec 1;
BA_ "U_CD4_MY14_Gas_Rx" SG_ 1125 GPS_Longitude_Min_dec 1;
BA_ "U_CD4_MY14_Hev_Rx" SG_ 1125 GPS_Longitude_Min_dec 1;
BA_ "U_CD4_MY14_Phev_Rx" SG_ 1125 GPS_Longitude_Min_dec 1;
BA_ "U_CD4_MY13_Diesel_Tx" SG_ 1125 GPS_Longitude_Min_dec 1;
BA_ "U_CD4_MY13_Gas_Tx" SG_ 1125 GPS_Longitude_Min_dec 1;
BA_ "U_CD4_MY13_Hev_Tx" SG_ 1125 GPS_Longitude_Min_dec 1;
BA_ "U_CD4_MY13_Phev_Tx" SG_ 1125 GPS_Longitude_Min_dec 1;
BA_ "U_CD42_MY14_Diesel_Tx" SG_ 1125 GPS_Longitude_Min_dec 1;
BA_ "U_CD42_MY14_Gas_Tx" SG_ 1125 GPS_Longitude_Min_dec 1;
BA_ "U_P552_MY15_Gas_Tx" SG_ 1125 GPS_Longitude_Min_dec 1;
BA_ "U_S550_MY15_Gas_Tx" SG_ 1125 GPS_Longitude_Min_dec 1;
BA_ "U_C489_MY14_Gas_Tx" SG_ 1125 GPS_Longitude_Min_dec 1;
BA_ "U_U502_MY15_Gas_Tx" SG_ 1125 GPS_Longitude_Min_dec 1;
BA_ "U_UP375_MY15_Gas_Tx" SG_ 1125 GPS_Longitude_Min_dec 1;
BA_ "U_UP375_MY15_Diesel_Tx" SG_ 1125 GPS_Longitude_Min_dec 1;
BA_ "U_CD43_MY16_Gas_Tx" SG_ 1125 GPS_Longitude_Min_dec 1;
BA_ "CrossOver_InfoCAN" SG_ 1125 GPS_Longitude_Degrees 1;
BA_ "GenSigStartValue" SG_ 1125 GPS_Longitude_Degrees 179;
BA_ "U_CD4_MY13_Diesel_Rx" SG_ 1125 GPS_Longitude_Degrees 1;
BA_ "U_CD4_MY13_Gas_Rx" SG_ 1125 GPS_Longitude_Degrees 1;
BA_ "U_CD4_MY13_Hev_Rx" SG_ 1125 GPS_Longitude_Degrees 1;
BA_ "U_CD4_MY13_Phev_Rx" SG_ 1125 GPS_Longitude_Degrees 1;
BA_ "U_CD42_MY14_Diesel_Rx" SG_ 1125 GPS_Longitude_Degrees 1;
BA_ "U_CD42_MY14_Gas_Rx" SG_ 1125 GPS_Longitude_Degrees 1;
BA_ "U_P552_MY15_Gas_Rx" SG_ 1125 GPS_Longitude_Degrees 1;
BA_ "U_S550_MY15_Gas_Rx" SG_ 1125 GPS_Longitude_Degrees 1;
BA_ "U_C489_MY14_Gas_Rx" SG_ 1125 GPS_Longitude_Degrees 1;
BA_ "U_U502_MY15_Gas_Rx" SG_ 1125 GPS_Longitude_Degrees 1;
BA_ "U_UP375_MY15_Gas_Rx" SG_ 1125 GPS_Longitude_Degrees 1;
BA_ "U_UP375_MY15_Diesel_Rx" SG_ 1125 GPS_Longitude_Degrees 1;
BA_ "U_CD43_MY16_Gas_Rx" SG_ 1125 GPS_Longitude_Degrees 1;
BA_ "U_CD4_MY14_Diesel_Rx" SG_ 1125 GPS_Longitude_Degrees 1;
BA_ "U_CD4_MY14_Gas_Rx" SG_ 1125 GPS_Longitude_Degrees 1;
BA_ "U_CD4_MY14_Hev_Rx" SG_ 1125 GPS_Longitude_Degrees 1;
BA_ "U_CD4_MY14_Phev_Rx" SG_ 1125 GPS_Longitude_Degrees 1;
BA_ "U_CD4_MY13_Diesel_Tx" SG_ 1125 GPS_Longitude_Degrees 1;
BA_ "U_CD4_MY13_Gas_Tx" SG_ 1125 GPS_Longitude_Degrees 1;
BA_ "U_CD4_MY13_Hev_Tx" SG_ 1125 GPS_Longitude_Degrees 1;
BA_ "U_CD4_MY13_Phev_Tx" SG_ 1125 GPS_Longitude_Degrees 1;
BA_ "U_CD42_MY14_Diesel_Tx" SG_ 1125 GPS_Longitude_Degrees 1;
BA_ "U_CD42_MY14_Gas_Tx" SG_ 1125 GPS_Longitude_Degrees 1;
BA_ "U_P552_MY15_Gas_Tx" SG_ 1125 GPS_Longitude_Degrees 1;
BA_ "U_S550_MY15_Gas_Tx" SG_ 1125 GPS_Longitude_Degrees 1;
BA_ "U_C489_MY14_Gas_Tx" SG_ 1125 GPS_Longitude_Degrees 1;
BA_ "U_U502_MY15_Gas_Tx" SG_ 1125 GPS_Longitude_Degrees 1;
BA_ "U_UP375_MY15_Gas_Tx" SG_ 1125 GPS_Longitude_Degrees 1;
BA_ "U_UP375_MY15_Diesel_Tx" SG_ 1125 GPS_Longitude_Degrees 1;
BA_ "U_CD43_MY16_Gas_Tx" SG_ 1125 GPS_Longitude_Degrees 1;
BA_ "CrossOver_InfoCAN" SG_ 1125 GPS_Latitude_Minutes 1;
BA_ "U_CD4_MY13_Diesel_Rx" SG_ 1125 GPS_Latitude_Minutes 1;
BA_ "U_CD4_MY13_Gas_Rx" SG_ 1125 GPS_Latitude_Minutes 1;
BA_ "U_CD4_MY13_Hev_Rx" SG_ 1125 GPS_Latitude_Minutes 1;
BA_ "U_CD4_MY13_Phev_Rx" SG_ 1125 GPS_Latitude_Minutes 1;
BA_ "U_CD42_MY14_Diesel_Rx" SG_ 1125 GPS_Latitude_Minutes 1;
BA_ "U_CD42_MY14_Gas_Rx" SG_ 1125 GPS_Latitude_Minutes 1;
BA_ "U_P552_MY15_Gas_Rx" SG_ 1125 GPS_Latitude_Minutes 1;
BA_ "U_S550_MY15_Gas_Rx" SG_ 1125 GPS_Latitude_Minutes 1;
BA_ "U_C489_MY14_Gas_Rx" SG_ 1125 GPS_Latitude_Minutes 1;
BA_ "U_U502_MY15_Gas_Rx" SG_ 1125 GPS_Latitude_Minutes 1;
BA_ "U_UP375_MY15_Gas_Rx" SG_ 1125 GPS_Latitude_Minutes 1;
BA_ "U_UP375_MY15_Diesel_Rx" SG_ 1125 GPS_Latitude_Minutes 1;
BA_ "U_CD43_MY16_Gas_Rx" SG_ 1125 GPS_Latitude_Minutes 1;
BA_ "U_CD4_MY14_Diesel_Rx" SG_ 1125 GPS_Latitude_Minutes 1;
BA_ "U_CD4_MY14_Gas_Rx" SG_ 1125 GPS_Latitude_Minutes 1;
BA_ "U_CD4_MY14_Hev_Rx" SG_ 1125 GPS_Latitude_Minutes 1;
BA_ "U_CD4_MY14_Phev_Rx" SG_ 1125 GPS_Latitude_Minutes 1;
BA_ "U_CD4_MY13_Diesel_Tx" SG_ 1125 GPS_Latitude_Minutes 1;
BA_ "U_CD4_MY13_Gas_Tx" SG_ 1125 GPS_Latitude_Minutes 1;
BA_ "U_CD4_MY13_Hev_Tx" SG_ 1125 GPS_Latitude_Minutes 1;
BA_ "U_CD4_MY13_Phev_Tx" SG_ 1125 GPS_Latitude_Minutes 1;
BA_ "U_CD42_MY14_Diesel_Tx" SG_ 1125 GPS_Latitude_Minutes 1;
BA_ "U_CD42_MY14_Gas_Tx" SG_ 1125 GPS_Latitude_Minutes 1;
BA_ "U_P552_MY15_Gas_Tx" SG_ 1125 GPS_Latitude_Minutes 1;
BA_ "U_S550_MY15_Gas_Tx" SG_ 1125 GPS_Latitude_Minutes 1;
BA_ "U_C489_MY14_Gas_Tx" SG_ 1125 GPS_Latitude_Minutes 1;
BA_ "U_U502_MY15_Gas_Tx" SG_ 1125 GPS_Latitude_Minutes 1;
BA_ "U_UP375_MY15_Gas_Tx" SG_ 1125 GPS_Latitude_Minutes 1;
BA_ "U_UP375_MY15_Diesel_Tx" SG_ 1125 GPS_Latitude_Minutes 1;
BA_ "U_CD43_MY16_Gas_Tx" SG_ 1125 GPS_Latitude_Minutes 1;
BA_ "CrossOver_InfoCAN" SG_ 1125 GPS_Latitude_Min_dec 1;
BA_ "U_CD4_MY13_Diesel_Rx" SG_ 1125 GPS_Latitude_Min_dec 1;
BA_ "U_CD4_MY13_Gas_Rx" SG_ 1125 GPS_Latitude_Min_dec 1;
BA_ "U_CD4_MY13_Hev_Rx" SG_ 1125 GPS_Latitude_Min_dec 1;
BA_ "U_CD4_MY13_Phev_Rx" SG_ 1125 GPS_Latitude_Min_dec 1;
BA_ "U_CD42_MY14_Diesel_Rx" SG_ 1125 GPS_Latitude_Min_dec 1;
BA_ "U_CD42_MY14_Gas_Rx" SG_ 1125 GPS_Latitude_Min_dec 1;
BA_ "U_P552_MY15_Gas_Rx" SG_ 1125 GPS_Latitude_Min_dec 1;
BA_ "U_S550_MY15_Gas_Rx" SG_ 1125 GPS_Latitude_Min_dec 1;
BA_ "U_C489_MY14_Gas_Rx" SG_ 1125 GPS_Latitude_Min_dec 1;
BA_ "U_U502_MY15_Gas_Rx" SG_ 1125 GPS_Latitude_Min_dec 1;
BA_ "U_UP375_MY15_Gas_Rx" SG_ 1125 GPS_Latitude_Min_dec 1;
BA_ "U_UP375_MY15_Diesel_Rx" SG_ 1125 GPS_Latitude_Min_dec 1;
BA_ "U_CD43_MY16_Gas_Rx" SG_ 1125 GPS_Latitude_Min_dec 1;
BA_ "U_CD4_MY14_Diesel_Rx" SG_ 1125 GPS_Latitude_Min_dec 1;
BA_ "U_CD4_MY14_Gas_Rx" SG_ 1125 GPS_Latitude_Min_dec 1;
BA_ "U_CD4_MY14_Hev_Rx" SG_ 1125 GPS_Latitude_Min_dec 1;
BA_ "U_CD4_MY14_Phev_Rx" SG_ 1125 GPS_Latitude_Min_dec 1;
BA_ "U_CD4_MY13_Diesel_Tx" SG_ 1125 GPS_Latitude_Min_dec 1;
BA_ "U_CD4_MY13_Gas_Tx" SG_ 1125 GPS_Latitude_Min_dec 1;
BA_ "U_CD4_MY13_Hev_Tx" SG_ 1125 GPS_Latitude_Min_dec 1;
BA_ "U_CD4_MY13_Phev_Tx" SG_ 1125 GPS_Latitude_Min_dec 1;
BA_ "U_CD42_MY14_Diesel_Tx" SG_ 1125 GPS_Latitude_Min_dec 1;
BA_ "U_CD42_MY14_Gas_Tx" SG_ 1125 GPS_Latitude_Min_dec 1;
BA_ "U_P552_MY15_Gas_Tx" SG_ 1125 GPS_Latitude_Min_dec 1;
BA_ "U_S550_MY15_Gas_Tx" SG_ 1125 GPS_Latitude_Min_dec 1;
BA_ "U_C489_MY14_Gas_Tx" SG_ 1125 GPS_Latitude_Min_dec 1;
BA_ "U_U502_MY15_Gas_Tx" SG_ 1125 GPS_Latitude_Min_dec 1;
BA_ "U_UP375_MY15_Gas_Tx" SG_ 1125 GPS_Latitude_Min_dec 1;
BA_ "U_UP375_MY15_Diesel_Tx" SG_ 1125 GPS_Latitude_Min_dec 1;
BA_ "U_CD43_MY16_Gas_Tx" SG_ 1125 GPS_Latitude_Min_dec 1;
BA_ "CrossOver_InfoCAN" SG_ 1125 GPS_Latitude_Degrees 1;
BA_ "U_CD4_MY13_Diesel_Rx" SG_ 1125 GPS_Latitude_Degrees 1;
BA_ "U_CD4_MY13_Gas_Rx" SG_ 1125 GPS_Latitude_Degrees 1;
BA_ "U_CD4_MY13_Hev_Rx" SG_ 1125 GPS_Latitude_Degrees 1;
BA_ "U_CD4_MY13_Phev_Rx" SG_ 1125 GPS_Latitude_Degrees 1;
BA_ "U_CD42_MY14_Diesel_Rx" SG_ 1125 GPS_Latitude_Degrees 1;
BA_ "U_CD42_MY14_Gas_Rx" SG_ 1125 GPS_Latitude_Degrees 1;
BA_ "U_P552_MY15_Gas_Rx" SG_ 1125 GPS_Latitude_Degrees 1;
BA_ "U_S550_MY15_Gas_Rx" SG_ 1125 GPS_Latitude_Degrees 1;
BA_ "U_C489_MY14_Gas_Rx" SG_ 1125 GPS_Latitude_Degrees 1;
BA_ "U_U502_MY15_Gas_Rx" SG_ 1125 GPS_Latitude_Degrees 1;
BA_ "U_UP375_MY15_Gas_Rx" SG_ 1125 GPS_Latitude_Degrees 1;
BA_ "U_UP375_MY15_Diesel_Rx" SG_ 1125 GPS_Latitude_Degrees 1;
BA_ "U_CD43_MY16_Gas_Rx" SG_ 1125 GPS_Latitude_Degrees 1;
BA_ "U_CD4_MY14_Diesel_Rx" SG_ 1125 GPS_Latitude_Degrees 1;
BA_ "U_CD4_MY14_Gas_Rx" SG_ 1125 GPS_Latitude_Degrees 1;
BA_ "U_CD4_MY14_Hev_Rx" SG_ 1125 GPS_Latitude_Degrees 1;
BA_ "U_CD4_MY14_Phev_Rx" SG_ 1125 GPS_Latitude_Degrees 1;
BA_ "U_CD4_MY13_Diesel_Tx" SG_ 1125 GPS_Latitude_Degrees 1;
BA_ "U_CD4_MY13_Gas_Tx" SG_ 1125 GPS_Latitude_Degrees 1;
BA_ "U_CD4_MY13_Hev_Tx" SG_ 1125 GPS_Latitude_Degrees 1;
BA_ "U_CD4_MY13_Phev_Tx" SG_ 1125 GPS_Latitude_Degrees 1;
BA_ "U_CD42_MY14_Diesel_Tx" SG_ 1125 GPS_Latitude_Degrees 1;
BA_ "U_CD42_MY14_Gas_Tx" SG_ 1125 GPS_Latitude_Degrees 1;
BA_ "U_P552_MY15_Gas_Tx" SG_ 1125 GPS_Latitude_Degrees 1;
BA_ "U_S550_MY15_Gas_Tx" SG_ 1125 GPS_Latitude_Degrees 1;
BA_ "U_C489_MY14_Gas_Tx" SG_ 1125 GPS_Latitude_Degrees 1;
BA_ "U_U502_MY15_Gas_Tx" SG_ 1125 GPS_Latitude_Degrees 1;
BA_ "U_UP375_MY15_Gas_Tx" SG_ 1125 GPS_Latitude_Degrees 1;
BA_ "U_UP375_MY15_Diesel_Tx" SG_ 1125 GPS_Latitude_Degrees 1;
BA_ "U_CD43_MY16_Gas_Tx" SG_ 1125 GPS_Latitude_Degrees 1;
BA_ "CrossOver_InfoCAN" SG_ 992 MsgCntrPersIndex_D_Rq 1;
BA_ "GenSigStartValue" SG_ 992 MsgCntrPersIndex_D_Rq 4;
BA_ "U_CD4_MY13_Diesel_Rx" SG_ 992 MsgCntrPersIndex_D_Rq 1;
BA_ "U_CD4_MY13_Gas_Rx" SG_ 992 MsgCntrPersIndex_D_Rq 1;
BA_ "U_CD4_MY13_Hev_Rx" SG_ 992 MsgCntrPersIndex_D_Rq 1;
BA_ "U_CD4_MY13_Phev_Rx" SG_ 992 MsgCntrPersIndex_D_Rq 1;
BA_ "U_CD42_MY14_Diesel_Rx" SG_ 992 MsgCntrPersIndex_D_Rq 1;
BA_ "U_CD42_MY14_Gas_Rx" SG_ 992 MsgCntrPersIndex_D_Rq 1;
BA_ "U_P552_MY15_Gas_Rx" SG_ 992 MsgCntrPersIndex_D_Rq 1;
BA_ "U_S550_MY15_Gas_Rx" SG_ 992 MsgCntrPersIndex_D_Rq 1;
BA_ "U_C489_MY14_Gas_Rx" SG_ 992 MsgCntrPersIndex_D_Rq 1;
BA_ "U_U502_MY15_Gas_Rx" SG_ 992 MsgCntrPersIndex_D_Rq 1;
BA_ "U_CD43_MY16_Gas_Rx" SG_ 992 MsgCntrPersIndex_D_Rq 1;
BA_ "U_UP375_MY15_Gas_Rx" SG_ 992 MsgCntrPersIndex_D_Rq 1;
BA_ "U_UP375_MY15_Diesel_Rx" SG_ 992 MsgCntrPersIndex_D_Rq 1;
BA_ "U_CD4_MY14_Diesel_Rx" SG_ 992 MsgCntrPersIndex_D_Rq 1;
BA_ "U_CD4_MY14_Gas_Rx" SG_ 992 MsgCntrPersIndex_D_Rq 1;
BA_ "U_CD4_MY14_Hev_Rx" SG_ 992 MsgCntrPersIndex_D_Rq 1;
BA_ "U_CD4_MY14_Phev_Rx" SG_ 992 MsgCntrPersIndex_D_Rq 1;
BA_ "CrossOver_InfoCAN" SG_ 992 MsgCntrFeatConfigRq 1;
BA_ "U_CD4_MY13_Diesel_Rx" SG_ 992 MsgCntrFeatConfigRq 1;
BA_ "U_CD4_MY13_Gas_Rx" SG_ 992 MsgCntrFeatConfigRq 1;
BA_ "U_CD4_MY13_Hev_Rx" SG_ 992 MsgCntrFeatConfigRq 1;
BA_ "U_CD4_MY13_Phev_Rx" SG_ 992 MsgCntrFeatConfigRq 1;
BA_ "U_CD42_MY14_Diesel_Rx" SG_ 992 MsgCntrFeatConfigRq 1;
BA_ "U_CD42_MY14_Gas_Rx" SG_ 992 MsgCntrFeatConfigRq 1;
BA_ "U_P552_MY15_Gas_Rx" SG_ 992 MsgCntrFeatConfigRq 1;
BA_ "U_S550_MY15_Gas_Rx" SG_ 992 MsgCntrFeatConfigRq 1;
BA_ "U_C489_MY14_Gas_Rx" SG_ 992 MsgCntrFeatConfigRq 1;
BA_ "U_U502_MY15_Gas_Rx" SG_ 992 MsgCntrFeatConfigRq 1;
BA_ "U_CD43_MY16_Gas_Rx" SG_ 992 MsgCntrFeatConfigRq 1;
BA_ "U_UP375_MY15_Gas_Rx" SG_ 992 MsgCntrFeatConfigRq 1;
BA_ "U_UP375_MY15_Diesel_Rx" SG_ 992 MsgCntrFeatConfigRq 1;
BA_ "U_CD4_MY14_Diesel_Rx" SG_ 992 MsgCntrFeatConfigRq 1;
BA_ "U_CD4_MY14_Gas_Rx" SG_ 992 MsgCntrFeatConfigRq 1;
BA_ "U_CD4_MY14_Hev_Rx" SG_ 992 MsgCntrFeatConfigRq 1;
BA_ "U_CD4_MY14_Phev_Rx" SG_ 992 MsgCntrFeatConfigRq 1;
BA_ "CrossOver_InfoCAN" SG_ 992 MsgCntrFeatNoRq 1;
BA_ "U_CD4_MY13_Diesel_Rx" SG_ 992 MsgCntrFeatNoRq 1;
BA_ "U_CD4_MY13_Gas_Rx" SG_ 992 MsgCntrFeatNoRq 1;
BA_ "U_CD4_MY13_Hev_Rx" SG_ 992 MsgCntrFeatNoRq 1;
BA_ "U_CD4_MY13_Phev_Rx" SG_ 992 MsgCntrFeatNoRq 1;
BA_ "U_CD42_MY14_Diesel_Rx" SG_ 992 MsgCntrFeatNoRq 1;
BA_ "U_CD42_MY14_Gas_Rx" SG_ 992 MsgCntrFeatNoRq 1;
BA_ "U_P552_MY15_Gas_Rx" SG_ 992 MsgCntrFeatNoRq 1;
BA_ "U_S550_MY15_Gas_Rx" SG_ 992 MsgCntrFeatNoRq 1;
BA_ "U_C489_MY14_Gas_Rx" SG_ 992 MsgCntrFeatNoRq 1;
BA_ "U_U502_MY15_Gas_Rx" SG_ 992 MsgCntrFeatNoRq 1;
BA_ "U_CD43_MY16_Gas_Rx" SG_ 992 MsgCntrFeatNoRq 1;
BA_ "U_UP375_MY15_Gas_Rx" SG_ 992 MsgCntrFeatNoRq 1;
BA_ "U_UP375_MY15_Diesel_Rx" SG_ 992 MsgCntrFeatNoRq 1;
BA_ "U_CD4_MY14_Diesel_Rx" SG_ 992 MsgCntrFeatNoRq 1;
BA_ "U_CD4_MY14_Gas_Rx" SG_ 992 MsgCntrFeatNoRq 1;
BA_ "U_CD4_MY14_Hev_Rx" SG_ 992 MsgCntrFeatNoRq 1;
BA_ "U_CD4_MY14_Phev_Rx" SG_ 992 MsgCntrFeatNoRq 1;
BA_ "CrossOver_InfoCAN" SG_ 992 MsgCntrDsplyOp_D_Rq 1;
BA_ "U_CD4_MY13_Diesel_Rx" SG_ 992 MsgCntrDsplyOp_D_Rq 1;
BA_ "U_CD4_MY13_Gas_Rx" SG_ 992 MsgCntrDsplyOp_D_Rq 1;
BA_ "U_CD4_MY13_Hev_Rx" SG_ 992 MsgCntrDsplyOp_D_Rq 1;
BA_ "U_CD4_MY13_Phev_Rx" SG_ 992 MsgCntrDsplyOp_D_Rq 1;
BA_ "U_CD42_MY14_Diesel_Rx" SG_ 992 MsgCntrDsplyOp_D_Rq 1;
BA_ "U_CD42_MY14_Gas_Rx" SG_ 992 MsgCntrDsplyOp_D_Rq 1;
BA_ "U_P552_MY15_Gas_Rx" SG_ 992 MsgCntrDsplyOp_D_Rq 1;
BA_ "U_S550_MY15_Gas_Rx" SG_ 992 MsgCntrDsplyOp_D_Rq 1;
BA_ "U_C489_MY14_Gas_Rx" SG_ 992 MsgCntrDsplyOp_D_Rq 1;
BA_ "U_U502_MY15_Gas_Rx" SG_ 992 MsgCntrDsplyOp_D_Rq 1;
BA_ "U_CD43_MY16_Gas_Rx" SG_ 992 MsgCntrDsplyOp_D_Rq 1;
BA_ "U_UP375_MY15_Gas_Rx" SG_ 992 MsgCntrDsplyOp_D_Rq 1;
BA_ "U_UP375_MY15_Diesel_Rx" SG_ 992 MsgCntrDsplyOp_D_Rq 1;
BA_ "U_CD4_MY14_Diesel_Rx" SG_ 992 MsgCntrDsplyOp_D_Rq 1;
BA_ "U_CD4_MY14_Gas_Rx" SG_ 992 MsgCntrDsplyOp_D_Rq 1;
BA_ "U_CD4_MY14_Hev_Rx" SG_ 992 MsgCntrDsplyOp_D_Rq 1;
BA_ "U_CD4_MY14_Phev_Rx" SG_ 992 MsgCntrDsplyOp_D_Rq 1;
BA_ "CrossOver_InfoCAN" SG_ 1127 GPS_Vdop 1;
BA_ "GenSigSendType" SG_ 1127 GPS_Vdop 1;
BA_ "U_CD4_MY13_Diesel_Rx" SG_ 1127 GPS_Vdop 1;
BA_ "U_CD4_MY13_Gas_Rx" SG_ 1127 GPS_Vdop 1;
BA_ "U_CD4_MY13_Hev_Rx" SG_ 1127 GPS_Vdop 1;
BA_ "U_CD4_MY13_Phev_Rx" SG_ 1127 GPS_Vdop 1;
BA_ "U_CD42_MY14_Diesel_Rx" SG_ 1127 GPS_Vdop 1;
BA_ "U_CD42_MY14_Gas_Rx" SG_ 1127 GPS_Vdop 1;
BA_ "U_P552_MY15_Gas_Rx" SG_ 1127 GPS_Vdop 1;
BA_ "U_S550_MY15_Gas_Rx" SG_ 1127 GPS_Vdop 1;
BA_ "U_C489_MY14_Gas_Rx" SG_ 1127 GPS_Vdop 1;
BA_ "U_U502_MY15_Gas_Rx" SG_ 1127 GPS_Vdop 1;
BA_ "U_UP375_MY15_Gas_Rx" SG_ 1127 GPS_Vdop 1;
BA_ "U_UP375_MY15_Diesel_Rx" SG_ 1127 GPS_Vdop 1;
BA_ "U_CD43_MY16_Gas_Rx" SG_ 1127 GPS_Vdop 1;
BA_ "U_CD4_MY14_Diesel_Rx" SG_ 1127 GPS_Vdop 1;
BA_ "U_CD4_MY14_Gas_Rx" SG_ 1127 GPS_Vdop 1;
BA_ "U_CD4_MY14_Hev_Rx" SG_ 1127 GPS_Vdop 1;
BA_ "U_CD4_MY14_Phev_Rx" SG_ 1127 GPS_Vdop 1;
BA_ "U_CD4_MY13_Diesel_Tx" SG_ 1127 GPS_Vdop 1;
BA_ "U_CD4_MY13_Gas_Tx" SG_ 1127 GPS_Vdop 1;
BA_ "U_CD4_MY13_Hev_Tx" SG_ 1127 GPS_Vdop 1;
BA_ "U_CD4_MY13_Phev_Tx" SG_ 1127 GPS_Vdop 1;
BA_ "U_CD42_MY14_Diesel_Tx" SG_ 1127 GPS_Vdop 1;
BA_ "U_CD42_MY14_Gas_Tx" SG_ 1127 GPS_Vdop 1;
BA_ "U_P552_MY15_Gas_Tx" SG_ 1127 GPS_Vdop 1;
BA_ "U_S550_MY15_Gas_Tx" SG_ 1127 GPS_Vdop 1;
BA_ "U_C489_MY14_Gas_Tx" SG_ 1127 GPS_Vdop 1;
BA_ "U_U502_MY15_Gas_Tx" SG_ 1127 GPS_Vdop 1;
BA_ "U_UP375_MY15_Gas_Tx" SG_ 1127 GPS_Vdop 1;
BA_ "U_UP375_MY15_Diesel_Tx" SG_ 1127 GPS_Vdop 1;
BA_ "U_CD43_MY16_Gas_Tx" SG_ 1127 GPS_Vdop 1;
BA_ "CrossOver_InfoCAN" SG_ 1127 GPS_Speed 1;
BA_ "U_CD4_MY13_Diesel_Rx" SG_ 1127 GPS_Speed 1;
BA_ "U_CD4_MY13_Gas_Rx" SG_ 1127 GPS_Speed 1;
BA_ "U_CD4_MY13_Hev_Rx" SG_ 1127 GPS_Speed 1;
BA_ "U_CD4_MY13_Phev_Rx" SG_ 1127 GPS_Speed 1;
BA_ "U_CD42_MY14_Diesel_Rx" SG_ 1127 GPS_Speed 1;
BA_ "U_CD42_MY14_Gas_Rx" SG_ 1127 GPS_Speed 1;
BA_ "U_P552_MY15_Gas_Rx" SG_ 1127 GPS_Speed 1;
BA_ "U_S550_MY15_Gas_Rx" SG_ 1127 GPS_Speed 1;
BA_ "U_C489_MY14_Gas_Rx" SG_ 1127 GPS_Speed 1;
BA_ "U_U502_MY15_Gas_Rx" SG_ 1127 GPS_Speed 1;
BA_ "U_UP375_MY15_Gas_Rx" SG_ 1127 GPS_Speed 1;
BA_ "U_UP375_MY15_Diesel_Rx" SG_ 1127 GPS_Speed 1;
BA_ "U_CD43_MY16_Gas_Rx" SG_ 1127 GPS_Speed 1;
BA_ "U_CD4_MY14_Diesel_Rx" SG_ 1127 GPS_Speed 1;
BA_ "U_CD4_MY14_Gas_Rx" SG_ 1127 GPS_Speed 1;
BA_ "U_CD4_MY14_Hev_Rx" SG_ 1127 GPS_Speed 1;
BA_ "U_CD4_MY14_Phev_Rx" SG_ 1127 GPS_Speed 1;
BA_ "U_CD4_MY13_Diesel_Tx" SG_ 1127 GPS_Speed 1;
BA_ "U_CD4_MY13_Gas_Tx" SG_ 1127 GPS_Speed 1;
BA_ "U_CD4_MY13_Hev_Tx" SG_ 1127 GPS_Speed 1;
BA_ "U_CD4_MY13_Phev_Tx" SG_ 1127 GPS_Speed 1;
BA_ "U_CD42_MY14_Diesel_Tx" SG_ 1127 GPS_Speed 1;
BA_ "U_CD42_MY14_Gas_Tx" SG_ 1127 GPS_Speed 1;
BA_ "U_P552_MY15_Gas_Tx" SG_ 1127 GPS_Speed 1;
BA_ "U_S550_MY15_Gas_Tx" SG_ 1127 GPS_Speed 1;
BA_ "U_C489_MY14_Gas_Tx" SG_ 1127 GPS_Speed 1;
BA_ "U_U502_MY15_Gas_Tx" SG_ 1127 GPS_Speed 1;
BA_ "U_UP375_MY15_Gas_Tx" SG_ 1127 GPS_Speed 1;
BA_ "U_UP375_MY15_Diesel_Tx" SG_ 1127 GPS_Speed 1;
BA_ "U_CD43_MY16_Gas_Tx" SG_ 1127 GPS_Speed 1;
BA_ "CrossOver_InfoCAN" SG_ 1127 GPS_Sat_num_in_view 1;
BA_ "U_CD4_MY13_Diesel_Rx" SG_ 1127 GPS_Sat_num_in_view 1;
BA_ "U_CD4_MY13_Gas_Rx" SG_ 1127 GPS_Sat_num_in_view 1;
BA_ "U_CD4_MY13_Hev_Rx" SG_ 1127 GPS_Sat_num_in_view 1;
BA_ "U_CD4_MY13_Phev_Rx" SG_ 1127 GPS_Sat_num_in_view 1;
BA_ "U_CD42_MY14_Diesel_Rx" SG_ 1127 GPS_Sat_num_in_view 1;
BA_ "U_CD42_MY14_Gas_Rx" SG_ 1127 GPS_Sat_num_in_view 1;
BA_ "U_P552_MY15_Gas_Rx" SG_ 1127 GPS_Sat_num_in_view 1;
BA_ "U_S550_MY15_Gas_Rx" SG_ 1127 GPS_Sat_num_in_view 1;
BA_ "U_C489_MY14_Gas_Rx" SG_ 1127 GPS_Sat_num_in_view 1;
BA_ "U_U502_MY15_Gas_Rx" SG_ 1127 GPS_Sat_num_in_view 1;
BA_ "U_UP375_MY15_Gas_Rx" SG_ 1127 GPS_Sat_num_in_view 1;
BA_ "U_UP375_MY15_Diesel_Rx" SG_ 1127 GPS_Sat_num_in_view 1;
BA_ "U_CD43_MY16_Gas_Rx" SG_ 1127 GPS_Sat_num_in_view 1;
BA_ "U_CD4_MY14_Diesel_Rx" SG_ 1127 GPS_Sat_num_in_view 1;
BA_ "U_CD4_MY14_Gas_Rx" SG_ 1127 GPS_Sat_num_in_view 1;
BA_ "U_CD4_MY14_Hev_Rx" SG_ 1127 GPS_Sat_num_in_view 1;
BA_ "U_CD4_MY14_Phev_Rx" SG_ 1127 GPS_Sat_num_in_view 1;
BA_ "U_CD4_MY13_Diesel_Tx" SG_ 1127 GPS_Sat_num_in_view 1;
BA_ "U_CD4_MY13_Gas_Tx" SG_ 1127 GPS_Sat_num_in_view 1;
BA_ "U_CD4_MY13_Hev_Tx" SG_ 1127 GPS_Sat_num_in_view 1;
BA_ "U_CD4_MY13_Phev_Tx" SG_ 1127 GPS_Sat_num_in_view 1;
BA_ "U_CD42_MY14_Diesel_Tx" SG_ 1127 GPS_Sat_num_in_view 1;
BA_ "U_CD42_MY14_Gas_Tx" SG_ 1127 GPS_Sat_num_in_view 1;
BA_ "U_P552_MY15_Gas_Tx" SG_ 1127 GPS_Sat_num_in_view 1;
BA_ "U_S550_MY15_Gas_Tx" SG_ 1127 GPS_Sat_num_in_view 1;
BA_ "U_C489_MY14_Gas_Tx" SG_ 1127 GPS_Sat_num_in_view 1;
BA_ "U_U502_MY15_Gas_Tx" SG_ 1127 GPS_Sat_num_in_view 1;
BA_ "U_UP375_MY15_Gas_Tx" SG_ 1127 GPS_Sat_num_in_view 1;
BA_ "U_UP375_MY15_Diesel_Tx" SG_ 1127 GPS_Sat_num_in_view 1;
BA_ "U_CD43_MY16_Gas_Tx" SG_ 1127 GPS_Sat_num_in_view 1;
BA_ "CrossOver_InfoCAN" SG_ 1127 GPS_MSL_altitude 1;
BA_ "U_CD4_MY13_Diesel_Rx" SG_ 1127 GPS_MSL_altitude 1;
BA_ "U_CD4_MY13_Gas_Rx" SG_ 1127 GPS_MSL_altitude 1;
BA_ "U_CD4_MY13_Hev_Rx" SG_ 1127 GPS_MSL_altitude 1;
BA_ "U_CD4_MY13_Phev_Rx" SG_ 1127 GPS_MSL_altitude 1;
BA_ "U_CD42_MY14_Diesel_Rx" SG_ 1127 GPS_MSL_altitude 1;
BA_ "U_CD42_MY14_Gas_Rx" SG_ 1127 GPS_MSL_altitude 1;
BA_ "U_P552_MY15_Gas_Rx" SG_ 1127 GPS_MSL_altitude 1;
BA_ "U_S550_MY15_Gas_Rx" SG_ 1127 GPS_MSL_altitude 1;
BA_ "U_C489_MY14_Gas_Rx" SG_ 1127 GPS_MSL_altitude 1;
BA_ "U_U502_MY15_Gas_Rx" SG_ 1127 GPS_MSL_altitude 1;
BA_ "U_UP375_MY15_Gas_Rx" SG_ 1127 GPS_MSL_altitude 1;
BA_ "U_UP375_MY15_Diesel_Rx" SG_ 1127 GPS_MSL_altitude 1;
BA_ "U_CD43_MY16_Gas_Rx" SG_ 1127 GPS_MSL_altitude 1;
BA_ "U_CD4_MY14_Diesel_Rx" SG_ 1127 GPS_MSL_altitude 1;
BA_ "U_CD4_MY14_Gas_Rx" SG_ 1127 GPS_MSL_altitude 1;
BA_ "U_CD4_MY14_Hev_Rx" SG_ 1127 GPS_MSL_altitude 1;
BA_ "U_CD4_MY14_Phev_Rx" SG_ 1127 GPS_MSL_altitude 1;
BA_ "U_CD4_MY13_Diesel_Tx" SG_ 1127 GPS_MSL_altitude 1;
BA_ "U_CD4_MY13_Gas_Tx" SG_ 1127 GPS_MSL_altitude 1;
BA_ "U_CD4_MY13_Hev_Tx" SG_ 1127 GPS_MSL_altitude 1;
BA_ "U_CD4_MY13_Phev_Tx" SG_ 1127 GPS_MSL_altitude 1;
BA_ "U_CD42_MY14_Diesel_Tx" SG_ 1127 GPS_MSL_altitude 1;
BA_ "U_CD42_MY14_Gas_Tx" SG_ 1127 GPS_MSL_altitude 1;
BA_ "U_P552_MY15_Gas_Tx" SG_ 1127 GPS_MSL_altitude 1;
BA_ "U_S550_MY15_Gas_Tx" SG_ 1127 GPS_MSL_altitude 1;
BA_ "U_C489_MY14_Gas_Tx" SG_ 1127 GPS_MSL_altitude 1;
BA_ "U_U502_MY15_Gas_Tx" SG_ 1127 GPS_MSL_altitude 1;
BA_ "U_UP375_MY15_Gas_Tx" SG_ 1127 GPS_MSL_altitude 1;
BA_ "U_UP375_MY15_Diesel_Tx" SG_ 1127 GPS_MSL_altitude 1;
BA_ "U_CD43_MY16_Gas_Tx" SG_ 1127 GPS_MSL_altitude 1;
BA_ "CrossOver_InfoCAN" SG_ 1127 GPS_Heading 1;
BA_ "U_CD4_MY13_Diesel_Rx" SG_ 1127 GPS_Heading 1;
BA_ "U_CD4_MY13_Gas_Rx" SG_ 1127 GPS_Heading 1;
BA_ "U_CD4_MY13_Hev_Rx" SG_ 1127 GPS_Heading 1;
BA_ "U_CD4_MY13_Phev_Rx" SG_ 1127 GPS_Heading 1;
BA_ "U_CD42_MY14_Diesel_Rx" SG_ 1127 GPS_Heading 1;
BA_ "U_CD42_MY14_Gas_Rx" SG_ 1127 GPS_Heading 1;
BA_ "U_P552_MY15_Gas_Rx" SG_ 1127 GPS_Heading 1;
BA_ "U_S550_MY15_Gas_Rx" SG_ 1127 GPS_Heading 1;
BA_ "U_C489_MY14_Gas_Rx" SG_ 1127 GPS_Heading 1;
BA_ "U_U502_MY15_Gas_Rx" SG_ 1127 GPS_Heading 1;
BA_ "U_UP375_MY15_Gas_Rx" SG_ 1127 GPS_Heading 1;
BA_ "U_UP375_MY15_Diesel_Rx" SG_ 1127 GPS_Heading 1;
BA_ "U_CD43_MY16_Gas_Rx" SG_ 1127 GPS_Heading 1;
BA_ "U_CD4_MY14_Diesel_Rx" SG_ 1127 GPS_Heading 1;
BA_ "U_CD4_MY14_Gas_Rx" SG_ 1127 GPS_Heading 1;
BA_ "U_CD4_MY14_Hev_Rx" SG_ 1127 GPS_Heading 1;
BA_ "U_CD4_MY14_Phev_Rx" SG_ 1127 GPS_Heading 1;
BA_ "U_CD4_MY13_Diesel_Tx" SG_ 1127 GPS_Heading 1;
BA_ "U_CD4_MY13_Gas_Tx" SG_ 1127 GPS_Heading 1;
BA_ "U_CD4_MY13_Hev_Tx" SG_ 1127 GPS_Heading 1;
BA_ "U_CD4_MY13_Phev_Tx" SG_ 1127 GPS_Heading 1;
BA_ "U_CD42_MY14_Diesel_Tx" SG_ 1127 GPS_Heading 1;
BA_ "U_CD42_MY14_Gas_Tx" SG_ 1127 GPS_Heading 1;
BA_ "U_P552_MY15_Gas_Tx" SG_ 1127 GPS_Heading 1;
BA_ "U_S550_MY15_Gas_Tx" SG_ 1127 GPS_Heading 1;
BA_ "U_C489_MY14_Gas_Tx" SG_ 1127 GPS_Heading 1;
BA_ "U_U502_MY15_Gas_Tx" SG_ 1127 GPS_Heading 1;
BA_ "U_UP375_MY15_Gas_Tx" SG_ 1127 GPS_Heading 1;
BA_ "U_UP375_MY15_Diesel_Tx" SG_ 1127 GPS_Heading 1;
BA_ "U_CD43_MY16_Gas_Tx" SG_ 1127 GPS_Heading 1;
BA_ "CrossOver_InfoCAN" SG_ 1127 GPS_Hdop 1;
BA_ "U_CD4_MY13_Diesel_Rx" SG_ 1127 GPS_Hdop 1;
BA_ "U_CD4_MY13_Gas_Rx" SG_ 1127 GPS_Hdop 1;
BA_ "U_CD4_MY13_Hev_Rx" SG_ 1127 GPS_Hdop 1;
BA_ "U_CD4_MY13_Phev_Rx" SG_ 1127 GPS_Hdop 1;
BA_ "U_CD42_MY14_Diesel_Rx" SG_ 1127 GPS_Hdop 1;
BA_ "U_CD42_MY14_Gas_Rx" SG_ 1127 GPS_Hdop 1;
BA_ "U_P552_MY15_Gas_Rx" SG_ 1127 GPS_Hdop 1;
BA_ "U_S550_MY15_Gas_Rx" SG_ 1127 GPS_Hdop 1;
BA_ "U_C489_MY14_Gas_Rx" SG_ 1127 GPS_Hdop 1;
BA_ "U_U502_MY15_Gas_Rx" SG_ 1127 GPS_Hdop 1;
BA_ "U_UP375_MY15_Gas_Rx" SG_ 1127 GPS_Hdop 1;
BA_ "U_UP375_MY15_Diesel_Rx" SG_ 1127 GPS_Hdop 1;
BA_ "U_CD43_MY16_Gas_Rx" SG_ 1127 GPS_Hdop 1;
BA_ "U_CD4_MY14_Diesel_Rx" SG_ 1127 GPS_Hdop 1;
BA_ "U_CD4_MY14_Gas_Rx" SG_ 1127 GPS_Hdop 1;
BA_ "U_CD4_MY14_Hev_Rx" SG_ 1127 GPS_Hdop 1;
BA_ "U_CD4_MY14_Phev_Rx" SG_ 1127 GPS_Hdop 1;
BA_ "U_CD4_MY13_Diesel_Tx" SG_ 1127 GPS_Hdop 1;
BA_ "U_CD4_MY13_Gas_Tx" SG_ 1127 GPS_Hdop 1;
BA_ "U_CD4_MY13_Hev_Tx" SG_ 1127 GPS_Hdop 1;
BA_ "U_CD4_MY13_Phev_Tx" SG_ 1127 GPS_Hdop 1;
BA_ "U_CD42_MY14_Diesel_Tx" SG_ 1127 GPS_Hdop 1;
BA_ "U_CD42_MY14_Gas_Tx" SG_ 1127 GPS_Hdop 1;
BA_ "U_P552_MY15_Gas_Tx" SG_ 1127 GPS_Hdop 1;
BA_ "U_S550_MY15_Gas_Tx" SG_ 1127 GPS_Hdop 1;
BA_ "U_C489_MY14_Gas_Tx" SG_ 1127 GPS_Hdop 1;
BA_ "U_U502_MY15_Gas_Tx" SG_ 1127 GPS_Hdop 1;
BA_ "U_UP375_MY15_Gas_Tx" SG_ 1127 GPS_Hdop 1;
BA_ "U_UP375_MY15_Diesel_Tx" SG_ 1127 GPS_Hdop 1;
BA_ "U_CD43_MY16_Gas_Tx" SG_ 1127 GPS_Hdop 1;
BA_ "CrossOver_InfoCAN" SG_ 1127 GPS_dimension 1;
BA_ "U_CD4_MY13_Diesel_Rx" SG_ 1127 GPS_dimension 1;
BA_ "U_CD4_MY13_Gas_Rx" SG_ 1127 GPS_dimension 1;
BA_ "U_CD4_MY13_Hev_Rx" SG_ 1127 GPS_dimension 1;
BA_ "U_CD4_MY13_Phev_Rx" SG_ 1127 GPS_dimension 1;
BA_ "U_CD42_MY14_Diesel_Rx" SG_ 1127 GPS_dimension 1;
BA_ "U_CD42_MY14_Gas_Rx" SG_ 1127 GPS_dimension 1;
BA_ "U_P552_MY15_Gas_Rx" SG_ 1127 GPS_dimension 1;
BA_ "U_S550_MY15_Gas_Rx" SG_ 1127 GPS_dimension 1;
BA_ "U_C489_MY14_Gas_Rx" SG_ 1127 GPS_dimension 1;
BA_ "U_U502_MY15_Gas_Rx" SG_ 1127 GPS_dimension 1;
BA_ "U_UP375_MY15_Gas_Rx" SG_ 1127 GPS_dimension 1;
BA_ "U_UP375_MY15_Diesel_Rx" SG_ 1127 GPS_dimension 1;
BA_ "U_CD43_MY16_Gas_Rx" SG_ 1127 GPS_dimension 1;
BA_ "U_CD4_MY14_Diesel_Rx" SG_ 1127 GPS_dimension 1;
BA_ "U_CD4_MY14_Gas_Rx" SG_ 1127 GPS_dimension 1;
BA_ "U_CD4_MY14_Hev_Rx" SG_ 1127 GPS_dimension 1;
BA_ "U_CD4_MY14_Phev_Rx" SG_ 1127 GPS_dimension 1;
BA_ "U_CD4_MY13_Diesel_Tx" SG_ 1127 GPS_dimension 1;
BA_ "U_CD4_MY13_Gas_Tx" SG_ 1127 GPS_dimension 1;
BA_ "U_CD4_MY13_Hev_Tx" SG_ 1127 GPS_dimension 1;
BA_ "U_CD4_MY13_Phev_Tx" SG_ 1127 GPS_dimension 1;
BA_ "U_CD42_MY14_Diesel_Tx" SG_ 1127 GPS_dimension 1;
BA_ "U_CD42_MY14_Gas_Tx" SG_ 1127 GPS_dimension 1;
BA_ "U_P552_MY15_Gas_Tx" SG_ 1127 GPS_dimension 1;
BA_ "U_S550_MY15_Gas_Tx" SG_ 1127 GPS_dimension 1;
BA_ "U_C489_MY14_Gas_Tx" SG_ 1127 GPS_dimension 1;
BA_ "U_U502_MY15_Gas_Tx" SG_ 1127 GPS_dimension 1;
BA_ "U_UP375_MY15_Gas_Tx" SG_ 1127 GPS_dimension 1;
BA_ "U_UP375_MY15_Diesel_Tx" SG_ 1127 GPS_dimension 1;
BA_ "U_CD43_MY16_Gas_Tx" SG_ 1127 GPS_dimension 1;
BA_ "GenSigSendType" SG_ 861 SteWhlHeat_D_Stat 3;
BA_ "U_CD4_MY13_Diesel_Rx" SG_ 861 SteWhlHeat_D_Stat 1;
BA_ "U_CD4_MY13_Gas_Rx" SG_ 861 SteWhlHeat_D_Stat 1;
BA_ "U_CD4_MY13_Hev_Rx" SG_ 861 SteWhlHeat_D_Stat 1;
BA_ "U_CD4_MY13_Phev_Rx" SG_ 861 SteWhlHeat_D_Stat 1;
BA_ "U_CD42_MY14_Diesel_Rx" SG_ 861 SteWhlHeat_D_Stat 1;
BA_ "U_CD42_MY14_Gas_Rx" SG_ 861 SteWhlHeat_D_Stat 1;
BA_ "U_P552_MY15_Gas_Rx" SG_ 861 SteWhlHeat_D_Stat 1;
BA_ "U_C489_MY14_Gas_Rx" SG_ 861 SteWhlHeat_D_Stat 1;
BA_ "U_UP375_MY15_Gas_Rx" SG_ 861 SteWhlHeat_D_Stat 1;
BA_ "U_UP375_MY15_Diesel_Rx" SG_ 861 SteWhlHeat_D_Stat 1;
BA_ "U_CD43_MY16_Gas_Rx" SG_ 861 SteWhlHeat_D_Stat 1;
BA_ "U_CD4_MY13_Diesel_Tx" SG_ 861 SteWhlHeat_D_Stat 1;
BA_ "U_CD4_MY13_Gas_Tx" SG_ 861 SteWhlHeat_D_Stat 1;
BA_ "U_CD4_MY13_Hev_Tx" SG_ 861 SteWhlHeat_D_Stat 1;
BA_ "U_CD4_MY13_Phev_Tx" SG_ 861 SteWhlHeat_D_Stat 1;
BA_ "U_CD42_MY14_Diesel_Tx" SG_ 861 SteWhlHeat_D_Stat 1;
BA_ "U_CD42_MY14_Gas_Tx" SG_ 861 SteWhlHeat_D_Stat 1;
BA_ "U_P552_MY15_Gas_Tx" SG_ 861 SteWhlHeat_D_Stat 1;
BA_ "U_C489_MY14_Gas_Tx" SG_ 861 SteWhlHeat_D_Stat 1;
BA_ "U_U502_MY15_Gas_Tx" SG_ 861 SteWhlHeat_D_Stat 1;
BA_ "U_CD43_MY16_Gas_Tx" SG_ 861 SteWhlHeat_D_Stat 1;
BA_ "CrossOver_InfoCAN" SG_ 999 FeatNoFcimActl 1;
BA_ "GenSigSendType" SG_ 999 FeatNoFcimActl 3;
BA_ "U_CD4_MY13_Diesel_Tx" SG_ 999 FeatNoFcimActl 1;
BA_ "U_CD4_MY13_Gas_Tx" SG_ 999 FeatNoFcimActl 1;
BA_ "U_CD4_MY13_Hev_Tx" SG_ 999 FeatNoFcimActl 1;
BA_ "U_CD4_MY13_Phev_Tx" SG_ 999 FeatNoFcimActl 1;
BA_ "U_P552_MY15_Gas_Tx" SG_ 999 FeatNoFcimActl 1;
BA_ "U_S550_MY15_Gas_Tx" SG_ 999 FeatNoFcimActl 1;
BA_ "U_C489_MY14_Gas_Tx" SG_ 999 FeatNoFcimActl 1;
BA_ "U_CD43_MY16_Gas_Tx" SG_ 999 FeatNoFcimActl 1;
BA_ "CrossOver_InfoCAN" SG_ 999 FeatConfigFcimActl 1;
BA_ "GenSigSendType" SG_ 999 FeatConfigFcimActl 3;
BA_ "U_CD4_MY13_Diesel_Tx" SG_ 999 FeatConfigFcimActl 1;
BA_ "U_CD4_MY13_Gas_Tx" SG_ 999 FeatConfigFcimActl 1;
BA_ "U_CD4_MY13_Hev_Tx" SG_ 999 FeatConfigFcimActl 1;
BA_ "U_CD4_MY13_Phev_Tx" SG_ 999 FeatConfigFcimActl 1;
BA_ "U_P552_MY15_Gas_Tx" SG_ 999 FeatConfigFcimActl 1;
BA_ "U_S550_MY15_Gas_Tx" SG_ 999 FeatConfigFcimActl 1;
BA_ "U_C489_MY14_Gas_Tx" SG_ 999 FeatConfigFcimActl 1;
BA_ "U_CD43_MY16_Gas_Tx" SG_ 999 FeatConfigFcimActl 1;
BA_ "CrossOver_InfoCAN" SG_ 999 PersIndexFcim_D_Actl 1;
BA_ "GenSigStartValue" SG_ 999 PersIndexFcim_D_Actl 4;
BA_ "GenSigSendType" SG_ 999 PersIndexFcim_D_Actl 3;
BA_ "U_CD4_MY13_Diesel_Tx" SG_ 999 PersIndexFcim_D_Actl 1;
BA_ "U_CD4_MY13_Gas_Tx" SG_ 999 PersIndexFcim_D_Actl 1;
BA_ "U_CD4_MY13_Hev_Tx" SG_ 999 PersIndexFcim_D_Actl 1;
BA_ "U_CD4_MY13_Phev_Tx" SG_ 999 PersIndexFcim_D_Actl 1;
BA_ "U_CD42_MY14_Diesel_Tx" SG_ 999 PersIndexFcim_D_Actl 1;
BA_ "U_CD42_MY14_Gas_Tx" SG_ 999 PersIndexFcim_D_Actl 1;
BA_ "U_P552_MY15_Gas_Tx" SG_ 999 PersIndexFcim_D_Actl 1;
BA_ "U_S550_MY15_Gas_Tx" SG_ 999 PersIndexFcim_D_Actl 1;
BA_ "U_C489_MY14_Gas_Tx" SG_ 999 PersIndexFcim_D_Actl 1;
BA_ "U_U502_MY15_Gas_Tx" SG_ 999 PersIndexFcim_D_Actl 1;
BA_ "U_UP375_MY15_Gas_Tx" SG_ 999 PersIndexFcim_D_Actl 1;
BA_ "U_UP375_MY15_Diesel_Tx" SG_ 999 PersIndexFcim_D_Actl 1;
BA_ "U_CD43_MY16_Gas_Tx" SG_ 999 PersIndexFcim_D_Actl 1;
BA_ "GenSigSendType" SG_ 1998 TesterPhysicalResSODR 3;
BA_ "U_CD4_MY13_Diesel_Tx" SG_ 1998 TesterPhysicalResSODR 1;
BA_ "U_CD4_MY13_Gas_Tx" SG_ 1998 TesterPhysicalResSODR 1;
BA_ "U_CD4_MY13_Hev_Tx" SG_ 1998 TesterPhysicalResSODR 1;
BA_ "U_CD4_MY13_Phev_Tx" SG_ 1998 TesterPhysicalResSODR 1;
BA_ "U_CD42_MY14_Diesel_Tx" SG_ 1998 TesterPhysicalResSODR 1;
BA_ "U_CD42_MY14_Gas_Tx" SG_ 1998 TesterPhysicalResSODR 1;
BA_ "U_P552_MY15_Gas_Tx" SG_ 1998 TesterPhysicalResSODR 1;
BA_ "U_S550_MY15_Gas_Tx" SG_ 1998 TesterPhysicalResSODR 1;
BA_ "U_C489_MY14_Gas_Tx" SG_ 1998 TesterPhysicalResSODR 1;
BA_ "U_U502_MY15_Gas_Tx" SG_ 1998 TesterPhysicalResSODR 1;
BA_ "U_UP375_MY15_Gas_Tx" SG_ 1998 TesterPhysicalResSODR 1;
BA_ "U_UP375_MY15_Diesel_Tx" SG_ 1998 TesterPhysicalResSODR 1;
BA_ "U_CD43_MY16_Gas_Tx" SG_ 1998 TesterPhysicalResSODR 1;
BA_ "GenSigSendType" SG_ 1990 TesterPhysicalReqSODR 3;
BA_ "U_CD4_MY13_Diesel_Rx" SG_ 1990 TesterPhysicalReqSODR 1;
BA_ "U_CD4_MY13_Gas_Rx" SG_ 1990 TesterPhysicalReqSODR 1;
BA_ "U_CD4_MY13_Hev_Rx" SG_ 1990 TesterPhysicalReqSODR 1;
BA_ "U_CD4_MY13_Phev_Rx" SG_ 1990 TesterPhysicalReqSODR 1;
BA_ "U_CD42_MY14_Diesel_Rx" SG_ 1990 TesterPhysicalReqSODR 1;
BA_ "U_CD42_MY14_Gas_Rx" SG_ 1990 TesterPhysicalReqSODR 1;
BA_ "U_P552_MY15_Gas_Rx" SG_ 1990 TesterPhysicalReqSODR 1;
BA_ "U_S550_MY15_Gas_Rx" SG_ 1990 TesterPhysicalReqSODR 1;
BA_ "U_C489_MY14_Gas_Rx" SG_ 1990 TesterPhysicalReqSODR 1;
BA_ "U_B562LC_MY14_Gas_Rx" SG_ 1990 TesterPhysicalReqSODR 1;
BA_ "U_U502_MY15_Gas_Rx" SG_ 1990 TesterPhysicalReqSODR 1;
BA_ "U_UP375_MY15_Gas_Rx" SG_ 1990 TesterPhysicalReqSODR 1;
BA_ "U_UP375_MY15_Diesel_Rx" SG_ 1990 TesterPhysicalReqSODR 1;
BA_ "U_CD43_MY16_Gas_Rx" SG_ 1990 TesterPhysicalReqSODR 1;
BA_ "GenSigSendType" SG_ 1996 TesterPhysicalResSODL 3;
BA_ "U_CD4_MY13_Diesel_Tx" SG_ 1996 TesterPhysicalResSODL 1;
BA_ "U_CD4_MY13_Gas_Tx" SG_ 1996 TesterPhysicalResSODL 1;
BA_ "U_CD4_MY13_Hev_Tx" SG_ 1996 TesterPhysicalResSODL 1;
BA_ "U_CD4_MY13_Phev_Tx" SG_ 1996 TesterPhysicalResSODL 1;
BA_ "U_CD42_MY14_Diesel_Tx" SG_ 1996 TesterPhysicalResSODL 1;
BA_ "U_CD42_MY14_Gas_Tx" SG_ 1996 TesterPhysicalResSODL 1;
BA_ "U_P552_MY15_Gas_Tx" SG_ 1996 TesterPhysicalResSODL 1;
BA_ "U_S550_MY15_Gas_Tx" SG_ 1996 TesterPhysicalResSODL 1;
BA_ "U_C489_MY14_Gas_Tx" SG_ 1996 TesterPhysicalResSODL 1;
BA_ "U_U502_MY15_Gas_Tx" SG_ 1996 TesterPhysicalResSODL 1;
BA_ "U_UP375_MY15_Gas_Tx" SG_ 1996 TesterPhysicalResSODL 1;
BA_ "U_UP375_MY15_Diesel_Tx" SG_ 1996 TesterPhysicalResSODL 1;
BA_ "U_CD43_MY16_Gas_Tx" SG_ 1996 TesterPhysicalResSODL 1;
BA_ "GenSigSendType" SG_ 1988 TesterPhysicalReqSODL 3;
BA_ "U_CD4_MY13_Diesel_Rx" SG_ 1988 TesterPhysicalReqSODL 1;
BA_ "U_CD4_MY13_Gas_Rx" SG_ 1988 TesterPhysicalReqSODL 1;
BA_ "U_CD4_MY13_Hev_Rx" SG_ 1988 TesterPhysicalReqSODL 1;
BA_ "U_CD4_MY13_Phev_Rx" SG_ 1988 TesterPhysicalReqSODL 1;
BA_ "U_CD42_MY14_Diesel_Rx" SG_ 1988 TesterPhysicalReqSODL 1;
BA_ "U_CD42_MY14_Gas_Rx" SG_ 1988 TesterPhysicalReqSODL 1;
BA_ "U_P552_MY15_Gas_Rx" SG_ 1988 TesterPhysicalReqSODL 1;
BA_ "U_S550_MY15_Gas_Rx" SG_ 1988 TesterPhysicalReqSODL 1;
BA_ "U_C489_MY14_Gas_Rx" SG_ 1988 TesterPhysicalReqSODL 1;
BA_ "U_U502_MY15_Gas_Rx" SG_ 1988 TesterPhysicalReqSODL 1;
BA_ "U_UP375_MY15_Gas_Rx" SG_ 1988 TesterPhysicalReqSODL 1;
BA_ "U_UP375_MY15_Diesel_Rx" SG_ 1988 TesterPhysicalReqSODL 1;
BA_ "U_CD43_MY16_Gas_Rx" SG_ 1988 TesterPhysicalReqSODL 1;
BA_ "U_CD4_MY13_Diesel_Tx" SG_ 862 TwHlGrdAsst_B_RqTrn 1;
BA_ "U_CD4_MY13_Gas_Tx" SG_ 862 TwHlGrdAsst_B_RqTrn 1;
BA_ "U_CD4_MY13_Hev_Tx" SG_ 862 TwHlGrdAsst_B_RqTrn 1;
BA_ "U_CD4_MY13_Phev_Tx" SG_ 862 TwHlGrdAsst_B_RqTrn 1;
BA_ "U_CD42_MY14_Diesel_Tx" SG_ 862 TwHlGrdAsst_B_RqTrn 1;
BA_ "U_CD42_MY14_Gas_Tx" SG_ 862 TwHlGrdAsst_B_RqTrn 1;
BA_ "U_P552_MY15_Gas_Tx" SG_ 862 TwHlGrdAsst_B_RqTrn 1;
BA_ "U_U502_MY15_Gas_Tx" SG_ 862 TwHlGrdAsst_B_RqTrn 1;
BA_ "U_UP375_MY15_Gas_Tx" SG_ 862 TwHlGrdAsst_B_RqTrn 1;
BA_ "U_UP375_MY15_Diesel_Tx" SG_ 862 TwHlGrdAsst_B_RqTrn 1;
BA_ "U_CD43_MY16_Gas_Tx" SG_ 862 TwHlGrdAsst_B_RqTrn 1;
BA_ "U_CD4_MY13_Diesel_Tx" SG_ 862 ApaSwtch_No_Cnt 1;
BA_ "U_CD4_MY13_Gas_Tx" SG_ 862 ApaSwtch_No_Cnt 1;
BA_ "U_CD4_MY13_Hev_Tx" SG_ 862 ApaSwtch_No_Cnt 1;
BA_ "U_CD4_MY13_Phev_Tx" SG_ 862 ApaSwtch_No_Cnt 1;
BA_ "U_CD42_MY14_Diesel_Tx" SG_ 862 ApaSwtch_No_Cnt 1;
BA_ "U_CD42_MY14_Gas_Tx" SG_ 862 ApaSwtch_No_Cnt 1;
BA_ "U_P552_MY15_Gas_Tx" SG_ 862 ApaSwtch_No_Cnt 1;
BA_ "U_C489_MY14_Gas_Tx" SG_ 862 ApaSwtch_No_Cnt 1;
BA_ "U_U502_MY15_Gas_Tx" SG_ 862 ApaSwtch_No_Cnt 1;
BA_ "U_UP375_MY15_Gas_Tx" SG_ 862 ApaSwtch_No_Cnt 1;
BA_ "U_UP375_MY15_Diesel_Tx" SG_ 862 ApaSwtch_No_Cnt 1;
BA_ "U_CD43_MY16_Gas_Tx" SG_ 862 ApaSwtch_No_Cnt 1;
BA_ "GenSigSendType" SG_ 862 ApaSwtch_D_RqDrv 3;
BA_ "U_CD4_MY13_Diesel_Tx" SG_ 862 ApaSwtch_D_RqDrv 1;
BA_ "U_CD4_MY13_Gas_Tx" SG_ 862 ApaSwtch_D_RqDrv 1;
BA_ "U_CD4_MY13_Hev_Tx" SG_ 862 ApaSwtch_D_RqDrv 1;
BA_ "U_CD4_MY13_Phev_Tx" SG_ 862 ApaSwtch_D_RqDrv 1;
BA_ "U_CD42_MY14_Diesel_Tx" SG_ 862 ApaSwtch_D_RqDrv 1;
BA_ "U_CD42_MY14_Gas_Tx" SG_ 862 ApaSwtch_D_RqDrv 1;
BA_ "U_P552_MY15_Gas_Tx" SG_ 862 ApaSwtch_D_RqDrv 1;
BA_ "U_C489_MY14_Gas_Tx" SG_ 862 ApaSwtch_D_RqDrv 1;
BA_ "U_U502_MY15_Gas_Tx" SG_ 862 ApaSwtch_D_RqDrv 1;
BA_ "U_UP375_MY15_Gas_Tx" SG_ 862 ApaSwtch_D_RqDrv 1;
BA_ "U_UP375_MY15_Diesel_Tx" SG_ 862 ApaSwtch_D_RqDrv 1;
BA_ "U_CD43_MY16_Gas_Tx" SG_ 862 ApaSwtch_D_RqDrv 1;
BA_ "GenSigSendType" SG_ 862 HvacBlwrFront_D_Stat 3;
BA_ "U_CD4_MY13_Diesel_Tx" SG_ 862 HvacBlwrFront_D_Stat 1;
BA_ "U_CD4_MY13_Gas_Tx" SG_ 862 HvacBlwrFront_D_Stat 1;
BA_ "U_CD4_MY13_Hev_Tx" SG_ 862 HvacBlwrFront_D_Stat 1;
BA_ "U_CD4_MY13_Phev_Tx" SG_ 862 HvacBlwrFront_D_Stat 1;
BA_ "U_CD42_MY14_Diesel_Tx" SG_ 862 HvacBlwrFront_D_Stat 1;
BA_ "U_CD42_MY14_Gas_Tx" SG_ 862 HvacBlwrFront_D_Stat 1;
BA_ "U_P552_MY15_Gas_Tx" SG_ 862 HvacBlwrFront_D_Stat 1;
BA_ "U_S550_MY15_Gas_Tx" SG_ 862 HvacBlwrFront_D_Stat 1;
BA_ "U_C489_MY14_Gas_Tx" SG_ 862 HvacBlwrFront_D_Stat 1;
BA_ "U_U502_MY15_Gas_Tx" SG_ 862 HvacBlwrFront_D_Stat 1;
BA_ "U_UP375_MY15_Gas_Tx" SG_ 862 HvacBlwrFront_D_Stat 1;
BA_ "U_UP375_MY15_Diesel_Tx" SG_ 862 HvacBlwrFront_D_Stat 1;
BA_ "U_CD43_MY16_Gas_Tx" SG_ 862 HvacBlwrFront_D_Stat 1;
BA_ "GenSigSendType" SG_ 862 HvacBlwrRear_D_Stat 3;
BA_ "U_CD4_MY13_Diesel_Tx" SG_ 862 HvacBlwrRear_D_Stat 1;
BA_ "U_CD4_MY13_Gas_Tx" SG_ 862 HvacBlwrRear_D_Stat 1;
BA_ "U_CD4_MY13_Hev_Tx" SG_ 862 HvacBlwrRear_D_Stat 1;
BA_ "U_CD4_MY13_Phev_Tx" SG_ 862 HvacBlwrRear_D_Stat 1;
BA_ "U_CD42_MY14_Diesel_Tx" SG_ 862 HvacBlwrRear_D_Stat 1;
BA_ "U_CD42_MY14_Gas_Tx" SG_ 862 HvacBlwrRear_D_Stat 1;
BA_ "U_P552_MY15_Gas_Tx" SG_ 862 HvacBlwrRear_D_Stat 1;
BA_ "U_U502_MY15_Gas_Tx" SG_ 862 HvacBlwrRear_D_Stat 1;
BA_ "U_UP375_MY15_Gas_Tx" SG_ 862 HvacBlwrRear_D_Stat 1;
BA_ "U_UP375_MY15_Diesel_Tx" SG_ 862 HvacBlwrRear_D_Stat 1;
BA_ "U_CD43_MY16_Gas_Tx" SG_ 862 HvacBlwrRear_D_Stat 1;
BA_ "GenSigSendType" SG_ 862 HvacRemoteStrt_N_Rq 3;
BA_ "U_CD4_MY13_Diesel_Tx" SG_ 862 HvacRemoteStrt_N_Rq 1;
BA_ "U_CD4_MY13_Gas_Tx" SG_ 862 HvacRemoteStrt_N_Rq 1;
BA_ "U_CD4_MY13_Hev_Tx" SG_ 862 HvacRemoteStrt_N_Rq 1;
BA_ "U_CD4_MY13_Phev_Tx" SG_ 862 HvacRemoteStrt_N_Rq 1;
BA_ "U_CD42_MY14_Diesel_Tx" SG_ 862 HvacRemoteStrt_N_Rq 1;
BA_ "U_CD42_MY14_Gas_Tx" SG_ 862 HvacRemoteStrt_N_Rq 1;
BA_ "U_P552_MY15_Gas_Tx" SG_ 862 HvacRemoteStrt_N_Rq 1;
BA_ "U_S550_MY15_Gas_Tx" SG_ 862 HvacRemoteStrt_N_Rq 1;
BA_ "U_C489_MY14_Gas_Tx" SG_ 862 HvacRemoteStrt_N_Rq 1;
BA_ "U_U502_MY15_Gas_Tx" SG_ 862 HvacRemoteStrt_N_Rq 1;
BA_ "U_UP375_MY15_Gas_Tx" SG_ 862 HvacRemoteStrt_N_Rq 1;
BA_ "U_UP375_MY15_Diesel_Tx" SG_ 862 HvacRemoteStrt_N_Rq 1;
BA_ "U_CD43_MY16_Gas_Tx" SG_ 862 HvacRemoteStrt_N_Rq 1;
BA_ "GenSigStartValue" SG_ 862 ClimtThrmlLoad_No_Actl 255;
BA_ "GenSigSendType" SG_ 862 ClimtThrmlLoad_No_Actl 3;
BA_ "U_CD4_MY13_Diesel_Tx" SG_ 862 ClimtThrmlLoad_No_Actl 1;
BA_ "U_CD4_MY13_Gas_Tx" SG_ 862 ClimtThrmlLoad_No_Actl 1;
BA_ "U_CD4_MY13_Hev_Tx" SG_ 862 ClimtThrmlLoad_No_Actl 1;
BA_ "U_CD4_MY13_Phev_Tx" SG_ 862 ClimtThrmlLoad_No_Actl 1;
BA_ "U_CD42_MY14_Diesel_Tx" SG_ 862 ClimtThrmlLoad_No_Actl 1;
BA_ "U_CD42_MY14_Gas_Tx" SG_ 862 ClimtThrmlLoad_No_Actl 1;
BA_ "U_P552_MY15_Gas_Tx" SG_ 862 ClimtThrmlLoad_No_Actl 1;
BA_ "U_U502_MY15_Gas_Tx" SG_ 862 ClimtThrmlLoad_No_Actl 1;
BA_ "U_UP375_MY15_Gas_Tx" SG_ 862 ClimtThrmlLoad_No_Actl 1;
BA_ "U_UP375_MY15_Diesel_Tx" SG_ 862 ClimtThrmlLoad_No_Actl 1;
BA_ "U_CD43_MY16_Gas_Tx" SG_ 862 ClimtThrmlLoad_No_Actl 1;
BA_ "GenSigStartValue" SG_ 862 AutoStpHvacDelta_I_Est 192;
BA_ "GenSigSendType" SG_ 862 AutoStpHvacDelta_I_Est 3;
BA_ "U_CD4_MY13_Diesel_Tx" SG_ 862 AutoStpHvacDelta_I_Est 1;
BA_ "U_CD4_MY13_Gas_Tx" SG_ 862 AutoStpHvacDelta_I_Est 1;
BA_ "U_CD4_MY13_Hev_Tx" SG_ 862 AutoStpHvacDelta_I_Est 1;
BA_ "U_CD4_MY13_Phev_Tx" SG_ 862 AutoStpHvacDelta_I_Est 1;
BA_ "U_CD42_MY14_Diesel_Tx" SG_ 862 AutoStpHvacDelta_I_Est 1;
BA_ "U_CD42_MY14_Gas_Tx" SG_ 862 AutoStpHvacDelta_I_Est 1;
BA_ "U_P552_MY15_Gas_Tx" SG_ 862 AutoStpHvacDelta_I_Est 1;
BA_ "U_U502_MY15_Gas_Tx" SG_ 862 AutoStpHvacDelta_I_Est 1;
BA_ "U_UP375_MY15_Gas_Tx" SG_ 862 AutoStpHvacDelta_I_Est 1;
BA_ "U_UP375_MY15_Diesel_Tx" SG_ 862 AutoStpHvacDelta_I_Est 1;
BA_ "U_CD43_MY16_Gas_Tx" SG_ 862 AutoStpHvacDelta_I_Est 1;
BA_ "WakeupSignal" SG_ 828 RearPassWindowPos 1;
BA_ "GenSigSendType" SG_ 828 RearPassWindowPos 3;
BA_ "U_CD4_MY13_Diesel_Rx" SG_ 828 RearPassWindowPos 1;
BA_ "U_CD4_MY13_Gas_Rx" SG_ 828 RearPassWindowPos 1;
BA_ "U_CD4_MY13_Hev_Rx" SG_ 828 RearPassWindowPos 1;
BA_ "U_CD4_MY13_Phev_Rx" SG_ 828 RearPassWindowPos 1;
BA_ "U_CD42_MY14_Diesel_Rx" SG_ 828 RearPassWindowPos 1;
BA_ "U_CD42_MY14_Gas_Rx" SG_ 828 RearPassWindowPos 1;
BA_ "U_P552_MY15_Gas_Rx" SG_ 828 RearPassWindowPos 1;
BA_ "U_S550_MY15_Gas_Rx" SG_ 828 RearPassWindowPos 1;
BA_ "U_C489_MY14_Gas_Rx" SG_ 828 RearPassWindowPos 1;
BA_ "U_U502_MY15_Gas_Rx" SG_ 828 RearPassWindowPos 1;
BA_ "U_B479_MY15_Gas_Rx" SG_ 828 RearPassWindowPos 1;
BA_ "U_UP375_MY15_Gas_Rx" SG_ 828 RearPassWindowPos 1;
BA_ "U_UP375_MY15_Diesel_Rx" SG_ 828 RearPassWindowPos 1;
BA_ "U_CD43_MY16_Gas_Rx" SG_ 828 RearPassWindowPos 1;
BA_ "U_CD4_MY13_Diesel_Tx" SG_ 828 RearPassWindowPos 1;
BA_ "U_CD4_MY13_Gas_Tx" SG_ 828 RearPassWindowPos 1;
BA_ "U_CD4_MY13_Hev_Tx" SG_ 828 RearPassWindowPos 1;
BA_ "U_CD4_MY13_Phev_Tx" SG_ 828 RearPassWindowPos 1;
BA_ "U_CD42_MY14_Diesel_Tx" SG_ 828 RearPassWindowPos 1;
BA_ "U_CD42_MY14_Gas_Tx" SG_ 828 RearPassWindowPos 1;
BA_ "U_P552_MY15_Gas_Tx" SG_ 828 RearPassWindowPos 1;
BA_ "U_S550_MY15_Gas_Tx" SG_ 828 RearPassWindowPos 1;
BA_ "U_C489_MY14_Gas_Tx" SG_ 828 RearPassWindowPos 1;
BA_ "U_U502_MY15_Gas_Tx" SG_ 828 RearPassWindowPos 1;
BA_ "U_UP375_MY15_Gas_Tx" SG_ 828 RearPassWindowPos 1;
BA_ "U_UP375_MY15_Diesel_Tx" SG_ 828 RearPassWindowPos 1;
BA_ "U_CD43_MY16_Gas_Tx" SG_ 828 RearPassWindowPos 1;
BA_ "U_CD4_MY14_Diesel_Tx" SG_ 828 RearPassWindowPos 1;
BA_ "U_CD4_MY14_Gas_Tx" SG_ 828 RearPassWindowPos 1;
BA_ "U_CD4_MY14_Hev_Tx" SG_ 828 RearPassWindowPos 1;
BA_ "U_CD4_MY14_Phev_Tx" SG_ 828 RearPassWindowPos 1;
BA_ "WakeupSignal" SG_ 828 PassWindowPosition 1;
BA_ "GenSigSendType" SG_ 828 PassWindowPosition 3;
BA_ "U_CD4_MY13_Diesel_Rx" SG_ 828 PassWindowPosition 1;
BA_ "U_CD4_MY13_Gas_Rx" SG_ 828 PassWindowPosition 1;
BA_ "U_CD4_MY13_Hev_Rx" SG_ 828 PassWindowPosition 1;
BA_ "U_CD4_MY13_Phev_Rx" SG_ 828 PassWindowPosition 1;
BA_ "U_CD42_MY14_Diesel_Rx" SG_ 828 PassWindowPosition 1;
BA_ "U_CD42_MY14_Gas_Rx" SG_ 828 PassWindowPosition 1;
BA_ "U_P552_MY15_Gas_Rx" SG_ 828 PassWindowPosition 1;
BA_ "U_S550_MY15_Gas_Rx" SG_ 828 PassWindowPosition 1;
BA_ "U_C489_MY14_Gas_Rx" SG_ 828 PassWindowPosition 1;
BA_ "U_U502_MY15_Gas_Rx" SG_ 828 PassWindowPosition 1;
BA_ "U_B479_MY15_Gas_Rx" SG_ 828 PassWindowPosition 1;
BA_ "U_UP375_MY15_Gas_Rx" SG_ 828 PassWindowPosition 1;
BA_ "U_UP375_MY15_Diesel_Rx" SG_ 828 PassWindowPosition 1;
BA_ "U_CD43_MY16_Gas_Rx" SG_ 828 PassWindowPosition 1;
BA_ "U_CD4_MY13_Diesel_Tx" SG_ 828 PassWindowPosition 1;
BA_ "U_CD4_MY13_Gas_Tx" SG_ 828 PassWindowPosition 1;
BA_ "U_CD4_MY13_Hev_Tx" SG_ 828 PassWindowPosition 1;
BA_ "U_CD4_MY13_Phev_Tx" SG_ 828 PassWindowPosition 1;
BA_ "U_CD42_MY14_Diesel_Tx" SG_ 828 PassWindowPosition 1;
BA_ "U_CD42_MY14_Gas_Tx" SG_ 828 PassWindowPosition 1;
BA_ "U_P552_MY15_Gas_Tx" SG_ 828 PassWindowPosition 1;
BA_ "U_S550_MY15_Gas_Tx" SG_ 828 PassWindowPosition 1;
BA_ "U_C489_MY14_Gas_Tx" SG_ 828 PassWindowPosition 1;
BA_ "U_U502_MY15_Gas_Tx" SG_ 828 PassWindowPosition 1;
BA_ "U_UP375_MY15_Gas_Tx" SG_ 828 PassWindowPosition 1;
BA_ "U_UP375_MY15_Diesel_Tx" SG_ 828 PassWindowPosition 1;
BA_ "U_CD43_MY16_Gas_Tx" SG_ 828 PassWindowPosition 1;
BA_ "U_CD4_MY14_Diesel_Tx" SG_ 828 PassWindowPosition 1;
BA_ "U_CD4_MY14_Gas_Tx" SG_ 828 PassWindowPosition 1;
BA_ "U_CD4_MY14_Hev_Tx" SG_ 828 PassWindowPosition 1;
BA_ "U_CD4_MY14_Phev_Tx" SG_ 828 PassWindowPosition 1;
BA_ "GenSigSendType" SG_ 2000 TesterPhysicalReqAPIM 3;
BA_ "U_CD4_MY13_Diesel_Rx" SG_ 2000 TesterPhysicalReqAPIM 1;
BA_ "U_CD4_MY13_Gas_Rx" SG_ 2000 TesterPhysicalReqAPIM 1;
BA_ "U_CD4_MY13_Hev_Rx" SG_ 2000 TesterPhysicalReqAPIM 1;
BA_ "U_CD4_MY13_Phev_Rx" SG_ 2000 TesterPhysicalReqAPIM 1;
BA_ "U_CD42_MY14_Diesel_Rx" SG_ 2000 TesterPhysicalReqAPIM 1;
BA_ "U_CD42_MY14_Gas_Rx" SG_ 2000 TesterPhysicalReqAPIM 1;
BA_ "U_P552_MY15_Gas_Rx" SG_ 2000 TesterPhysicalReqAPIM 1;
BA_ "U_S550_MY15_Gas_Rx" SG_ 2000 TesterPhysicalReqAPIM 1;
BA_ "U_C489_MY14_Gas_Rx" SG_ 2000 TesterPhysicalReqAPIM 1;
BA_ "U_U502_MY15_Gas_Rx" SG_ 2000 TesterPhysicalReqAPIM 1;
BA_ "U_UP375_MY15_Gas_Rx" SG_ 2000 TesterPhysicalReqAPIM 1;
BA_ "U_UP375_MY15_Diesel_Rx" SG_ 2000 TesterPhysicalReqAPIM 1;
BA_ "U_CD43_MY16_Gas_Rx" SG_ 2000 TesterPhysicalReqAPIM 1;
BA_ "GenSigSendType" SG_ 1894 TesterPhysicalReqRBM 3;
BA_ "U_P552_MY15_Gas_Rx" SG_ 1894 TesterPhysicalReqRBM 1;
BA_ "GenSigSendType" SG_ 1349 RBM_Network_Mgmt 3;
BA_ "U_CD4_MY13_Diesel_Rx" SG_ 1349 RBM_Network_Mgmt 1;
BA_ "U_CD4_MY13_Gas_Rx" SG_ 1349 RBM_Network_Mgmt 1;
BA_ "U_CD4_MY13_Hev_Rx" SG_ 1349 RBM_Network_Mgmt 1;
BA_ "U_CD4_MY13_Phev_Rx" SG_ 1349 RBM_Network_Mgmt 1;
BA_ "U_CD42_MY14_Diesel_Rx" SG_ 1349 RBM_Network_Mgmt 1;
BA_ "U_CD42_MY14_Gas_Rx" SG_ 1349 RBM_Network_Mgmt 1;
BA_ "U_P552_MY15_Gas_Rx" SG_ 1349 RBM_Network_Mgmt 1;
BA_ "U_S550_MY15_Gas_Rx" SG_ 1349 RBM_Network_Mgmt 1;
BA_ "U_C489_MY14_Gas_Rx" SG_ 1349 RBM_Network_Mgmt 1;
BA_ "U_U502_MY15_Gas_Rx" SG_ 1349 RBM_Network_Mgmt 1;
BA_ "U_CD43_MY16_Gas_Rx" SG_ 1349 RBM_Network_Mgmt 1;
BA_ "U_CD4_MY14_Diesel_Rx" SG_ 1349 RBM_Network_Mgmt 1;
BA_ "U_CD4_MY14_Gas_Rx" SG_ 1349 RBM_Network_Mgmt 1;
BA_ "U_CD4_MY14_Hev_Rx" SG_ 1349 RBM_Network_Mgmt 1;
BA_ "U_CD4_MY14_Phev_Rx" SG_ 1349 RBM_Network_Mgmt 1;
BA_ "U_UP375_MY15_Gas_Rx" SG_ 1349 RBM_Network_Mgmt 1;
BA_ "U_UP375_MY15_Diesel_Rx" SG_ 1349 RBM_Network_Mgmt 1;
BA_ "U_P552_MY15_Gas_Tx" SG_ 1349 RBM_Network_Mgmt 1;
BA_ "GenSigSendType" SG_ 1902 TesterPhysicalResRBM 3;
BA_ "U_P552_MY15_Gas_Tx" SG_ 1902 TesterPhysicalResRBM 1;
BA_ "GenSigSendType" SG_ 1860 TesterPhysicalReqDSM 3;
BA_ "U_CD4_MY13_Diesel_Rx" SG_ 1860 TesterPhysicalReqDSM 1;
BA_ "U_CD4_MY13_Gas_Rx" SG_ 1860 TesterPhysicalReqDSM 1;
BA_ "U_CD4_MY13_Hev_Rx" SG_ 1860 TesterPhysicalReqDSM 1;
BA_ "U_CD4_MY13_Phev_Rx" SG_ 1860 TesterPhysicalReqDSM 1;
BA_ "U_CD42_MY14_Diesel_Rx" SG_ 1860 TesterPhysicalReqDSM 1;
BA_ "U_CD42_MY14_Gas_Rx" SG_ 1860 TesterPhysicalReqDSM 1;
BA_ "U_P552_MY15_Gas_Rx" SG_ 1860 TesterPhysicalReqDSM 1;
BA_ "U_S550_MY15_Gas_Rx" SG_ 1860 TesterPhysicalReqDSM 1;
BA_ "U_C489_MY14_Gas_Rx" SG_ 1860 TesterPhysicalReqDSM 1;
BA_ "U_U502_MY15_Gas_Rx" SG_ 1860 TesterPhysicalReqDSM 1;
BA_ "U_CD43_MY16_Gas_Rx" SG_ 1860 TesterPhysicalReqDSM 1;
BA_ "GenSigSendType" SG_ 1868 TesterPhysicalResDSM 3;
BA_ "U_CD4_MY13_Diesel_Tx" SG_ 1868 TesterPhysicalResDSM 1;
BA_ "U_CD4_MY13_Gas_Tx" SG_ 1868 TesterPhysicalResDSM 1;
BA_ "U_CD4_MY13_Hev_Tx" SG_ 1868 TesterPhysicalResDSM 1;
BA_ "U_CD4_MY13_Phev_Tx" SG_ 1868 TesterPhysicalResDSM 1;
BA_ "U_CD42_MY14_Diesel_Tx" SG_ 1868 TesterPhysicalResDSM 1;
BA_ "U_CD42_MY14_Gas_Tx" SG_ 1868 TesterPhysicalResDSM 1;
BA_ "U_P552_MY15_Gas_Tx" SG_ 1868 TesterPhysicalResDSM 1;
BA_ "U_S550_MY15_Gas_Tx" SG_ 1868 TesterPhysicalResDSM 1;
BA_ "U_C489_MY14_Gas_Tx" SG_ 1868 TesterPhysicalResDSM 1;
BA_ "U_U502_MY15_Gas_Tx" SG_ 1868 TesterPhysicalResDSM 1;
BA_ "U_CD43_MY16_Gas_Tx" SG_ 1868 TesterPhysicalResDSM 1;
BA_ "GenSigSendType" SG_ 1918 TesterPhysicalResSCME 3;
BA_ "U_CD4_MY13_Diesel_Tx" SG_ 1918 TesterPhysicalResSCME 1;
BA_ "U_CD4_MY13_Gas_Tx" SG_ 1918 TesterPhysicalResSCME 1;
BA_ "U_CD4_MY13_Hev_Tx" SG_ 1918 TesterPhysicalResSCME 1;
BA_ "U_CD4_MY13_Phev_Tx" SG_ 1918 TesterPhysicalResSCME 1;
BA_ "U_CD42_MY14_Diesel_Tx" SG_ 1918 TesterPhysicalResSCME 1;
BA_ "U_CD42_MY14_Gas_Tx" SG_ 1918 TesterPhysicalResSCME 1;
BA_ "U_P552_MY15_Gas_Tx" SG_ 1918 TesterPhysicalResSCME 1;
BA_ "U_S550_MY15_Gas_Tx" SG_ 1918 TesterPhysicalResSCME 1;
BA_ "U_C489_MY14_Gas_Tx" SG_ 1918 TesterPhysicalResSCME 1;
BA_ "U_U502_MY15_Gas_Tx" SG_ 1918 TesterPhysicalResSCME 1;
BA_ "U_CD43_MY16_Gas_Tx" SG_ 1918 TesterPhysicalResSCME 1;
BA_ "U_CD4_MY14_Diesel_Tx" SG_ 1918 TesterPhysicalResSCME 1;
BA_ "U_CD4_MY14_Gas_Tx" SG_ 1918 TesterPhysicalResSCME 1;
BA_ "U_CD4_MY14_Hev_Tx" SG_ 1918 TesterPhysicalResSCME 1;
BA_ "U_CD4_MY14_Phev_Tx" SG_ 1918 TesterPhysicalResSCME 1;
BA_ "GenSigSendType" SG_ 1910 TesterPhysicalReqSCME 3;
BA_ "U_CD4_MY13_Diesel_Rx" SG_ 1910 TesterPhysicalReqSCME 1;
BA_ "U_CD4_MY13_Gas_Rx" SG_ 1910 TesterPhysicalReqSCME 1;
BA_ "U_CD4_MY13_Hev_Rx" SG_ 1910 TesterPhysicalReqSCME 1;
BA_ "U_CD4_MY13_Phev_Rx" SG_ 1910 TesterPhysicalReqSCME 1;
BA_ "U_CD42_MY14_Diesel_Rx" SG_ 1910 TesterPhysicalReqSCME 1;
BA_ "U_CD42_MY14_Gas_Rx" SG_ 1910 TesterPhysicalReqSCME 1;
BA_ "U_P552_MY15_Gas_Rx" SG_ 1910 TesterPhysicalReqSCME 1;
BA_ "U_S550_MY15_Gas_Rx" SG_ 1910 TesterPhysicalReqSCME 1;
BA_ "U_C489_MY14_Gas_Rx" SG_ 1910 TesterPhysicalReqSCME 1;
BA_ "U_U502_MY15_Gas_Rx" SG_ 1910 TesterPhysicalReqSCME 1;
BA_ "U_CD43_MY16_Gas_Rx" SG_ 1910 TesterPhysicalReqSCME 1;
BA_ "U_CD4_MY14_Diesel_Rx" SG_ 1910 TesterPhysicalReqSCME 1;
BA_ "U_CD4_MY14_Gas_Rx" SG_ 1910 TesterPhysicalReqSCME 1;
BA_ "U_CD4_MY14_Hev_Rx" SG_ 1910 TesterPhysicalReqSCME 1;
BA_ "U_CD4_MY14_Phev_Rx" SG_ 1910 TesterPhysicalReqSCME 1;
BA_ "GenSigSendType" SG_ 1814 TesterPhysicalReqGWM_M1 3;
BA_ "GenSigSendType" SG_ 1822 TesterPhysicalResGWM_M1 3;
BA_ "WakeupSignal" SG_ 826 Memory_3_Sw_Stat 1;
BA_ "GenSigSendType" SG_ 826 Memory_3_Sw_Stat 3;
BA_ "U_CD4_MY13_Diesel_Rx" SG_ 826 Memory_3_Sw_Stat 1;
BA_ "U_CD4_MY13_Gas_Rx" SG_ 826 Memory_3_Sw_Stat 1;
BA_ "U_CD4_MY13_Hev_Rx" SG_ 826 Memory_3_Sw_Stat 1;
BA_ "U_CD4_MY13_Phev_Rx" SG_ 826 Memory_3_Sw_Stat 1;
BA_ "U_CD42_MY14_Diesel_Rx" SG_ 826 Memory_3_Sw_Stat 1;
BA_ "U_CD42_MY14_Gas_Rx" SG_ 826 Memory_3_Sw_Stat 1;
BA_ "U_P552_MY15_Gas_Rx" SG_ 826 Memory_3_Sw_Stat 1;
BA_ "U_S550_MY15_Gas_Rx" SG_ 826 Memory_3_Sw_Stat 1;
BA_ "U_C489_MY14_Gas_Rx" SG_ 826 Memory_3_Sw_Stat 1;
BA_ "U_U502_MY15_Gas_Rx" SG_ 826 Memory_3_Sw_Stat 1;
BA_ "U_CD43_MY16_Gas_Rx" SG_ 826 Memory_3_Sw_Stat 1;
BA_ "U_CD4_MY13_Diesel_Tx" SG_ 826 Memory_3_Sw_Stat 1;
BA_ "U_CD4_MY13_Gas_Tx" SG_ 826 Memory_3_Sw_Stat 1;
BA_ "U_CD4_MY13_Hev_Tx" SG_ 826 Memory_3_Sw_Stat 1;
BA_ "U_CD4_MY13_Phev_Tx" SG_ 826 Memory_3_Sw_Stat 1;
BA_ "U_CD42_MY14_Diesel_Tx" SG_ 826 Memory_3_Sw_Stat 1;
BA_ "U_CD42_MY14_Gas_Tx" SG_ 826 Memory_3_Sw_Stat 1;
BA_ "U_P552_MY15_Gas_Tx" SG_ 826 Memory_3_Sw_Stat 1;
BA_ "U_S550_MY15_Gas_Tx" SG_ 826 Memory_3_Sw_Stat 1;
BA_ "U_C489_MY14_Gas_Tx" SG_ 826 Memory_3_Sw_Stat 1;
BA_ "U_U502_MY15_Gas_Tx" SG_ 826 Memory_3_Sw_Stat 1;
BA_ "U_UP375_MY15_Gas_Tx" SG_ 826 Memory_3_Sw_Stat 1;
BA_ "U_UP375_MY15_Diesel_Tx" SG_ 826 Memory_3_Sw_Stat 1;
BA_ "U_CD43_MY16_Gas_Tx" SG_ 826 Memory_3_Sw_Stat 1;
BA_ "U_CD4_MY14_Diesel_Tx" SG_ 826 Memory_3_Sw_Stat 1;
BA_ "U_CD4_MY14_Gas_Tx" SG_ 826 Memory_3_Sw_Stat 1;
BA_ "U_CD4_MY14_Hev_Tx" SG_ 826 Memory_3_Sw_Stat 1;
BA_ "U_CD4_MY14_Phev_Tx" SG_ 826 Memory_3_Sw_Stat 1;
BA_ "WakeupSignal" SG_ 826 Memory_2_Sw_Stat 1;
BA_ "GenSigSendType" SG_ 826 Memory_2_Sw_Stat 3;
BA_ "U_CD4_MY13_Diesel_Rx" SG_ 826 Memory_2_Sw_Stat 1;
BA_ "U_CD4_MY13_Gas_Rx" SG_ 826 Memory_2_Sw_Stat 1;
BA_ "U_CD4_MY13_Hev_Rx" SG_ 826 Memory_2_Sw_Stat 1;
BA_ "U_CD4_MY13_Phev_Rx" SG_ 826 Memory_2_Sw_Stat 1;
BA_ "U_CD42_MY14_Diesel_Rx" SG_ 826 Memory_2_Sw_Stat 1;
BA_ "U_CD42_MY14_Gas_Rx" SG_ 826 Memory_2_Sw_Stat 1;
BA_ "U_P552_MY15_Gas_Rx" SG_ 826 Memory_2_Sw_Stat 1;
BA_ "U_S550_MY15_Gas_Rx" SG_ 826 Memory_2_Sw_Stat 1;
BA_ "U_C489_MY14_Gas_Rx" SG_ 826 Memory_2_Sw_Stat 1;
BA_ "U_U502_MY15_Gas_Rx" SG_ 826 Memory_2_Sw_Stat 1;
BA_ "U_CD43_MY16_Gas_Rx" SG_ 826 Memory_2_Sw_Stat 1;
BA_ "U_CD4_MY13_Diesel_Tx" SG_ 826 Memory_2_Sw_Stat 1;
BA_ "U_CD4_MY13_Gas_Tx" SG_ 826 Memory_2_Sw_Stat 1;
BA_ "U_CD4_MY13_Hev_Tx" SG_ 826 Memory_2_Sw_Stat 1;
BA_ "U_CD4_MY13_Phev_Tx" SG_ 826 Memory_2_Sw_Stat 1;
BA_ "U_CD42_MY14_Diesel_Tx" SG_ 826 Memory_2_Sw_Stat 1;
BA_ "U_CD42_MY14_Gas_Tx" SG_ 826 Memory_2_Sw_Stat 1;
BA_ "U_P552_MY15_Gas_Tx" SG_ 826 Memory_2_Sw_Stat 1;
BA_ "U_S550_MY15_Gas_Tx" SG_ 826 Memory_2_Sw_Stat 1;
BA_ "U_C489_MY14_Gas_Tx" SG_ 826 Memory_2_Sw_Stat 1;
BA_ "U_U502_MY15_Gas_Tx" SG_ 826 Memory_2_Sw_Stat 1;
BA_ "U_UP375_MY15_Gas_Tx" SG_ 826 Memory_2_Sw_Stat 1;
BA_ "U_UP375_MY15_Diesel_Tx" SG_ 826 Memory_2_Sw_Stat 1;
BA_ "U_CD43_MY16_Gas_Tx" SG_ 826 Memory_2_Sw_Stat 1;
BA_ "U_CD4_MY14_Diesel_Tx" SG_ 826 Memory_2_Sw_Stat 1;
BA_ "U_CD4_MY14_Gas_Tx" SG_ 826 Memory_2_Sw_Stat 1;
BA_ "U_CD4_MY14_Hev_Tx" SG_ 826 Memory_2_Sw_Stat 1;
BA_ "U_CD4_MY14_Phev_Tx" SG_ 826 Memory_2_Sw_Stat 1;
BA_ "WakeupSignal" SG_ 826 Memory_1_Sw_Stat 1;
BA_ "GenSigSendType" SG_ 826 Memory_1_Sw_Stat 3;
BA_ "U_CD4_MY13_Diesel_Rx" SG_ 826 Memory_1_Sw_Stat 1;
BA_ "U_CD4_MY13_Gas_Rx" SG_ 826 Memory_1_Sw_Stat 1;
BA_ "U_CD4_MY13_Hev_Rx" SG_ 826 Memory_1_Sw_Stat 1;
BA_ "U_CD4_MY13_Phev_Rx" SG_ 826 Memory_1_Sw_Stat 1;
BA_ "U_CD42_MY14_Diesel_Rx" SG_ 826 Memory_1_Sw_Stat 1;
BA_ "U_CD42_MY14_Gas_Rx" SG_ 826 Memory_1_Sw_Stat 1;
BA_ "U_P552_MY15_Gas_Rx" SG_ 826 Memory_1_Sw_Stat 1;
BA_ "U_S550_MY15_Gas_Rx" SG_ 826 Memory_1_Sw_Stat 1;
BA_ "U_C489_MY14_Gas_Rx" SG_ 826 Memory_1_Sw_Stat 1;
BA_ "U_U502_MY15_Gas_Rx" SG_ 826 Memory_1_Sw_Stat 1;
BA_ "U_CD43_MY16_Gas_Rx" SG_ 826 Memory_1_Sw_Stat 1;
BA_ "U_CD4_MY13_Diesel_Tx" SG_ 826 Memory_1_Sw_Stat 1;
BA_ "U_CD4_MY13_Gas_Tx" SG_ 826 Memory_1_Sw_Stat 1;
BA_ "U_CD4_MY13_Hev_Tx" SG_ 826 Memory_1_Sw_Stat 1;
BA_ "U_CD4_MY13_Phev_Tx" SG_ 826 Memory_1_Sw_Stat 1;
BA_ "U_CD42_MY14_Diesel_Tx" SG_ 826 Memory_1_Sw_Stat 1;
BA_ "U_CD42_MY14_Gas_Tx" SG_ 826 Memory_1_Sw_Stat 1;
BA_ "U_P552_MY15_Gas_Tx" SG_ 826 Memory_1_Sw_Stat 1;
BA_ "U_S550_MY15_Gas_Tx" SG_ 826 Memory_1_Sw_Stat 1;
BA_ "U_C489_MY14_Gas_Tx" SG_ 826 Memory_1_Sw_Stat 1;
BA_ "U_U502_MY15_Gas_Tx" SG_ 826 Memory_1_Sw_Stat 1;
BA_ "U_UP375_MY15_Gas_Tx" SG_ 826 Memory_1_Sw_Stat 1;
BA_ "U_UP375_MY15_Diesel_Tx" SG_ 826 Memory_1_Sw_Stat 1;
BA_ "U_CD43_MY16_Gas_Tx" SG_ 826 Memory_1_Sw_Stat 1;
BA_ "U_CD4_MY14_Diesel_Tx" SG_ 826 Memory_1_Sw_Stat 1;
BA_ "U_CD4_MY14_Gas_Tx" SG_ 826 Memory_1_Sw_Stat 1;
BA_ "U_CD4_MY14_Hev_Tx" SG_ 826 Memory_1_Sw_Stat 1;
BA_ "U_CD4_MY14_Phev_Tx" SG_ 826 Memory_1_Sw_Stat 1;
BA_ "WakeupSignal" SG_ 826 Mirror_Manual_Override 1;
BA_ "GenSigSendType" SG_ 826 Mirror_Manual_Override 3;
BA_ "U_CD4_MY13_Diesel_Rx" SG_ 826 Mirror_Manual_Override 1;
BA_ "U_CD4_MY13_Gas_Rx" SG_ 826 Mirror_Manual_Override 1;
BA_ "U_CD4_MY13_Hev_Rx" SG_ 826 Mirror_Manual_Override 1;
BA_ "U_CD4_MY13_Phev_Rx" SG_ 826 Mirror_Manual_Override 1;
BA_ "U_CD42_MY14_Diesel_Rx" SG_ 826 Mirror_Manual_Override 1;
BA_ "U_CD42_MY14_Gas_Rx" SG_ 826 Mirror_Manual_Override 1;
BA_ "U_P552_MY15_Gas_Rx" SG_ 826 Mirror_Manual_Override 1;
BA_ "U_S550_MY15_Gas_Rx" SG_ 826 Mirror_Manual_Override 1;
BA_ "U_C489_MY14_Gas_Rx" SG_ 826 Mirror_Manual_Override 1;
BA_ "U_U502_MY15_Gas_Rx" SG_ 826 Mirror_Manual_Override 1;
BA_ "U_CD43_MY16_Gas_Rx" SG_ 826 Mirror_Manual_Override 1;
BA_ "U_CD4_MY13_Diesel_Tx" SG_ 826 Mirror_Manual_Override 1;
BA_ "U_CD4_MY13_Gas_Tx" SG_ 826 Mirror_Manual_Override 1;
BA_ "U_CD4_MY13_Hev_Tx" SG_ 826 Mirror_Manual_Override 1;
BA_ "U_CD4_MY13_Phev_Tx" SG_ 826 Mirror_Manual_Override 1;
BA_ "U_CD42_MY14_Diesel_Tx" SG_ 826 Mirror_Manual_Override 1;
BA_ "U_CD42_MY14_Gas_Tx" SG_ 826 Mirror_Manual_Override 1;
BA_ "U_P552_MY15_Gas_Tx" SG_ 826 Mirror_Manual_Override 1;
BA_ "U_S550_MY15_Gas_Tx" SG_ 826 Mirror_Manual_Override 1;
BA_ "U_C489_MY14_Gas_Tx" SG_ 826 Mirror_Manual_Override 1;
BA_ "U_U502_MY15_Gas_Tx" SG_ 826 Mirror_Manual_Override 1;
BA_ "U_UP375_MY15_Gas_Tx" SG_ 826 Mirror_Manual_Override 1;
BA_ "U_UP375_MY15_Diesel_Tx" SG_ 826 Mirror_Manual_Override 1;
BA_ "U_CD43_MY16_Gas_Tx" SG_ 826 Mirror_Manual_Override 1;
BA_ "U_CD4_MY14_Diesel_Tx" SG_ 826 Mirror_Manual_Override 1;
BA_ "U_CD4_MY14_Gas_Tx" SG_ 826 Mirror_Manual_Override 1;
BA_ "U_CD4_MY14_Hev_Tx" SG_ 826 Mirror_Manual_Override 1;
BA_ "U_CD4_MY14_Phev_Tx" SG_ 826 Mirror_Manual_Override 1;
BA_ "CrossOver_InfoCAN" SG_ 853 RHS_Cond_Seat_Status 1;
BA_ "GenSigSendType" SG_ 853 RHS_Cond_Seat_Status 3;
BA_ "U_CD4_MY13_Diesel_Tx" SG_ 853 RHS_Cond_Seat_Status 1;
BA_ "U_CD4_MY13_Gas_Tx" SG_ 853 RHS_Cond_Seat_Status 1;
BA_ "U_CD4_MY13_Hev_Tx" SG_ 853 RHS_Cond_Seat_Status 1;
BA_ "U_CD4_MY13_Phev_Tx" SG_ 853 RHS_Cond_Seat_Status 1;
BA_ "U_CD42_MY14_Diesel_Tx" SG_ 853 RHS_Cond_Seat_Status 1;
BA_ "U_CD42_MY14_Gas_Tx" SG_ 853 RHS_Cond_Seat_Status 1;
BA_ "U_P552_MY15_Gas_Tx" SG_ 853 RHS_Cond_Seat_Status 1;
BA_ "U_S550_MY15_Gas_Tx" SG_ 853 RHS_Cond_Seat_Status 1;
BA_ "U_C489_MY14_Gas_Tx" SG_ 853 RHS_Cond_Seat_Status 1;
BA_ "U_U502_MY15_Gas_Tx" SG_ 853 RHS_Cond_Seat_Status 1;
BA_ "U_UP375_MY15_Gas_Tx" SG_ 853 RHS_Cond_Seat_Status 1;
BA_ "U_UP375_MY15_Diesel_Tx" SG_ 853 RHS_Cond_Seat_Status 1;
BA_ "U_CD43_MY16_Gas_Tx" SG_ 853 RHS_Cond_Seat_Status 1;
BA_ "CrossOver_InfoCAN" SG_ 853 LHS_Cond_Seat_Status 1;
BA_ "GenSigSendType" SG_ 853 LHS_Cond_Seat_Status 3;
BA_ "U_CD4_MY13_Diesel_Tx" SG_ 853 LHS_Cond_Seat_Status 1;
BA_ "U_CD4_MY13_Gas_Tx" SG_ 853 LHS_Cond_Seat_Status 1;
BA_ "U_CD4_MY13_Hev_Tx" SG_ 853 LHS_Cond_Seat_Status 1;
BA_ "U_CD4_MY13_Phev_Tx" SG_ 853 LHS_Cond_Seat_Status 1;
BA_ "U_CD42_MY14_Diesel_Tx" SG_ 853 LHS_Cond_Seat_Status 1;
BA_ "U_CD42_MY14_Gas_Tx" SG_ 853 LHS_Cond_Seat_Status 1;
BA_ "U_P552_MY15_Gas_Tx" SG_ 853 LHS_Cond_Seat_Status 1;
BA_ "U_S550_MY15_Gas_Tx" SG_ 853 LHS_Cond_Seat_Status 1;
BA_ "U_C489_MY14_Gas_Tx" SG_ 853 LHS_Cond_Seat_Status 1;
BA_ "U_U502_MY15_Gas_Tx" SG_ 853 LHS_Cond_Seat_Status 1;
BA_ "U_UP375_MY15_Gas_Tx" SG_ 853 LHS_Cond_Seat_Status 1;
BA_ "U_UP375_MY15_Diesel_Tx" SG_ 853 LHS_Cond_Seat_Status 1;
BA_ "U_CD43_MY16_Gas_Tx" SG_ 853 LHS_Cond_Seat_Status 1;
BA_ "CrossOver_InfoCAN" SG_ 853 Htd_Strg_Whl_Status 1;
BA_ "GenSigStartValue" SG_ 853 Htd_Strg_Whl_Status 2;
BA_ "GenSigSendType" SG_ 853 Htd_Strg_Whl_Status 3;
BA_ "U_CD4_MY13_Diesel_Tx" SG_ 853 Htd_Strg_Whl_Status 1;
BA_ "U_CD4_MY13_Gas_Tx" SG_ 853 Htd_Strg_Whl_Status 1;
BA_ "U_CD4_MY13_Hev_Tx" SG_ 853 Htd_Strg_Whl_Status 1;
BA_ "U_CD4_MY13_Phev_Tx" SG_ 853 Htd_Strg_Whl_Status 1;
BA_ "U_CD42_MY14_Diesel_Tx" SG_ 853 Htd_Strg_Whl_Status 1;
BA_ "U_CD42_MY14_Gas_Tx" SG_ 853 Htd_Strg_Whl_Status 1;
BA_ "U_P552_MY15_Gas_Tx" SG_ 853 Htd_Strg_Whl_Status 1;
BA_ "U_S550_MY15_Gas_Tx" SG_ 853 Htd_Strg_Whl_Status 1;
BA_ "U_C489_MY14_Gas_Tx" SG_ 853 Htd_Strg_Whl_Status 1;
BA_ "U_U502_MY15_Gas_Tx" SG_ 853 Htd_Strg_Whl_Status 1;
BA_ "U_UP375_MY15_Gas_Tx" SG_ 853 Htd_Strg_Whl_Status 1;
BA_ "U_UP375_MY15_Diesel_Tx" SG_ 853 Htd_Strg_Whl_Status 1;
BA_ "U_CD43_MY16_Gas_Tx" SG_ 853 Htd_Strg_Whl_Status 1;
BA_ "CrossOver_InfoCAN" SG_ 853 Htd_Strg_Whl_Btn_Stt 1;
BA_ "GenSigStartValue" SG_ 853 Htd_Strg_Whl_Btn_Stt 2;
BA_ "GenSigSendType" SG_ 853 Htd_Strg_Whl_Btn_Stt 3;
BA_ "U_CD4_MY13_Diesel_Tx" SG_ 853 Htd_Strg_Whl_Btn_Stt 1;
BA_ "U_CD4_MY13_Gas_Tx" SG_ 853 Htd_Strg_Whl_Btn_Stt 1;
BA_ "U_CD4_MY13_Hev_Tx" SG_ 853 Htd_Strg_Whl_Btn_Stt 1;
BA_ "U_CD4_MY13_Phev_Tx" SG_ 853 Htd_Strg_Whl_Btn_Stt 1;
BA_ "U_CD42_MY14_Diesel_Tx" SG_ 853 Htd_Strg_Whl_Btn_Stt 1;
BA_ "U_CD42_MY14_Gas_Tx" SG_ 853 Htd_Strg_Whl_Btn_Stt 1;
BA_ "U_P552_MY15_Gas_Tx" SG_ 853 Htd_Strg_Whl_Btn_Stt 1;
BA_ "U_S550_MY15_Gas_Tx" SG_ 853 Htd_Strg_Whl_Btn_Stt 1;
BA_ "U_C489_MY14_Gas_Tx" SG_ 853 Htd_Strg_Whl_Btn_Stt 1;
BA_ "U_U502_MY15_Gas_Tx" SG_ 853 Htd_Strg_Whl_Btn_Stt 1;
BA_ "U_UP375_MY15_Gas_Tx" SG_ 853 Htd_Strg_Whl_Btn_Stt 1;
BA_ "U_UP375_MY15_Diesel_Tx" SG_ 853 Htd_Strg_Whl_Btn_Stt 1;
BA_ "U_CD43_MY16_Gas_Tx" SG_ 853 Htd_Strg_Whl_Btn_Stt 1;
BA_ "CrossOver_InfoCAN" SG_ 853 Defrost_Btn_Stt 1;
BA_ "GenSigStartValue" SG_ 853 Defrost_Btn_Stt 2;
BA_ "GenSigSendType" SG_ 853 Defrost_Btn_Stt 3;
BA_ "U_CD4_MY13_Diesel_Tx" SG_ 853 Defrost_Btn_Stt 1;
BA_ "U_CD4_MY13_Gas_Tx" SG_ 853 Defrost_Btn_Stt 1;
BA_ "U_CD4_MY13_Hev_Tx" SG_ 853 Defrost_Btn_Stt 1;
BA_ "U_CD4_MY13_Phev_Tx" SG_ 853 Defrost_Btn_Stt 1;
BA_ "U_CD42_MY14_Diesel_Tx" SG_ 853 Defrost_Btn_Stt 1;
BA_ "U_CD42_MY14_Gas_Tx" SG_ 853 Defrost_Btn_Stt 1;
BA_ "U_P552_MY15_Gas_Tx" SG_ 853 Defrost_Btn_Stt 1;
BA_ "U_S550_MY15_Gas_Tx" SG_ 853 Defrost_Btn_Stt 1;
BA_ "U_C489_MY14_Gas_Tx" SG_ 853 Defrost_Btn_Stt 1;
BA_ "U_U502_MY15_Gas_Tx" SG_ 853 Defrost_Btn_Stt 1;
BA_ "U_UP375_MY15_Gas_Tx" SG_ 853 Defrost_Btn_Stt 1;
BA_ "U_UP375_MY15_Diesel_Tx" SG_ 853 Defrost_Btn_Stt 1;
BA_ "U_CD43_MY16_Gas_Tx" SG_ 853 Defrost_Btn_Stt 1;
BA_ "CrossOver_InfoCAN" SG_ 853 CC_Fr_Btn_User_Adj 1;
BA_ "GenSigSendType" SG_ 853 CC_Fr_Btn_User_Adj 3;
BA_ "U_CD4_MY13_Diesel_Tx" SG_ 853 CC_Fr_Btn_User_Adj 1;
BA_ "U_CD4_MY13_Gas_Tx" SG_ 853 CC_Fr_Btn_User_Adj 1;
BA_ "U_CD4_MY13_Hev_Tx" SG_ 853 CC_Fr_Btn_User_Adj 1;
BA_ "U_CD4_MY13_Phev_Tx" SG_ 853 CC_Fr_Btn_User_Adj 1;
BA_ "U_CD42_MY14_Diesel_Tx" SG_ 853 CC_Fr_Btn_User_Adj 1;
BA_ "U_CD42_MY14_Gas_Tx" SG_ 853 CC_Fr_Btn_User_Adj 1;
BA_ "U_P552_MY15_Gas_Tx" SG_ 853 CC_Fr_Btn_User_Adj 1;
BA_ "U_S550_MY15_Gas_Tx" SG_ 853 CC_Fr_Btn_User_Adj 1;
BA_ "U_C489_MY14_Gas_Tx" SG_ 853 CC_Fr_Btn_User_Adj 1;
BA_ "U_U502_MY15_Gas_Tx" SG_ 853 CC_Fr_Btn_User_Adj 1;
BA_ "U_UP375_MY15_Gas_Tx" SG_ 853 CC_Fr_Btn_User_Adj 1;
BA_ "U_UP375_MY15_Diesel_Tx" SG_ 853 CC_Fr_Btn_User_Adj 1;
BA_ "U_CD43_MY16_Gas_Tx" SG_ 853 CC_Fr_Btn_User_Adj 1;
BA_ "CrossOver_InfoCAN" SG_ 853 RHS_Htd_Seat_Btn_Stt 1;
BA_ "GenSigStartValue" SG_ 853 RHS_Htd_Seat_Btn_Stt 2;
BA_ "GenSigSendType" SG_ 853 RHS_Htd_Seat_Btn_Stt 3;
BA_ "U_CD4_MY13_Diesel_Tx" SG_ 853 RHS_Htd_Seat_Btn_Stt 1;
BA_ "U_CD4_MY13_Gas_Tx" SG_ 853 RHS_Htd_Seat_Btn_Stt 1;
BA_ "U_CD4_MY13_Hev_Tx" SG_ 853 RHS_Htd_Seat_Btn_Stt 1;
BA_ "U_CD4_MY13_Phev_Tx" SG_ 853 RHS_Htd_Seat_Btn_Stt 1;
BA_ "U_CD42_MY14_Diesel_Tx" SG_ 853 RHS_Htd_Seat_Btn_Stt 1;
BA_ "U_CD42_MY14_Gas_Tx" SG_ 853 RHS_Htd_Seat_Btn_Stt 1;
BA_ "U_P552_MY15_Gas_Tx" SG_ 853 RHS_Htd_Seat_Btn_Stt 1;
BA_ "U_S550_MY15_Gas_Tx" SG_ 853 RHS_Htd_Seat_Btn_Stt 1;
BA_ "U_C489_MY14_Gas_Tx" SG_ 853 RHS_Htd_Seat_Btn_Stt 1;
BA_ "U_U502_MY15_Gas_Tx" SG_ 853 RHS_Htd_Seat_Btn_Stt 1;
BA_ "U_UP375_MY15_Gas_Tx" SG_ 853 RHS_Htd_Seat_Btn_Stt 1;
BA_ "U_UP375_MY15_Diesel_Tx" SG_ 853 RHS_Htd_Seat_Btn_Stt 1;
BA_ "U_CD43_MY16_Gas_Tx" SG_ 853 RHS_Htd_Seat_Btn_Stt 1;
BA_ "CrossOver_InfoCAN" SG_ 853 RHS_Cld_Seat_Btn_Stt 1;
BA_ "GenSigStartValue" SG_ 853 RHS_Cld_Seat_Btn_Stt 2;
BA_ "GenSigSendType" SG_ 853 RHS_Cld_Seat_Btn_Stt 3;
BA_ "U_CD4_MY13_Diesel_Tx" SG_ 853 RHS_Cld_Seat_Btn_Stt 1;
BA_ "U_CD4_MY13_Gas_Tx" SG_ 853 RHS_Cld_Seat_Btn_Stt 1;
BA_ "U_CD4_MY13_Hev_Tx" SG_ 853 RHS_Cld_Seat_Btn_Stt 1;
BA_ "U_CD4_MY13_Phev_Tx" SG_ 853 RHS_Cld_Seat_Btn_Stt 1;
BA_ "U_CD42_MY14_Diesel_Tx" SG_ 853 RHS_Cld_Seat_Btn_Stt 1;
BA_ "U_CD42_MY14_Gas_Tx" SG_ 853 RHS_Cld_Seat_Btn_Stt 1;
BA_ "U_P552_MY15_Gas_Tx" SG_ 853 RHS_Cld_Seat_Btn_Stt 1;
BA_ "U_S550_MY15_Gas_Tx" SG_ 853 RHS_Cld_Seat_Btn_Stt 1;
BA_ "U_C489_MY14_Gas_Tx" SG_ 853 RHS_Cld_Seat_Btn_Stt 1;
BA_ "U_U502_MY15_Gas_Tx" SG_ 853 RHS_Cld_Seat_Btn_Stt 1;
BA_ "U_UP375_MY15_Gas_Tx" SG_ 853 RHS_Cld_Seat_Btn_Stt 1;
BA_ "U_UP375_MY15_Diesel_Tx" SG_ 853 RHS_Cld_Seat_Btn_Stt 1;
BA_ "U_CD43_MY16_Gas_Tx" SG_ 853 RHS_Cld_Seat_Btn_Stt 1;
BA_ "CrossOver_InfoCAN" SG_ 853 Outside_Btn_Stt 1;
BA_ "GenSigStartValue" SG_ 853 Outside_Btn_Stt 2;
BA_ "GenSigSendType" SG_ 853 Outside_Btn_Stt 3;
BA_ "U_CD4_MY13_Diesel_Tx" SG_ 853 Outside_Btn_Stt 1;
BA_ "U_CD4_MY13_Gas_Tx" SG_ 853 Outside_Btn_Stt 1;
BA_ "U_CD4_MY13_Hev_Tx" SG_ 853 Outside_Btn_Stt 1;
BA_ "U_CD4_MY13_Phev_Tx" SG_ 853 Outside_Btn_Stt 1;
BA_ "U_CD42_MY14_Diesel_Tx" SG_ 853 Outside_Btn_Stt 1;
BA_ "U_CD42_MY14_Gas_Tx" SG_ 853 Outside_Btn_Stt 1;
BA_ "U_P552_MY15_Gas_Tx" SG_ 853 Outside_Btn_Stt 1;
BA_ "U_S550_MY15_Gas_Tx" SG_ 853 Outside_Btn_Stt 1;
BA_ "U_C489_MY14_Gas_Tx" SG_ 853 Outside_Btn_Stt 1;
BA_ "U_U502_MY15_Gas_Tx" SG_ 853 Outside_Btn_Stt 1;
BA_ "U_UP375_MY15_Gas_Tx" SG_ 853 Outside_Btn_Stt 1;
BA_ "U_UP375_MY15_Diesel_Tx" SG_ 853 Outside_Btn_Stt 1;
BA_ "U_CD43_MY16_Gas_Tx" SG_ 853 Outside_Btn_Stt 1;
BA_ "CrossOver_InfoCAN" SG_ 853 LHS_Htd_Seat_Btn_Stt 1;
BA_ "GenSigStartValue" SG_ 853 LHS_Htd_Seat_Btn_Stt 2;
BA_ "GenSigSendType" SG_ 853 LHS_Htd_Seat_Btn_Stt 3;
BA_ "U_CD4_MY13_Diesel_Tx" SG_ 853 LHS_Htd_Seat_Btn_Stt 1;
BA_ "U_CD4_MY13_Gas_Tx" SG_ 853 LHS_Htd_Seat_Btn_Stt 1;
BA_ "U_CD4_MY13_Hev_Tx" SG_ 853 LHS_Htd_Seat_Btn_Stt 1;
BA_ "U_CD4_MY13_Phev_Tx" SG_ 853 LHS_Htd_Seat_Btn_Stt 1;
BA_ "U_CD42_MY14_Diesel_Tx" SG_ 853 LHS_Htd_Seat_Btn_Stt 1;
BA_ "U_CD42_MY14_Gas_Tx" SG_ 853 LHS_Htd_Seat_Btn_Stt 1;
BA_ "U_P552_MY15_Gas_Tx" SG_ 853 LHS_Htd_Seat_Btn_Stt 1;
BA_ "U_S550_MY15_Gas_Tx" SG_ 853 LHS_Htd_Seat_Btn_Stt 1;
BA_ "U_C489_MY14_Gas_Tx" SG_ 853 LHS_Htd_Seat_Btn_Stt 1;
BA_ "U_U502_MY15_Gas_Tx" SG_ 853 LHS_Htd_Seat_Btn_Stt 1;
BA_ "U_UP375_MY15_Gas_Tx" SG_ 853 LHS_Htd_Seat_Btn_Stt 1;
BA_ "U_UP375_MY15_Diesel_Tx" SG_ 853 LHS_Htd_Seat_Btn_Stt 1;
BA_ "U_CD43_MY16_Gas_Tx" SG_ 853 LHS_Htd_Seat_Btn_Stt 1;
BA_ "CrossOver_InfoCAN" SG_ 853 LHS_Cld_Seat_Btn_Stt 1;
BA_ "GenSigStartValue" SG_ 853 LHS_Cld_Seat_Btn_Stt 2;
BA_ "GenSigSendType" SG_ 853 LHS_Cld_Seat_Btn_Stt 3;
BA_ "U_CD4_MY13_Diesel_Tx" SG_ 853 LHS_Cld_Seat_Btn_Stt 1;
BA_ "U_CD4_MY13_Gas_Tx" SG_ 853 LHS_Cld_Seat_Btn_Stt 1;
BA_ "U_CD4_MY13_Hev_Tx" SG_ 853 LHS_Cld_Seat_Btn_Stt 1;
BA_ "U_CD4_MY13_Phev_Tx" SG_ 853 LHS_Cld_Seat_Btn_Stt 1;
BA_ "U_CD42_MY14_Diesel_Tx" SG_ 853 LHS_Cld_Seat_Btn_Stt 1;
BA_ "U_CD42_MY14_Gas_Tx" SG_ 853 LHS_Cld_Seat_Btn_Stt 1;
BA_ "U_P552_MY15_Gas_Tx" SG_ 853 LHS_Cld_Seat_Btn_Stt 1;
BA_ "U_S550_MY15_Gas_Tx" SG_ 853 LHS_Cld_Seat_Btn_Stt 1;
BA_ "U_C489_MY14_Gas_Tx" SG_ 853 LHS_Cld_Seat_Btn_Stt 1;
BA_ "U_U502_MY15_Gas_Tx" SG_ 853 LHS_Cld_Seat_Btn_Stt 1;
BA_ "U_UP375_MY15_Gas_Tx" SG_ 853 LHS_Cld_Seat_Btn_Stt 1;
BA_ "U_UP375_MY15_Diesel_Tx" SG_ 853 LHS_Cld_Seat_Btn_Stt 1;
BA_ "U_CD43_MY16_Gas_Tx" SG_ 853 LHS_Cld_Seat_Btn_Stt 1;
BA_ "CrossOver_InfoCAN" SG_ 853 Htd_Frt_Wsh_Btn_Stt 1;
BA_ "GenSigStartValue" SG_ 853 Htd_Frt_Wsh_Btn_Stt 2;
BA_ "GenSigSendType" SG_ 853 Htd_Frt_Wsh_Btn_Stt 3;
BA_ "U_CD4_MY13_Diesel_Tx" SG_ 853 Htd_Frt_Wsh_Btn_Stt 1;
BA_ "U_CD4_MY13_Gas_Tx" SG_ 853 Htd_Frt_Wsh_Btn_Stt 1;
BA_ "U_CD4_MY13_Hev_Tx" SG_ 853 Htd_Frt_Wsh_Btn_Stt 1;
BA_ "U_CD4_MY13_Phev_Tx" SG_ 853 Htd_Frt_Wsh_Btn_Stt 1;
BA_ "U_CD42_MY14_Diesel_Tx" SG_ 853 Htd_Frt_Wsh_Btn_Stt 1;
BA_ "U_CD42_MY14_Gas_Tx" SG_ 853 Htd_Frt_Wsh_Btn_Stt 1;
BA_ "U_P552_MY15_Gas_Tx" SG_ 853 Htd_Frt_Wsh_Btn_Stt 1;
BA_ "U_S550_MY15_Gas_Tx" SG_ 853 Htd_Frt_Wsh_Btn_Stt 1;
BA_ "U_C489_MY14_Gas_Tx" SG_ 853 Htd_Frt_Wsh_Btn_Stt 1;
BA_ "U_U502_MY15_Gas_Tx" SG_ 853 Htd_Frt_Wsh_Btn_Stt 1;
BA_ "U_UP375_MY15_Gas_Tx" SG_ 853 Htd_Frt_Wsh_Btn_Stt 1;
BA_ "U_UP375_MY15_Diesel_Tx" SG_ 853 Htd_Frt_Wsh_Btn_Stt 1;
BA_ "U_CD43_MY16_Gas_Tx" SG_ 853 Htd_Frt_Wsh_Btn_Stt 1;
BA_ "CrossOver_InfoCAN" SG_ 853 Auto_Recirc_Btn_Stt 1;
BA_ "GenSigStartValue" SG_ 853 Auto_Recirc_Btn_Stt 2;
BA_ "GenSigSendType" SG_ 853 Auto_Recirc_Btn_Stt 3;
BA_ "U_CD4_MY13_Diesel_Tx" SG_ 853 Auto_Recirc_Btn_Stt 1;
BA_ "U_CD4_MY13_Gas_Tx" SG_ 853 Auto_Recirc_Btn_Stt 1;
BA_ "U_CD4_MY13_Hev_Tx" SG_ 853 Auto_Recirc_Btn_Stt 1;
BA_ "U_CD4_MY13_Phev_Tx" SG_ 853 Auto_Recirc_Btn_Stt 1;
BA_ "U_CD42_MY14_Diesel_Tx" SG_ 853 Auto_Recirc_Btn_Stt 1;
BA_ "U_CD42_MY14_Gas_Tx" SG_ 853 Auto_Recirc_Btn_Stt 1;
BA_ "U_P552_MY15_Gas_Tx" SG_ 853 Auto_Recirc_Btn_Stt 1;
BA_ "U_S550_MY15_Gas_Tx" SG_ 853 Auto_Recirc_Btn_Stt 1;
BA_ "U_C489_MY14_Gas_Tx" SG_ 853 Auto_Recirc_Btn_Stt 1;
BA_ "U_U502_MY15_Gas_Tx" SG_ 853 Auto_Recirc_Btn_Stt 1;
BA_ "U_UP375_MY15_Gas_Tx" SG_ 853 Auto_Recirc_Btn_Stt 1;
BA_ "U_UP375_MY15_Diesel_Tx" SG_ 853 Auto_Recirc_Btn_Stt 1;
BA_ "U_CD43_MY16_Gas_Tx" SG_ 853 Auto_Recirc_Btn_Stt 1;
BA_ "CrossOver_InfoCAN" SG_ 853 Recirc_Btn_Stt 1;
BA_ "GenSigStartValue" SG_ 853 Recirc_Btn_Stt 2;
BA_ "GenSigSendType" SG_ 853 Recirc_Btn_Stt 3;
BA_ "U_CD4_MY13_Diesel_Tx" SG_ 853 Recirc_Btn_Stt 1;
BA_ "U_CD4_MY13_Gas_Tx" SG_ 853 Recirc_Btn_Stt 1;
BA_ "U_CD4_MY13_Hev_Tx" SG_ 853 Recirc_Btn_Stt 1;
BA_ "U_CD4_MY13_Phev_Tx" SG_ 853 Recirc_Btn_Stt 1;
BA_ "U_CD42_MY14_Diesel_Tx" SG_ 853 Recirc_Btn_Stt 1;
BA_ "U_CD42_MY14_Gas_Tx" SG_ 853 Recirc_Btn_Stt 1;
BA_ "U_P552_MY15_Gas_Tx" SG_ 853 Recirc_Btn_Stt 1;
BA_ "U_S550_MY15_Gas_Tx" SG_ 853 Recirc_Btn_Stt 1;
BA_ "U_C489_MY14_Gas_Tx" SG_ 853 Recirc_Btn_Stt 1;
BA_ "U_U502_MY15_Gas_Tx" SG_ 853 Recirc_Btn_Stt 1;
BA_ "U_UP375_MY15_Gas_Tx" SG_ 853 Recirc_Btn_Stt 1;
BA_ "U_UP375_MY15_Diesel_Tx" SG_ 853 Recirc_Btn_Stt 1;
BA_ "U_CD43_MY16_Gas_Tx" SG_ 853 Recirc_Btn_Stt 1;
BA_ "CrossOver_InfoCAN" SG_ 853 Rear_Defrost_Btn_Stt 1;
BA_ "GenSigStartValue" SG_ 853 Rear_Defrost_Btn_Stt 2;
BA_ "GenSigSendType" SG_ 853 Rear_Defrost_Btn_Stt 3;
BA_ "U_CD4_MY13_Diesel_Tx" SG_ 853 Rear_Defrost_Btn_Stt 1;
BA_ "U_CD4_MY13_Gas_Tx" SG_ 853 Rear_Defrost_Btn_Stt 1;
BA_ "U_CD4_MY13_Hev_Tx" SG_ 853 Rear_Defrost_Btn_Stt 1;
BA_ "U_CD4_MY13_Phev_Tx" SG_ 853 Rear_Defrost_Btn_Stt 1;
BA_ "U_CD42_MY14_Diesel_Tx" SG_ 853 Rear_Defrost_Btn_Stt 1;
BA_ "U_CD42_MY14_Gas_Tx" SG_ 853 Rear_Defrost_Btn_Stt 1;
BA_ "U_P552_MY15_Gas_Tx" SG_ 853 Rear_Defrost_Btn_Stt 1;
BA_ "U_S550_MY15_Gas_Tx" SG_ 853 Rear_Defrost_Btn_Stt 1;
BA_ "U_C489_MY14_Gas_Tx" SG_ 853 Rear_Defrost_Btn_Stt 1;
BA_ "U_U502_MY15_Gas_Tx" SG_ 853 Rear_Defrost_Btn_Stt 1;
BA_ "U_UP375_MY15_Gas_Tx" SG_ 853 Rear_Defrost_Btn_Stt 1;
BA_ "U_UP375_MY15_Diesel_Tx" SG_ 853 Rear_Defrost_Btn_Stt 1;
BA_ "U_CD43_MY16_Gas_Tx" SG_ 853 Rear_Defrost_Btn_Stt 1;
BA_ "CrossOver_InfoCAN" SG_ 853 My_Temp_Btn_Stt 1;
BA_ "GenSigStartValue" SG_ 853 My_Temp_Btn_Stt 2;
BA_ "GenSigSendType" SG_ 853 My_Temp_Btn_Stt 3;
BA_ "U_CD4_MY13_Diesel_Tx" SG_ 853 My_Temp_Btn_Stt 1;
BA_ "U_CD4_MY13_Gas_Tx" SG_ 853 My_Temp_Btn_Stt 1;
BA_ "U_CD4_MY13_Hev_Tx" SG_ 853 My_Temp_Btn_Stt 1;
BA_ "U_CD4_MY13_Phev_Tx" SG_ 853 My_Temp_Btn_Stt 1;
BA_ "U_CD42_MY14_Diesel_Tx" SG_ 853 My_Temp_Btn_Stt 1;
BA_ "U_CD42_MY14_Gas_Tx" SG_ 853 My_Temp_Btn_Stt 1;
BA_ "U_P552_MY15_Gas_Tx" SG_ 853 My_Temp_Btn_Stt 1;
BA_ "U_S550_MY15_Gas_Tx" SG_ 853 My_Temp_Btn_Stt 1;
BA_ "U_C489_MY14_Gas_Tx" SG_ 853 My_Temp_Btn_Stt 1;
BA_ "U_U502_MY15_Gas_Tx" SG_ 853 My_Temp_Btn_Stt 1;
BA_ "U_UP375_MY15_Gas_Tx" SG_ 853 My_Temp_Btn_Stt 1;
BA_ "U_UP375_MY15_Diesel_Tx" SG_ 853 My_Temp_Btn_Stt 1;
BA_ "U_CD43_MY16_Gas_Tx" SG_ 853 My_Temp_Btn_Stt 1;
BA_ "CrossOver_InfoCAN" SG_ 853 Max_Defrost_Btn_Stt 1;
BA_ "GenSigStartValue" SG_ 853 Max_Defrost_Btn_Stt 2;
BA_ "GenSigSendType" SG_ 853 Max_Defrost_Btn_Stt 3;
BA_ "U_CD4_MY13_Diesel_Tx" SG_ 853 Max_Defrost_Btn_Stt 1;
BA_ "U_CD4_MY13_Gas_Tx" SG_ 853 Max_Defrost_Btn_Stt 1;
BA_ "U_CD4_MY13_Hev_Tx" SG_ 853 Max_Defrost_Btn_Stt 1;
BA_ "U_CD4_MY13_Phev_Tx" SG_ 853 Max_Defrost_Btn_Stt 1;
BA_ "U_CD42_MY14_Diesel_Tx" SG_ 853 Max_Defrost_Btn_Stt 1;
BA_ "U_CD42_MY14_Gas_Tx" SG_ 853 Max_Defrost_Btn_Stt 1;
BA_ "U_P552_MY15_Gas_Tx" SG_ 853 Max_Defrost_Btn_Stt 1;
BA_ "U_S550_MY15_Gas_Tx" SG_ 853 Max_Defrost_Btn_Stt 1;
BA_ "U_C489_MY14_Gas_Tx" SG_ 853 Max_Defrost_Btn_Stt 1;
BA_ "U_U502_MY15_Gas_Tx" SG_ 853 Max_Defrost_Btn_Stt 1;
BA_ "U_UP375_MY15_Gas_Tx" SG_ 853 Max_Defrost_Btn_Stt 1;
BA_ "U_UP375_MY15_Diesel_Tx" SG_ 853 Max_Defrost_Btn_Stt 1;
BA_ "U_CD43_MY16_Gas_Tx" SG_ 853 Max_Defrost_Btn_Stt 1;
BA_ "CrossOver_InfoCAN" SG_ 853 Max_AC_Btn_Stt 1;
BA_ "GenSigStartValue" SG_ 853 Max_AC_Btn_Stt 2;
BA_ "GenSigSendType" SG_ 853 Max_AC_Btn_Stt 3;
BA_ "U_CD4_MY13_Diesel_Tx" SG_ 853 Max_AC_Btn_Stt 1;
BA_ "U_CD4_MY13_Gas_Tx" SG_ 853 Max_AC_Btn_Stt 1;
BA_ "U_CD4_MY13_Hev_Tx" SG_ 853 Max_AC_Btn_Stt 1;
BA_ "U_CD4_MY13_Phev_Tx" SG_ 853 Max_AC_Btn_Stt 1;
BA_ "U_CD42_MY14_Diesel_Tx" SG_ 853 Max_AC_Btn_Stt 1;
BA_ "U_CD42_MY14_Gas_Tx" SG_ 853 Max_AC_Btn_Stt 1;
BA_ "U_P552_MY15_Gas_Tx" SG_ 853 Max_AC_Btn_Stt 1;
BA_ "U_S550_MY15_Gas_Tx" SG_ 853 Max_AC_Btn_Stt 1;
BA_ "U_C489_MY14_Gas_Tx" SG_ 853 Max_AC_Btn_Stt 1;
BA_ "U_U502_MY15_Gas_Tx" SG_ 853 Max_AC_Btn_Stt 1;
BA_ "U_UP375_MY15_Gas_Tx" SG_ 853 Max_AC_Btn_Stt 1;
BA_ "U_UP375_MY15_Diesel_Tx" SG_ 853 Max_AC_Btn_Stt 1;
BA_ "U_CD43_MY16_Gas_Tx" SG_ 853 Max_AC_Btn_Stt 1;
BA_ "CrossOver_InfoCAN" SG_ 853 Front_AUTO_Label 1;
BA_ "GenSigStartValue" SG_ 853 Front_AUTO_Label 2;
BA_ "GenSigSendType" SG_ 853 Front_AUTO_Label 3;
BA_ "U_CD4_MY13_Diesel_Tx" SG_ 853 Front_AUTO_Label 1;
BA_ "U_CD4_MY13_Gas_Tx" SG_ 853 Front_AUTO_Label 1;
BA_ "U_CD4_MY13_Hev_Tx" SG_ 853 Front_AUTO_Label 1;
BA_ "U_CD4_MY13_Phev_Tx" SG_ 853 Front_AUTO_Label 1;
BA_ "U_CD42_MY14_Diesel_Tx" SG_ 853 Front_AUTO_Label 1;
BA_ "U_CD42_MY14_Gas_Tx" SG_ 853 Front_AUTO_Label 1;
BA_ "U_P552_MY15_Gas_Tx" SG_ 853 Front_AUTO_Label 1;
BA_ "U_S550_MY15_Gas_Tx" SG_ 853 Front_AUTO_Label 1;
BA_ "U_C489_MY14_Gas_Tx" SG_ 853 Front_AUTO_Label 1;
BA_ "U_U502_MY15_Gas_Tx" SG_ 853 Front_AUTO_Label 1;
BA_ "U_UP375_MY15_Gas_Tx" SG_ 853 Front_AUTO_Label 1;
BA_ "U_UP375_MY15_Diesel_Tx" SG_ 853 Front_AUTO_Label 1;
BA_ "U_CD43_MY16_Gas_Tx" SG_ 853 Front_AUTO_Label 1;
BA_ "CrossOver_InfoCAN" SG_ 853 Windscreen_Btn_Stt 1;
BA_ "GenSigStartValue" SG_ 853 Windscreen_Btn_Stt 2;
BA_ "GenSigSendType" SG_ 853 Windscreen_Btn_Stt 3;
BA_ "U_CD4_MY13_Diesel_Tx" SG_ 853 Windscreen_Btn_Stt 1;
BA_ "U_CD4_MY13_Gas_Tx" SG_ 853 Windscreen_Btn_Stt 1;
BA_ "U_CD4_MY13_Hev_Tx" SG_ 853 Windscreen_Btn_Stt 1;
BA_ "U_CD4_MY13_Phev_Tx" SG_ 853 Windscreen_Btn_Stt 1;
BA_ "U_CD42_MY14_Diesel_Tx" SG_ 853 Windscreen_Btn_Stt 1;
BA_ "U_CD42_MY14_Gas_Tx" SG_ 853 Windscreen_Btn_Stt 1;
BA_ "U_P552_MY15_Gas_Tx" SG_ 853 Windscreen_Btn_Stt 1;
BA_ "U_S550_MY15_Gas_Tx" SG_ 853 Windscreen_Btn_Stt 1;
BA_ "U_C489_MY14_Gas_Tx" SG_ 853 Windscreen_Btn_Stt 1;
BA_ "U_U502_MY15_Gas_Tx" SG_ 853 Windscreen_Btn_Stt 1;
BA_ "U_UP375_MY15_Gas_Tx" SG_ 853 Windscreen_Btn_Stt 1;
BA_ "U_UP375_MY15_Diesel_Tx" SG_ 853 Windscreen_Btn_Stt 1;
BA_ "U_CD43_MY16_Gas_Tx" SG_ 853 Windscreen_Btn_Stt 1;
BA_ "CrossOver_InfoCAN" SG_ 853 Panel_Btn_Stt 1;
BA_ "GenSigStartValue" SG_ 853 Panel_Btn_Stt 2;
BA_ "GenSigSendType" SG_ 853 Panel_Btn_Stt 3;
BA_ "U_CD4_MY13_Diesel_Tx" SG_ 853 Panel_Btn_Stt 1;
BA_ "U_CD4_MY13_Gas_Tx" SG_ 853 Panel_Btn_Stt 1;
BA_ "U_CD4_MY13_Hev_Tx" SG_ 853 Panel_Btn_Stt 1;
BA_ "U_CD4_MY13_Phev_Tx" SG_ 853 Panel_Btn_Stt 1;
BA_ "U_CD42_MY14_Diesel_Tx" SG_ 853 Panel_Btn_Stt 1;
BA_ "U_CD42_MY14_Gas_Tx" SG_ 853 Panel_Btn_Stt 1;
BA_ "U_P552_MY15_Gas_Tx" SG_ 853 Panel_Btn_Stt 1;
BA_ "U_S550_MY15_Gas_Tx" SG_ 853 Panel_Btn_Stt 1;
BA_ "U_C489_MY14_Gas_Tx" SG_ 853 Panel_Btn_Stt 1;
BA_ "U_U502_MY15_Gas_Tx" SG_ 853 Panel_Btn_Stt 1;
BA_ "U_UP375_MY15_Gas_Tx" SG_ 853 Panel_Btn_Stt 1;
BA_ "U_UP375_MY15_Diesel_Tx" SG_ 853 Panel_Btn_Stt 1;
BA_ "U_CD43_MY16_Gas_Tx" SG_ 853 Panel_Btn_Stt 1;
BA_ "CrossOver_InfoCAN" SG_ 853 Front_Power_Btn_Stt 1;
BA_ "GenSigStartValue" SG_ 853 Front_Power_Btn_Stt 2;
BA_ "GenSigSendType" SG_ 853 Front_Power_Btn_Stt 3;
BA_ "U_CD4_MY13_Diesel_Tx" SG_ 853 Front_Power_Btn_Stt 1;
BA_ "U_CD4_MY13_Gas_Tx" SG_ 853 Front_Power_Btn_Stt 1;
BA_ "U_CD4_MY13_Hev_Tx" SG_ 853 Front_Power_Btn_Stt 1;
BA_ "U_CD4_MY13_Phev_Tx" SG_ 853 Front_Power_Btn_Stt 1;
BA_ "U_CD42_MY14_Diesel_Tx" SG_ 853 Front_Power_Btn_Stt 1;
BA_ "U_CD42_MY14_Gas_Tx" SG_ 853 Front_Power_Btn_Stt 1;
BA_ "U_P552_MY15_Gas_Tx" SG_ 853 Front_Power_Btn_Stt 1;
BA_ "U_S550_MY15_Gas_Tx" SG_ 853 Front_Power_Btn_Stt 1;
BA_ "U_C489_MY14_Gas_Tx" SG_ 853 Front_Power_Btn_Stt 1;
BA_ "U_U502_MY15_Gas_Tx" SG_ 853 Front_Power_Btn_Stt 1;
BA_ "U_UP375_MY15_Gas_Tx" SG_ 853 Front_Power_Btn_Stt 1;
BA_ "U_UP375_MY15_Diesel_Tx" SG_ 853 Front_Power_Btn_Stt 1;
BA_ "U_CD43_MY16_Gas_Tx" SG_ 853 Front_Power_Btn_Stt 1;
BA_ "CrossOver_InfoCAN" SG_ 853 Front_AUTO_Btn_Stt 1;
BA_ "GenSigStartValue" SG_ 853 Front_AUTO_Btn_Stt 2;
BA_ "GenSigSendType" SG_ 853 Front_AUTO_Btn_Stt 3;
BA_ "U_CD4_MY13_Diesel_Tx" SG_ 853 Front_AUTO_Btn_Stt 1;
BA_ "U_CD4_MY13_Gas_Tx" SG_ 853 Front_AUTO_Btn_Stt 1;
BA_ "U_CD4_MY13_Hev_Tx" SG_ 853 Front_AUTO_Btn_Stt 1;
BA_ "U_CD4_MY13_Phev_Tx" SG_ 853 Front_AUTO_Btn_Stt 1;
BA_ "U_CD42_MY14_Diesel_Tx" SG_ 853 Front_AUTO_Btn_Stt 1;
BA_ "U_CD42_MY14_Gas_Tx" SG_ 853 Front_AUTO_Btn_Stt 1;
BA_ "U_P552_MY15_Gas_Tx" SG_ 853 Front_AUTO_Btn_Stt 1;
BA_ "U_S550_MY15_Gas_Tx" SG_ 853 Front_AUTO_Btn_Stt 1;
BA_ "U_C489_MY14_Gas_Tx" SG_ 853 Front_AUTO_Btn_Stt 1;
BA_ "U_U502_MY15_Gas_Tx" SG_ 853 Front_AUTO_Btn_Stt 1;
BA_ "U_UP375_MY15_Gas_Tx" SG_ 853 Front_AUTO_Btn_Stt 1;
BA_ "U_UP375_MY15_Diesel_Tx" SG_ 853 Front_AUTO_Btn_Stt 1;
BA_ "U_CD43_MY16_Gas_Tx" SG_ 853 Front_AUTO_Btn_Stt 1;
BA_ "CrossOver_InfoCAN" SG_ 853 Floor_Btn_Stt 1;
BA_ "GenSigStartValue" SG_ 853 Floor_Btn_Stt 2;
BA_ "GenSigSendType" SG_ 853 Floor_Btn_Stt 3;
BA_ "U_CD4_MY13_Diesel_Tx" SG_ 853 Floor_Btn_Stt 1;
BA_ "U_CD4_MY13_Gas_Tx" SG_ 853 Floor_Btn_Stt 1;
BA_ "U_CD4_MY13_Hev_Tx" SG_ 853 Floor_Btn_Stt 1;
BA_ "U_CD4_MY13_Phev_Tx" SG_ 853 Floor_Btn_Stt 1;
BA_ "U_CD42_MY14_Diesel_Tx" SG_ 853 Floor_Btn_Stt 1;
BA_ "U_CD42_MY14_Gas_Tx" SG_ 853 Floor_Btn_Stt 1;
BA_ "U_P552_MY15_Gas_Tx" SG_ 853 Floor_Btn_Stt 1;
BA_ "U_S550_MY15_Gas_Tx" SG_ 853 Floor_Btn_Stt 1;
BA_ "U_C489_MY14_Gas_Tx" SG_ 853 Floor_Btn_Stt 1;
BA_ "U_U502_MY15_Gas_Tx" SG_ 853 Floor_Btn_Stt 1;
BA_ "U_UP375_MY15_Gas_Tx" SG_ 853 Floor_Btn_Stt 1;
BA_ "U_UP375_MY15_Diesel_Tx" SG_ 853 Floor_Btn_Stt 1;
BA_ "U_CD43_MY16_Gas_Tx" SG_ 853 Floor_Btn_Stt 1;
BA_ "CrossOver_InfoCAN" SG_ 853 Dual_Button_Stt 1;
BA_ "GenSigStartValue" SG_ 853 Dual_Button_Stt 2;
BA_ "GenSigSendType" SG_ 853 Dual_Button_Stt 3;
BA_ "U_CD4_MY13_Diesel_Tx" SG_ 853 Dual_Button_Stt 1;
BA_ "U_CD4_MY13_Gas_Tx" SG_ 853 Dual_Button_Stt 1;
BA_ "U_CD4_MY13_Hev_Tx" SG_ 853 Dual_Button_Stt 1;
BA_ "U_CD4_MY13_Phev_Tx" SG_ 853 Dual_Button_Stt 1;
BA_ "U_CD42_MY14_Diesel_Tx" SG_ 853 Dual_Button_Stt 1;
BA_ "U_CD42_MY14_Gas_Tx" SG_ 853 Dual_Button_Stt 1;
BA_ "U_P552_MY15_Gas_Tx" SG_ 853 Dual_Button_Stt 1;
BA_ "U_S550_MY15_Gas_Tx" SG_ 853 Dual_Button_Stt 1;
BA_ "U_C489_MY14_Gas_Tx" SG_ 853 Dual_Button_Stt 1;
BA_ "U_U502_MY15_Gas_Tx" SG_ 853 Dual_Button_Stt 1;
BA_ "U_UP375_MY15_Gas_Tx" SG_ 853 Dual_Button_Stt 1;
BA_ "U_UP375_MY15_Diesel_Tx" SG_ 853 Dual_Button_Stt 1;
BA_ "U_CD43_MY16_Gas_Tx" SG_ 853 Dual_Button_Stt 1;
BA_ "CrossOver_InfoCAN" SG_ 853 AC_Btn_Stt 1;
BA_ "GenSigStartValue" SG_ 853 AC_Btn_Stt 2;
BA_ "GenSigSendType" SG_ 853 AC_Btn_Stt 3;
BA_ "U_CD4_MY13_Diesel_Tx" SG_ 853 AC_Btn_Stt 1;
BA_ "U_CD4_MY13_Gas_Tx" SG_ 853 AC_Btn_Stt 1;
BA_ "U_CD4_MY13_Hev_Tx" SG_ 853 AC_Btn_Stt 1;
BA_ "U_CD4_MY13_Phev_Tx" SG_ 853 AC_Btn_Stt 1;
BA_ "U_CD42_MY14_Diesel_Tx" SG_ 853 AC_Btn_Stt 1;
BA_ "U_CD42_MY14_Gas_Tx" SG_ 853 AC_Btn_Stt 1;
BA_ "U_P552_MY15_Gas_Tx" SG_ 853 AC_Btn_Stt 1;
BA_ "U_S550_MY15_Gas_Tx" SG_ 853 AC_Btn_Stt 1;
BA_ "U_C489_MY14_Gas_Tx" SG_ 853 AC_Btn_Stt 1;
BA_ "U_U502_MY15_Gas_Tx" SG_ 853 AC_Btn_Stt 1;
BA_ "U_UP375_MY15_Gas_Tx" SG_ 853 AC_Btn_Stt 1;
BA_ "U_UP375_MY15_Diesel_Tx" SG_ 853 AC_Btn_Stt 1;
BA_ "U_CD43_MY16_Gas_Tx" SG_ 853 AC_Btn_Stt 1;
BA_ "CrossOver_InfoCAN" SG_ 1034 VehicleGGCCData 1;
BA_ "U_CD4_MY13_Diesel_Rx" SG_ 1034 VehicleGGCCData 1;
BA_ "U_CD4_MY13_Gas_Rx" SG_ 1034 VehicleGGCCData 1;
BA_ "U_CD4_MY13_Hev_Rx" SG_ 1034 VehicleGGCCData 1;
BA_ "U_CD4_MY13_Phev_Rx" SG_ 1034 VehicleGGCCData 1;
BA_ "U_CD42_MY14_Diesel_Rx" SG_ 1034 VehicleGGCCData 1;
BA_ "U_CD42_MY14_Gas_Rx" SG_ 1034 VehicleGGCCData 1;
BA_ "U_P552_MY15_Gas_Rx" SG_ 1034 VehicleGGCCData 1;
BA_ "U_S550_MY15_Gas_Rx" SG_ 1034 VehicleGGCCData 1;
BA_ "U_C489_MY14_Gas_Rx" SG_ 1034 VehicleGGCCData 1;
BA_ "U_B562LC_MY14_Gas_Rx" SG_ 1034 VehicleGGCCData 1;
BA_ "U_U502_MY15_Gas_Rx" SG_ 1034 VehicleGGCCData 1;
BA_ "U_UP375_MY15_Gas_Rx" SG_ 1034 VehicleGGCCData 1;
BA_ "U_UP375_MY15_Diesel_Rx" SG_ 1034 VehicleGGCCData 1;
BA_ "U_CD43_MY16_Gas_Rx" SG_ 1034 VehicleGGCCData 1;
BA_ "U_CD4_MY14_Diesel_Rx" SG_ 1034 VehicleGGCCData 1;
BA_ "U_CD4_MY14_Gas_Rx" SG_ 1034 VehicleGGCCData 1;
BA_ "U_CD4_MY14_Hev_Rx" SG_ 1034 VehicleGGCCData 1;
BA_ "U_CD4_MY14_Phev_Rx" SG_ 1034 VehicleGGCCData 1;
BA_ "CrossOver_InfoCAN" SG_ 956 SAPPStatusCoding_UB 1;
BA_ "U_CD4_MY13_Diesel_Rx" SG_ 956 SAPPStatusCoding_UB 1;
BA_ "U_CD4_MY13_Gas_Rx" SG_ 956 SAPPStatusCoding_UB 1;
BA_ "U_CD4_MY13_Hev_Rx" SG_ 956 SAPPStatusCoding_UB 1;
BA_ "U_CD4_MY13_Phev_Rx" SG_ 956 SAPPStatusCoding_UB 1;
BA_ "U_CD42_MY14_Diesel_Rx" SG_ 956 SAPPStatusCoding_UB 1;
BA_ "U_CD42_MY14_Gas_Rx" SG_ 956 SAPPStatusCoding_UB 1;
BA_ "U_P552_MY15_Gas_Rx" SG_ 956 SAPPStatusCoding_UB 1;
BA_ "U_S550_MY15_Gas_Rx" SG_ 956 SAPPStatusCoding_UB 1;
BA_ "U_C489_MY14_Gas_Rx" SG_ 956 SAPPStatusCoding_UB 1;
BA_ "U_B562LC_MY14_Gas_Rx" SG_ 956 SAPPStatusCoding_UB 1;
BA_ "U_U502_MY15_Gas_Rx" SG_ 956 SAPPStatusCoding_UB 1;
BA_ "U_UP375_MY15_Gas_Rx" SG_ 956 SAPPStatusCoding_UB 1;
BA_ "U_UP375_MY15_Diesel_Rx" SG_ 956 SAPPStatusCoding_UB 1;
BA_ "U_CD43_MY16_Gas_Rx" SG_ 956 SAPPStatusCoding_UB 1;
BA_ "GenSigMissingSourceValue" SG_ 956 SAPPStatusCoding 6;
BA_ "CrossOver_InfoCAN" SG_ 956 SAPPStatusCoding 1;
BA_ "CrossOver_LIN" SG_ 956 SAPPStatusCoding 1;
BA_ "U_CD4_MY13_Diesel_Rx" SG_ 956 SAPPStatusCoding 1;
BA_ "U_CD4_MY13_Gas_Rx" SG_ 956 SAPPStatusCoding 1;
BA_ "U_CD4_MY13_Hev_Rx" SG_ 956 SAPPStatusCoding 1;
BA_ "U_CD4_MY13_Phev_Rx" SG_ 956 SAPPStatusCoding 1;
BA_ "U_CD42_MY14_Diesel_Rx" SG_ 956 SAPPStatusCoding 1;
BA_ "U_CD42_MY14_Gas_Rx" SG_ 956 SAPPStatusCoding 1;
BA_ "U_P552_MY15_Gas_Rx" SG_ 956 SAPPStatusCoding 1;
BA_ "U_S550_MY15_Gas_Rx" SG_ 956 SAPPStatusCoding 1;
BA_ "U_C489_MY14_Gas_Rx" SG_ 956 SAPPStatusCoding 1;
BA_ "U_B562LC_MY14_Gas_Rx" SG_ 956 SAPPStatusCoding 1;
BA_ "U_U502_MY15_Gas_Rx" SG_ 956 SAPPStatusCoding 1;
BA_ "U_UP375_MY15_Gas_Rx" SG_ 956 SAPPStatusCoding 1;
BA_ "U_UP375_MY15_Diesel_Rx" SG_ 956 SAPPStatusCoding 1;
BA_ "U_CD43_MY16_Gas_Rx" SG_ 956 SAPPStatusCoding 1;
BA_ "CrossOver_InfoCAN" SG_ 956 PrkBrkStatus 1;
BA_ "U_CD4_MY13_Diesel_Rx" SG_ 956 PrkBrkStatus 1;
BA_ "U_CD4_MY13_Gas_Rx" SG_ 956 PrkBrkStatus 1;
BA_ "U_CD4_MY13_Hev_Rx" SG_ 956 PrkBrkStatus 1;
BA_ "U_CD4_MY13_Phev_Rx" SG_ 956 PrkBrkStatus 1;
BA_ "U_CD42_MY14_Diesel_Rx" SG_ 956 PrkBrkStatus 1;
BA_ "U_CD42_MY14_Gas_Rx" SG_ 956 PrkBrkStatus 1;
BA_ "U_P552_MY15_Gas_Rx" SG_ 956 PrkBrkStatus 1;
BA_ "U_C489_MY14_Gas_Rx" SG_ 956 PrkBrkStatus 1;
BA_ "U_B562LC_MY14_Gas_Rx" SG_ 956 PrkBrkStatus 1;
BA_ "U_U502_MY15_Gas_Rx" SG_ 956 PrkBrkStatus 1;
BA_ "U_UP375_MY15_Gas_Rx" SG_ 956 PrkBrkStatus 1;
BA_ "U_UP375_MY15_Diesel_Rx" SG_ 956 PrkBrkStatus 1;
BA_ "U_CD43_MY16_Gas_Rx" SG_ 956 PrkBrkStatus 1;
BA_ "CrossOver_InfoCAN" SG_ 956 GearLvrPos_D_Actl_UB 1;
BA_ "U_CD4_MY13_Diesel_Rx" SG_ 956 GearLvrPos_D_Actl_UB 1;
BA_ "U_CD4_MY13_Gas_Rx" SG_ 956 GearLvrPos_D_Actl_UB 1;
BA_ "U_CD4_MY13_Hev_Rx" SG_ 956 GearLvrPos_D_Actl_UB 1;
BA_ "U_CD4_MY13_Phev_Rx" SG_ 956 GearLvrPos_D_Actl_UB 1;
BA_ "U_CD42_MY14_Diesel_Rx" SG_ 956 GearLvrPos_D_Actl_UB 1;
BA_ "U_CD42_MY14_Gas_Rx" SG_ 956 GearLvrPos_D_Actl_UB 1;
BA_ "U_P552_MY15_Gas_Rx" SG_ 956 GearLvrPos_D_Actl_UB 1;
BA_ "U_S550_MY15_Gas_Rx" SG_ 956 GearLvrPos_D_Actl_UB 1;
BA_ "U_C489_MY14_Gas_Rx" SG_ 956 GearLvrPos_D_Actl_UB 1;
BA_ "U_B562LC_MY14_Gas_Rx" SG_ 956 GearLvrPos_D_Actl_UB 1;
BA_ "U_U502_MY15_Gas_Rx" SG_ 956 GearLvrPos_D_Actl_UB 1;
BA_ "U_UP375_MY15_Gas_Rx" SG_ 956 GearLvrPos_D_Actl_UB 1;
BA_ "U_UP375_MY15_Diesel_Rx" SG_ 956 GearLvrPos_D_Actl_UB 1;
BA_ "U_CD43_MY16_Gas_Rx" SG_ 956 GearLvrPos_D_Actl_UB 1;
BA_ "U_CD4_MY14_Diesel_Rx" SG_ 956 GearLvrPos_D_Actl_UB 1;
BA_ "U_CD4_MY14_Gas_Rx" SG_ 956 GearLvrPos_D_Actl_UB 1;
BA_ "U_CD4_MY14_Hev_Rx" SG_ 956 GearLvrPos_D_Actl_UB 1;
BA_ "U_CD4_MY14_Phev_Rx" SG_ 956 GearLvrPos_D_Actl_UB 1;
BA_ "U_CD4_MY13_Diesel_Rx" SG_ 956 PrkBrkStatus_UB 1;
BA_ "U_CD4_MY13_Gas_Rx" SG_ 956 PrkBrkStatus_UB 1;
BA_ "U_CD4_MY13_Hev_Rx" SG_ 956 PrkBrkStatus_UB 1;
BA_ "U_CD4_MY13_Phev_Rx" SG_ 956 PrkBrkStatus_UB 1;
BA_ "U_CD42_MY14_Diesel_Rx" SG_ 956 PrkBrkStatus_UB 1;
BA_ "U_CD42_MY14_Gas_Rx" SG_ 956 PrkBrkStatus_UB 1;
BA_ "U_P552_MY15_Gas_Rx" SG_ 956 PrkBrkStatus_UB 1;
BA_ "U_C489_MY14_Gas_Rx" SG_ 956 PrkBrkStatus_UB 1;
BA_ "U_B562LC_MY14_Gas_Rx" SG_ 956 PrkBrkStatus_UB 1;
BA_ "U_U502_MY15_Gas_Rx" SG_ 956 PrkBrkStatus_UB 1;
BA_ "U_UP375_MY15_Gas_Rx" SG_ 956 PrkBrkStatus_UB 1;
BA_ "U_UP375_MY15_Diesel_Rx" SG_ 956 PrkBrkStatus_UB 1;
BA_ "U_CD43_MY16_Gas_Rx" SG_ 956 PrkBrkStatus_UB 1;
BA_ "CrossOver_InfoCAN" SG_ 956 ApedPos_Pc_ActlArb 1;
BA_ "U_CD4_MY13_Diesel_Rx" SG_ 956 ApedPos_Pc_ActlArb 1;
BA_ "U_CD4_MY13_Gas_Rx" SG_ 956 ApedPos_Pc_ActlArb 1;
BA_ "U_CD4_MY13_Hev_Rx" SG_ 956 ApedPos_Pc_ActlArb 1;
BA_ "U_CD4_MY13_Phev_Rx" SG_ 956 ApedPos_Pc_ActlArb 1;
BA_ "U_CD42_MY14_Diesel_Rx" SG_ 956 ApedPos_Pc_ActlArb 1;
BA_ "U_CD42_MY14_Gas_Rx" SG_ 956 ApedPos_Pc_ActlArb 1;
BA_ "U_P552_MY15_Gas_Rx" SG_ 956 ApedPos_Pc_ActlArb 1;
BA_ "U_S550_MY15_Gas_Rx" SG_ 956 ApedPos_Pc_ActlArb 1;
BA_ "U_C489_MY14_Gas_Rx" SG_ 956 ApedPos_Pc_ActlArb 1;
BA_ "U_U502_MY15_Gas_Rx" SG_ 956 ApedPos_Pc_ActlArb 1;
BA_ "U_UP375_MY15_Gas_Rx" SG_ 956 ApedPos_Pc_ActlArb 1;
BA_ "U_UP375_MY15_Diesel_Rx" SG_ 956 ApedPos_Pc_ActlArb 1;
BA_ "U_CD43_MY16_Gas_Rx" SG_ 956 ApedPos_Pc_ActlArb 1;
BA_ "U_CD4_MY13_Diesel_Rx" SG_ 956 ApedPos_Pc_ActlArb_UB 1;
BA_ "U_CD4_MY13_Gas_Rx" SG_ 956 ApedPos_Pc_ActlArb_UB 1;
BA_ "U_CD4_MY13_Hev_Rx" SG_ 956 ApedPos_Pc_ActlArb_UB 1;
BA_ "U_CD4_MY13_Phev_Rx" SG_ 956 ApedPos_Pc_ActlArb_UB 1;
BA_ "U_CD42_MY14_Diesel_Rx" SG_ 956 ApedPos_Pc_ActlArb_UB 1;
BA_ "U_CD42_MY14_Gas_Rx" SG_ 956 ApedPos_Pc_ActlArb_UB 1;
BA_ "U_P552_MY15_Gas_Rx" SG_ 956 ApedPos_Pc_ActlArb_UB 1;
BA_ "U_S550_MY15_Gas_Rx" SG_ 956 ApedPos_Pc_ActlArb_UB 1;
BA_ "U_C489_MY14_Gas_Rx" SG_ 956 ApedPos_Pc_ActlArb_UB 1;
BA_ "U_U502_MY15_Gas_Rx" SG_ 956 ApedPos_Pc_ActlArb_UB 1;
BA_ "U_UP375_MY15_Gas_Rx" SG_ 956 ApedPos_Pc_ActlArb_UB 1;
BA_ "U_UP375_MY15_Diesel_Rx" SG_ 956 ApedPos_Pc_ActlArb_UB 1;
BA_ "U_CD43_MY16_Gas_Rx" SG_ 956 ApedPos_Pc_ActlArb_UB 1;
BA_ "CrossOver_InfoCAN" SG_ 956 GearLvrPos_D_Actl 1;
BA_ "CrossOver_LIN" SG_ 956 GearLvrPos_D_Actl 1;
BA_ "U_CD4_MY13_Diesel_Rx" SG_ 956 GearLvrPos_D_Actl 1;
BA_ "U_CD4_MY13_Gas_Rx" SG_ 956 GearLvrPos_D_Actl 1;
BA_ "U_CD4_MY13_Hev_Rx" SG_ 956 GearLvrPos_D_Actl 1;
BA_ "U_CD4_MY13_Phev_Rx" SG_ 956 GearLvrPos_D_Actl 1;
BA_ "U_CD42_MY14_Diesel_Rx" SG_ 956 GearLvrPos_D_Actl 1;
BA_ "U_CD42_MY14_Gas_Rx" SG_ 956 GearLvrPos_D_Actl 1;
BA_ "U_P552_MY15_Gas_Rx" SG_ 956 GearLvrPos_D_Actl 1;
BA_ "U_S550_MY15_Gas_Rx" SG_ 956 GearLvrPos_D_Actl 1;
BA_ "U_C489_MY14_Gas_Rx" SG_ 956 GearLvrPos_D_Actl 1;
BA_ "U_B562LC_MY14_Gas_Rx" SG_ 956 GearLvrPos_D_Actl 1;
BA_ "U_U502_MY15_Gas_Rx" SG_ 956 GearLvrPos_D_Actl 1;
BA_ "U_UP375_MY15_Gas_Rx" SG_ 956 GearLvrPos_D_Actl 1;
BA_ "U_UP375_MY15_Diesel_Rx" SG_ 956 GearLvrPos_D_Actl 1;
BA_ "U_CD43_MY16_Gas_Rx" SG_ 956 GearLvrPos_D_Actl 1;
BA_ "U_CD4_MY14_Diesel_Rx" SG_ 956 GearLvrPos_D_Actl 1;
BA_ "U_CD4_MY14_Gas_Rx" SG_ 956 GearLvrPos_D_Actl 1;
BA_ "U_CD4_MY14_Hev_Rx" SG_ 956 GearLvrPos_D_Actl 1;
BA_ "U_CD4_MY14_Phev_Rx" SG_ 956 GearLvrPos_D_Actl 1;
BA_ "GenSigTimeoutTime_SODL" SG_ 956 GearLvrPos_D_Actl 800;
BA_ "GenSigTimeoutTime_SODR" SG_ 956 GearLvrPos_D_Actl 800;
BA_ "GenSigSendType" SG_ 831 RearPassWindowLockCmd 3;
BA_ "U_CD4_MY13_Diesel_Rx" SG_ 831 RearPassWindowLockCmd 1;
BA_ "U_CD4_MY13_Gas_Rx" SG_ 831 RearPassWindowLockCmd 1;
BA_ "U_CD4_MY13_Hev_Rx" SG_ 831 RearPassWindowLockCmd 1;
BA_ "U_CD4_MY13_Phev_Rx" SG_ 831 RearPassWindowLockCmd 1;
BA_ "U_CD42_MY14_Diesel_Rx" SG_ 831 RearPassWindowLockCmd 1;
BA_ "U_CD42_MY14_Gas_Rx" SG_ 831 RearPassWindowLockCmd 1;
BA_ "U_P552_MY15_Gas_Rx" SG_ 831 RearPassWindowLockCmd 1;
BA_ "U_S550_MY15_Gas_Rx" SG_ 831 RearPassWindowLockCmd 1;
BA_ "U_C489_MY14_Gas_Rx" SG_ 831 RearPassWindowLockCmd 1;
BA_ "U_U502_MY15_Gas_Rx" SG_ 831 RearPassWindowLockCmd 1;
BA_ "U_UP375_MY15_Gas_Rx" SG_ 831 RearPassWindowLockCmd 1;
BA_ "U_UP375_MY15_Diesel_Rx" SG_ 831 RearPassWindowLockCmd 1;
BA_ "U_CD43_MY16_Gas_Rx" SG_ 831 RearPassWindowLockCmd 1;
BA_ "U_CD4_MY14_Diesel_Rx" SG_ 831 RearPassWindowLockCmd 1;
BA_ "U_CD4_MY14_Gas_Rx" SG_ 831 RearPassWindowLockCmd 1;
BA_ "U_CD4_MY14_Hev_Rx" SG_ 831 RearPassWindowLockCmd 1;
BA_ "U_CD4_MY14_Phev_Rx" SG_ 831 RearPassWindowLockCmd 1;
BA_ "U_CD4_MY13_Diesel_Tx" SG_ 831 RearPassWindowLockCmd 1;
BA_ "U_CD4_MY13_Gas_Tx" SG_ 831 RearPassWindowLockCmd 1;
BA_ "U_CD4_MY13_Hev_Tx" SG_ 831 RearPassWindowLockCmd 1;
BA_ "U_CD4_MY13_Phev_Tx" SG_ 831 RearPassWindowLockCmd 1;
BA_ "U_CD42_MY14_Diesel_Tx" SG_ 831 RearPassWindowLockCmd 1;
BA_ "U_CD42_MY14_Gas_Tx" SG_ 831 RearPassWindowLockCmd 1;
BA_ "U_P552_MY15_Gas_Tx" SG_ 831 RearPassWindowLockCmd 1;
BA_ "U_S550_MY15_Gas_Tx" SG_ 831 RearPassWindowLockCmd 1;
BA_ "U_C489_MY14_Gas_Tx" SG_ 831 RearPassWindowLockCmd 1;
BA_ "U_U502_MY15_Gas_Tx" SG_ 831 RearPassWindowLockCmd 1;
BA_ "U_UP375_MY15_Gas_Tx" SG_ 831 RearPassWindowLockCmd 1;
BA_ "U_UP375_MY15_Diesel_Tx" SG_ 831 RearPassWindowLockCmd 1;
BA_ "U_CD43_MY16_Gas_Tx" SG_ 831 RearPassWindowLockCmd 1;
BA_ "U_CD4_MY14_Diesel_Tx" SG_ 831 RearPassWindowLockCmd 1;
BA_ "U_CD4_MY14_Gas_Tx" SG_ 831 RearPassWindowLockCmd 1;
BA_ "U_CD4_MY14_Hev_Tx" SG_ 831 RearPassWindowLockCmd 1;
BA_ "U_CD4_MY14_Phev_Tx" SG_ 831 RearPassWindowLockCmd 1;
BA_ "WakeupSignal" SG_ 831 RearPassWindowCmd 1;
BA_ "GenSigSendType" SG_ 831 RearPassWindowCmd 3;
BA_ "U_CD4_MY13_Diesel_Rx" SG_ 831 RearPassWindowCmd 1;
BA_ "U_CD4_MY13_Gas_Rx" SG_ 831 RearPassWindowCmd 1;
BA_ "U_CD4_MY13_Hev_Rx" SG_ 831 RearPassWindowCmd 1;
BA_ "U_CD4_MY13_Phev_Rx" SG_ 831 RearPassWindowCmd 1;
BA_ "U_CD42_MY14_Diesel_Rx" SG_ 831 RearPassWindowCmd 1;
BA_ "U_CD42_MY14_Gas_Rx" SG_ 831 RearPassWindowCmd 1;
BA_ "U_P552_MY15_Gas_Rx" SG_ 831 RearPassWindowCmd 1;
BA_ "U_S550_MY15_Gas_Rx" SG_ 831 RearPassWindowCmd 1;
BA_ "U_C489_MY14_Gas_Rx" SG_ 831 RearPassWindowCmd 1;
BA_ "U_U502_MY15_Gas_Rx" SG_ 831 RearPassWindowCmd 1;
BA_ "U_UP375_MY15_Gas_Rx" SG_ 831 RearPassWindowCmd 1;
BA_ "U_UP375_MY15_Diesel_Rx" SG_ 831 RearPassWindowCmd 1;
BA_ "U_CD43_MY16_Gas_Rx" SG_ 831 RearPassWindowCmd 1;
BA_ "U_CD4_MY14_Diesel_Rx" SG_ 831 RearPassWindowCmd 1;
BA_ "U_CD4_MY14_Gas_Rx" SG_ 831 RearPassWindowCmd 1;
BA_ "U_CD4_MY14_Hev_Rx" SG_ 831 RearPassWindowCmd 1;
BA_ "U_CD4_MY14_Phev_Rx" SG_ 831 RearPassWindowCmd 1;
BA_ "U_CD4_MY13_Diesel_Tx" SG_ 831 RearPassWindowCmd 1;
BA_ "U_CD4_MY13_Gas_Tx" SG_ 831 RearPassWindowCmd 1;
BA_ "U_CD4_MY13_Hev_Tx" SG_ 831 RearPassWindowCmd 1;
BA_ "U_CD4_MY13_Phev_Tx" SG_ 831 RearPassWindowCmd 1;
BA_ "U_CD42_MY14_Diesel_Tx" SG_ 831 RearPassWindowCmd 1;
BA_ "U_CD42_MY14_Gas_Tx" SG_ 831 RearPassWindowCmd 1;
BA_ "U_P552_MY15_Gas_Tx" SG_ 831 RearPassWindowCmd 1;
BA_ "U_S550_MY15_Gas_Tx" SG_ 831 RearPassWindowCmd 1;
BA_ "U_C489_MY14_Gas_Tx" SG_ 831 RearPassWindowCmd 1;
BA_ "U_U502_MY15_Gas_Tx" SG_ 831 RearPassWindowCmd 1;
BA_ "U_UP375_MY15_Gas_Tx" SG_ 831 RearPassWindowCmd 1;
BA_ "U_UP375_MY15_Diesel_Tx" SG_ 831 RearPassWindowCmd 1;
BA_ "U_CD43_MY16_Gas_Tx" SG_ 831 RearPassWindowCmd 1;
BA_ "U_CD4_MY14_Diesel_Tx" SG_ 831 RearPassWindowCmd 1;
BA_ "U_CD4_MY14_Gas_Tx" SG_ 831 RearPassWindowCmd 1;
BA_ "U_CD4_MY14_Hev_Tx" SG_ 831 RearPassWindowCmd 1;
BA_ "U_CD4_MY14_Phev_Tx" SG_ 831 RearPassWindowCmd 1;
BA_ "WakeupSignal" SG_ 831 PassWindowCmd 1;
BA_ "GenSigSendType" SG_ 831 PassWindowCmd 3;
BA_ "U_CD4_MY13_Diesel_Rx" SG_ 831 PassWindowCmd 1;
BA_ "U_CD4_MY13_Gas_Rx" SG_ 831 PassWindowCmd 1;
BA_ "U_CD4_MY13_Hev_Rx" SG_ 831 PassWindowCmd 1;
BA_ "U_CD4_MY13_Phev_Rx" SG_ 831 PassWindowCmd 1;
BA_ "U_CD42_MY14_Diesel_Rx" SG_ 831 PassWindowCmd 1;
BA_ "U_CD42_MY14_Gas_Rx" SG_ 831 PassWindowCmd 1;
BA_ "U_P552_MY15_Gas_Rx" SG_ 831 PassWindowCmd 1;
BA_ "U_S550_MY15_Gas_Rx" SG_ 831 PassWindowCmd 1;
BA_ "U_C489_MY14_Gas_Rx" SG_ 831 PassWindowCmd 1;
BA_ "U_U502_MY15_Gas_Rx" SG_ 831 PassWindowCmd 1;
BA_ "U_UP375_MY15_Gas_Rx" SG_ 831 PassWindowCmd 1;
BA_ "U_UP375_MY15_Diesel_Rx" SG_ 831 PassWindowCmd 1;
BA_ "U_CD43_MY16_Gas_Rx" SG_ 831 PassWindowCmd 1;
BA_ "U_CD4_MY14_Diesel_Rx" SG_ 831 PassWindowCmd 1;
BA_ "U_CD4_MY14_Gas_Rx" SG_ 831 PassWindowCmd 1;
BA_ "U_CD4_MY14_Hev_Rx" SG_ 831 PassWindowCmd 1;
BA_ "U_CD4_MY14_Phev_Rx" SG_ 831 PassWindowCmd 1;
BA_ "U_CD4_MY13_Diesel_Tx" SG_ 831 PassWindowCmd 1;
BA_ "U_CD4_MY13_Gas_Tx" SG_ 831 PassWindowCmd 1;
BA_ "U_CD4_MY13_Hev_Tx" SG_ 831 PassWindowCmd 1;
BA_ "U_CD4_MY13_Phev_Tx" SG_ 831 PassWindowCmd 1;
BA_ "U_CD42_MY14_Diesel_Tx" SG_ 831 PassWindowCmd 1;
BA_ "U_CD42_MY14_Gas_Tx" SG_ 831 PassWindowCmd 1;
BA_ "U_P552_MY15_Gas_Tx" SG_ 831 PassWindowCmd 1;
BA_ "U_S550_MY15_Gas_Tx" SG_ 831 PassWindowCmd 1;
BA_ "U_C489_MY14_Gas_Tx" SG_ 831 PassWindowCmd 1;
BA_ "U_U502_MY15_Gas_Tx" SG_ 831 PassWindowCmd 1;
BA_ "U_UP375_MY15_Gas_Tx" SG_ 831 PassWindowCmd 1;
BA_ "U_UP375_MY15_Diesel_Tx" SG_ 831 PassWindowCmd 1;
BA_ "U_CD43_MY16_Gas_Tx" SG_ 831 PassWindowCmd 1;
BA_ "U_CD4_MY14_Diesel_Tx" SG_ 831 PassWindowCmd 1;
BA_ "U_CD4_MY14_Gas_Tx" SG_ 831 PassWindowCmd 1;
BA_ "U_CD4_MY14_Hev_Tx" SG_ 831 PassWindowCmd 1;
BA_ "U_CD4_MY14_Phev_Tx" SG_ 831 PassWindowCmd 1;
BA_ "WakeupSignal" SG_ 831 PassMirrorCmd 1;
BA_ "GenSigSendType" SG_ 831 PassMirrorCmd 3;
BA_ "U_CD4_MY13_Diesel_Rx" SG_ 831 PassMirrorCmd 1;
BA_ "U_CD4_MY13_Gas_Rx" SG_ 831 PassMirrorCmd 1;
BA_ "U_CD4_MY13_Hev_Rx" SG_ 831 PassMirrorCmd 1;
BA_ "U_CD4_MY13_Phev_Rx" SG_ 831 PassMirrorCmd 1;
BA_ "U_CD42_MY14_Diesel_Rx" SG_ 831 PassMirrorCmd 1;
BA_ "U_CD42_MY14_Gas_Rx" SG_ 831 PassMirrorCmd 1;
BA_ "U_P552_MY15_Gas_Rx" SG_ 831 PassMirrorCmd 1;
BA_ "U_S550_MY15_Gas_Rx" SG_ 831 PassMirrorCmd 1;
BA_ "U_C489_MY14_Gas_Rx" SG_ 831 PassMirrorCmd 1;
BA_ "U_U502_MY15_Gas_Rx" SG_ 831 PassMirrorCmd 1;
BA_ "U_UP375_MY15_Gas_Rx" SG_ 831 PassMirrorCmd 1;
BA_ "U_UP375_MY15_Diesel_Rx" SG_ 831 PassMirrorCmd 1;
BA_ "U_CD43_MY16_Gas_Rx" SG_ 831 PassMirrorCmd 1;
BA_ "U_CD4_MY14_Diesel_Rx" SG_ 831 PassMirrorCmd 1;
BA_ "U_CD4_MY14_Gas_Rx" SG_ 831 PassMirrorCmd 1;
BA_ "U_CD4_MY14_Hev_Rx" SG_ 831 PassMirrorCmd 1;
BA_ "U_CD4_MY14_Phev_Rx" SG_ 831 PassMirrorCmd 1;
BA_ "U_CD4_MY13_Diesel_Tx" SG_ 831 PassMirrorCmd 1;
BA_ "U_CD4_MY13_Gas_Tx" SG_ 831 PassMirrorCmd 1;
BA_ "U_CD4_MY13_Hev_Tx" SG_ 831 PassMirrorCmd 1;
BA_ "U_CD4_MY13_Phev_Tx" SG_ 831 PassMirrorCmd 1;
BA_ "U_CD42_MY14_Diesel_Tx" SG_ 831 PassMirrorCmd 1;
BA_ "U_CD42_MY14_Gas_Tx" SG_ 831 PassMirrorCmd 1;
BA_ "U_P552_MY15_Gas_Tx" SG_ 831 PassMirrorCmd 1;
BA_ "U_S550_MY15_Gas_Tx" SG_ 831 PassMirrorCmd 1;
BA_ "U_C489_MY14_Gas_Tx" SG_ 831 PassMirrorCmd 1;
BA_ "U_U502_MY15_Gas_Tx" SG_ 831 PassMirrorCmd 1;
BA_ "U_UP375_MY15_Gas_Tx" SG_ 831 PassMirrorCmd 1;
BA_ "U_UP375_MY15_Diesel_Tx" SG_ 831 PassMirrorCmd 1;
BA_ "U_CD43_MY16_Gas_Tx" SG_ 831 PassMirrorCmd 1;
BA_ "U_CD4_MY14_Diesel_Tx" SG_ 831 PassMirrorCmd 1;
BA_ "U_CD4_MY14_Gas_Tx" SG_ 831 PassMirrorCmd 1;
BA_ "U_CD4_MY14_Hev_Tx" SG_ 831 PassMirrorCmd 1;
BA_ "U_CD4_MY14_Phev_Tx" SG_ 831 PassMirrorCmd 1;
BA_ "GenSigSendType" SG_ 831 DipMirrorPosPassenger 3;
BA_ "U_CD4_MY13_Diesel_Rx" SG_ 831 DipMirrorPosPassenger 1;
BA_ "U_CD4_MY13_Gas_Rx" SG_ 831 DipMirrorPosPassenger 1;
BA_ "U_CD4_MY13_Hev_Rx" SG_ 831 DipMirrorPosPassenger 1;
BA_ "U_CD4_MY13_Phev_Rx" SG_ 831 DipMirrorPosPassenger 1;
BA_ "U_CD42_MY14_Diesel_Rx" SG_ 831 DipMirrorPosPassenger 1;
BA_ "U_CD42_MY14_Gas_Rx" SG_ 831 DipMirrorPosPassenger 1;
BA_ "U_P552_MY15_Gas_Rx" SG_ 831 DipMirrorPosPassenger 1;
BA_ "U_S550_MY15_Gas_Rx" SG_ 831 DipMirrorPosPassenger 1;
BA_ "U_C489_MY14_Gas_Rx" SG_ 831 DipMirrorPosPassenger 1;
BA_ "U_U502_MY15_Gas_Rx" SG_ 831 DipMirrorPosPassenger 1;
BA_ "U_UP375_MY15_Gas_Rx" SG_ 831 DipMirrorPosPassenger 1;
BA_ "U_UP375_MY15_Diesel_Rx" SG_ 831 DipMirrorPosPassenger 1;
BA_ "U_CD43_MY16_Gas_Rx" SG_ 831 DipMirrorPosPassenger 1;
BA_ "U_CD4_MY14_Diesel_Rx" SG_ 831 DipMirrorPosPassenger 1;
BA_ "U_CD4_MY14_Gas_Rx" SG_ 831 DipMirrorPosPassenger 1;
BA_ "U_CD4_MY14_Hev_Rx" SG_ 831 DipMirrorPosPassenger 1;
BA_ "U_CD4_MY14_Phev_Rx" SG_ 831 DipMirrorPosPassenger 1;
BA_ "U_CD4_MY13_Diesel_Tx" SG_ 831 DipMirrorPosPassenger 1;
BA_ "U_CD4_MY13_Gas_Tx" SG_ 831 DipMirrorPosPassenger 1;
BA_ "U_CD4_MY13_Hev_Tx" SG_ 831 DipMirrorPosPassenger 1;
BA_ "U_CD4_MY13_Phev_Tx" SG_ 831 DipMirrorPosPassenger 1;
BA_ "U_CD42_MY14_Diesel_Tx" SG_ 831 DipMirrorPosPassenger 1;
BA_ "U_CD42_MY14_Gas_Tx" SG_ 831 DipMirrorPosPassenger 1;
BA_ "U_P552_MY15_Gas_Tx" SG_ 831 DipMirrorPosPassenger 1;
BA_ "U_S550_MY15_Gas_Tx" SG_ 831 DipMirrorPosPassenger 1;
BA_ "U_C489_MY14_Gas_Tx" SG_ 831 DipMirrorPosPassenger 1;
BA_ "U_U502_MY15_Gas_Tx" SG_ 831 DipMirrorPosPassenger 1;
BA_ "U_UP375_MY15_Gas_Tx" SG_ 831 DipMirrorPosPassenger 1;
BA_ "U_UP375_MY15_Diesel_Tx" SG_ 831 DipMirrorPosPassenger 1;
BA_ "U_CD43_MY16_Gas_Tx" SG_ 831 DipMirrorPosPassenger 1;
BA_ "U_CD4_MY14_Diesel_Tx" SG_ 831 DipMirrorPosPassenger 1;
BA_ "U_CD4_MY14_Gas_Tx" SG_ 831 DipMirrorPosPassenger 1;
BA_ "U_CD4_MY14_Hev_Tx" SG_ 831 DipMirrorPosPassenger 1;
BA_ "U_CD4_MY14_Phev_Tx" SG_ 831 DipMirrorPosPassenger 1;
BA_ "GenSigSendType" SG_ 831 ActiveStoragePassenger 3;
BA_ "U_CD4_MY13_Diesel_Rx" SG_ 831 ActiveStoragePassenger 1;
BA_ "U_CD4_MY13_Gas_Rx" SG_ 831 ActiveStoragePassenger 1;
BA_ "U_CD4_MY13_Hev_Rx" SG_ 831 ActiveStoragePassenger 1;
BA_ "U_CD4_MY13_Phev_Rx" SG_ 831 ActiveStoragePassenger 1;
BA_ "U_CD42_MY14_Diesel_Rx" SG_ 831 ActiveStoragePassenger 1;
BA_ "U_CD42_MY14_Gas_Rx" SG_ 831 ActiveStoragePassenger 1;
BA_ "U_P552_MY15_Gas_Rx" SG_ 831 ActiveStoragePassenger 1;
BA_ "U_S550_MY15_Gas_Rx" SG_ 831 ActiveStoragePassenger 1;
BA_ "U_C489_MY14_Gas_Rx" SG_ 831 ActiveStoragePassenger 1;
BA_ "U_U502_MY15_Gas_Rx" SG_ 831 ActiveStoragePassenger 1;
BA_ "U_UP375_MY15_Gas_Rx" SG_ 831 ActiveStoragePassenger 1;
BA_ "U_UP375_MY15_Diesel_Rx" SG_ 831 ActiveStoragePassenger 1;
BA_ "U_CD43_MY16_Gas_Rx" SG_ 831 ActiveStoragePassenger 1;
BA_ "U_CD4_MY14_Diesel_Rx" SG_ 831 ActiveStoragePassenger 1;
BA_ "U_CD4_MY14_Gas_Rx" SG_ 831 ActiveStoragePassenger 1;
BA_ "U_CD4_MY14_Hev_Rx" SG_ 831 ActiveStoragePassenger 1;
BA_ "U_CD4_MY14_Phev_Rx" SG_ 831 ActiveStoragePassenger 1;
BA_ "U_CD4_MY13_Diesel_Tx" SG_ 831 ActiveStoragePassenger 1;
BA_ "U_CD4_MY13_Gas_Tx" SG_ 831 ActiveStoragePassenger 1;
BA_ "U_CD4_MY13_Hev_Tx" SG_ 831 ActiveStoragePassenger 1;
BA_ "U_CD4_MY13_Phev_Tx" SG_ 831 ActiveStoragePassenger 1;
BA_ "U_CD42_MY14_Diesel_Tx" SG_ 831 ActiveStoragePassenger 1;
BA_ "U_CD42_MY14_Gas_Tx" SG_ 831 ActiveStoragePassenger 1;
BA_ "U_P552_MY15_Gas_Tx" SG_ 831 ActiveStoragePassenger 1;
BA_ "U_S550_MY15_Gas_Tx" SG_ 831 ActiveStoragePassenger 1;
BA_ "U_C489_MY14_Gas_Tx" SG_ 831 ActiveStoragePassenger 1;
BA_ "U_U502_MY15_Gas_Tx" SG_ 831 ActiveStoragePassenger 1;
BA_ "U_UP375_MY15_Gas_Tx" SG_ 831 ActiveStoragePassenger 1;
BA_ "U_UP375_MY15_Diesel_Tx" SG_ 831 ActiveStoragePassenger 1;
BA_ "U_CD43_MY16_Gas_Tx" SG_ 831 ActiveStoragePassenger 1;
BA_ "U_CD4_MY14_Diesel_Tx" SG_ 831 ActiveStoragePassenger 1;
BA_ "U_CD4_MY14_Gas_Tx" SG_ 831 ActiveStoragePassenger 1;
BA_ "U_CD4_MY14_Hev_Tx" SG_ 831 ActiveStoragePassenger 1;
BA_ "U_CD4_MY14_Phev_Tx" SG_ 831 ActiveStoragePassenger 1;
BA_ "WakeupSignal" SG_ 831 RearDriverWindowPos 1;
BA_ "GenSigSendType" SG_ 831 RearDriverWindowPos 3;
BA_ "U_CD4_MY13_Diesel_Rx" SG_ 831 RearDriverWindowPos 1;
BA_ "U_CD4_MY13_Gas_Rx" SG_ 831 RearDriverWindowPos 1;
BA_ "U_CD4_MY13_Hev_Rx" SG_ 831 RearDriverWindowPos 1;
BA_ "U_CD4_MY13_Phev_Rx" SG_ 831 RearDriverWindowPos 1;
BA_ "U_CD42_MY14_Diesel_Rx" SG_ 831 RearDriverWindowPos 1;
BA_ "U_CD42_MY14_Gas_Rx" SG_ 831 RearDriverWindowPos 1;
BA_ "U_P552_MY15_Gas_Rx" SG_ 831 RearDriverWindowPos 1;
BA_ "U_S550_MY15_Gas_Rx" SG_ 831 RearDriverWindowPos 1;
BA_ "U_C489_MY14_Gas_Rx" SG_ 831 RearDriverWindowPos 1;
BA_ "U_U502_MY15_Gas_Rx" SG_ 831 RearDriverWindowPos 1;
BA_ "U_B479_MY15_Gas_Rx" SG_ 831 RearDriverWindowPos 1;
BA_ "U_UP375_MY15_Gas_Rx" SG_ 831 RearDriverWindowPos 1;
BA_ "U_UP375_MY15_Diesel_Rx" SG_ 831 RearDriverWindowPos 1;
BA_ "U_CD43_MY16_Gas_Rx" SG_ 831 RearDriverWindowPos 1;
BA_ "U_CD4_MY13_Diesel_Tx" SG_ 831 RearDriverWindowPos 1;
BA_ "U_CD4_MY13_Gas_Tx" SG_ 831 RearDriverWindowPos 1;
BA_ "U_CD4_MY13_Hev_Tx" SG_ 831 RearDriverWindowPos 1;
BA_ "U_CD4_MY13_Phev_Tx" SG_ 831 RearDriverWindowPos 1;
BA_ "U_CD42_MY14_Diesel_Tx" SG_ 831 RearDriverWindowPos 1;
BA_ "U_CD42_MY14_Gas_Tx" SG_ 831 RearDriverWindowPos 1;
BA_ "U_P552_MY15_Gas_Tx" SG_ 831 RearDriverWindowPos 1;
BA_ "U_S550_MY15_Gas_Tx" SG_ 831 RearDriverWindowPos 1;
BA_ "U_C489_MY14_Gas_Tx" SG_ 831 RearDriverWindowPos 1;
BA_ "U_U502_MY15_Gas_Tx" SG_ 831 RearDriverWindowPos 1;
BA_ "U_UP375_MY15_Gas_Tx" SG_ 831 RearDriverWindowPos 1;
BA_ "U_UP375_MY15_Diesel_Tx" SG_ 831 RearDriverWindowPos 1;
BA_ "U_CD43_MY16_Gas_Tx" SG_ 831 RearDriverWindowPos 1;
BA_ "U_CD4_MY14_Diesel_Tx" SG_ 831 RearDriverWindowPos 1;
BA_ "U_CD4_MY14_Gas_Tx" SG_ 831 RearDriverWindowPos 1;
BA_ "U_CD4_MY14_Hev_Tx" SG_ 831 RearDriverWindowPos 1;
BA_ "U_CD4_MY14_Phev_Tx" SG_ 831 RearDriverWindowPos 1;
BA_ "WakeupSignal" SG_ 831 DriverWindowPosition 1;
BA_ "GenSigSendType" SG_ 831 DriverWindowPosition 3;
BA_ "U_CD4_MY13_Diesel_Rx" SG_ 831 DriverWindowPosition 1;
BA_ "U_CD4_MY13_Gas_Rx" SG_ 831 DriverWindowPosition 1;
BA_ "U_CD4_MY13_Hev_Rx" SG_ 831 DriverWindowPosition 1;
BA_ "U_CD4_MY13_Phev_Rx" SG_ 831 DriverWindowPosition 1;
BA_ "U_CD42_MY14_Diesel_Rx" SG_ 831 DriverWindowPosition 1;
BA_ "U_CD42_MY14_Gas_Rx" SG_ 831 DriverWindowPosition 1;
BA_ "U_P552_MY15_Gas_Rx" SG_ 831 DriverWindowPosition 1;
BA_ "U_S550_MY15_Gas_Rx" SG_ 831 DriverWindowPosition 1;
BA_ "U_C489_MY14_Gas_Rx" SG_ 831 DriverWindowPosition 1;
BA_ "U_U502_MY15_Gas_Rx" SG_ 831 DriverWindowPosition 1;
BA_ "U_B479_MY15_Gas_Rx" SG_ 831 DriverWindowPosition 1;
BA_ "U_UP375_MY15_Gas_Rx" SG_ 831 DriverWindowPosition 1;
BA_ "U_UP375_MY15_Diesel_Rx" SG_ 831 DriverWindowPosition 1;
BA_ "U_CD43_MY16_Gas_Rx" SG_ 831 DriverWindowPosition 1;
BA_ "U_CD4_MY13_Diesel_Tx" SG_ 831 DriverWindowPosition 1;
BA_ "U_CD4_MY13_Gas_Tx" SG_ 831 DriverWindowPosition 1;
BA_ "U_CD4_MY13_Hev_Tx" SG_ 831 DriverWindowPosition 1;
BA_ "U_CD4_MY13_Phev_Tx" SG_ 831 DriverWindowPosition 1;
BA_ "U_CD42_MY14_Diesel_Tx" SG_ 831 DriverWindowPosition 1;
BA_ "U_CD42_MY14_Gas_Tx" SG_ 831 DriverWindowPosition 1;
BA_ "U_P552_MY15_Gas_Tx" SG_ 831 DriverWindowPosition 1;
BA_ "U_S550_MY15_Gas_Tx" SG_ 831 DriverWindowPosition 1;
BA_ "U_C489_MY14_Gas_Tx" SG_ 831 DriverWindowPosition 1;
BA_ "U_U502_MY15_Gas_Tx" SG_ 831 DriverWindowPosition 1;
BA_ "U_UP375_MY15_Gas_Tx" SG_ 831 DriverWindowPosition 1;
BA_ "U_UP375_MY15_Diesel_Tx" SG_ 831 DriverWindowPosition 1;
BA_ "U_CD43_MY16_Gas_Tx" SG_ 831 DriverWindowPosition 1;
BA_ "U_CD4_MY14_Diesel_Tx" SG_ 831 DriverWindowPosition 1;
BA_ "U_CD4_MY14_Gas_Tx" SG_ 831 DriverWindowPosition 1;
BA_ "U_CD4_MY14_Hev_Tx" SG_ 831 DriverWindowPosition 1;
BA_ "U_CD4_MY14_Phev_Tx" SG_ 831 DriverWindowPosition 1;
BA_ "GenSigSendType" SG_ 1820 TesterPhysicalResHSWM 3;
BA_ "U_CD4_MY13_Diesel_Tx" SG_ 1820 TesterPhysicalResHSWM 1;
BA_ "U_CD4_MY13_Gas_Tx" SG_ 1820 TesterPhysicalResHSWM 1;
BA_ "U_CD4_MY13_Hev_Tx" SG_ 1820 TesterPhysicalResHSWM 1;
BA_ "U_CD4_MY13_Phev_Tx" SG_ 1820 TesterPhysicalResHSWM 1;
BA_ "U_CD42_MY14_Diesel_Tx" SG_ 1820 TesterPhysicalResHSWM 1;
BA_ "U_CD42_MY14_Gas_Tx" SG_ 1820 TesterPhysicalResHSWM 1;
BA_ "U_P552_MY15_Gas_Tx" SG_ 1820 TesterPhysicalResHSWM 1;
BA_ "U_C489_MY14_Gas_Tx" SG_ 1820 TesterPhysicalResHSWM 1;
BA_ "U_U502_MY15_Gas_Tx" SG_ 1820 TesterPhysicalResHSWM 1;
BA_ "U_CD43_MY16_Gas_Tx" SG_ 1820 TesterPhysicalResHSWM 1;
BA_ "GenSigSendType" SG_ 1812 TesterPhysicalReqHSWM 3;
BA_ "U_CD4_MY13_Diesel_Rx" SG_ 1812 TesterPhysicalReqHSWM 1;
BA_ "U_CD4_MY13_Gas_Rx" SG_ 1812 TesterPhysicalReqHSWM 1;
BA_ "U_CD4_MY13_Hev_Rx" SG_ 1812 TesterPhysicalReqHSWM 1;
BA_ "U_CD4_MY13_Phev_Rx" SG_ 1812 TesterPhysicalReqHSWM 1;
BA_ "U_CD42_MY14_Diesel_Rx" SG_ 1812 TesterPhysicalReqHSWM 1;
BA_ "U_CD42_MY14_Gas_Rx" SG_ 1812 TesterPhysicalReqHSWM 1;
BA_ "U_P552_MY15_Gas_Rx" SG_ 1812 TesterPhysicalReqHSWM 1;
BA_ "U_C489_MY14_Gas_Rx" SG_ 1812 TesterPhysicalReqHSWM 1;
BA_ "U_U502_MY15_Gas_Rx" SG_ 1812 TesterPhysicalReqHSWM 1;
BA_ "U_CD43_MY16_Gas_Rx" SG_ 1812 TesterPhysicalReqHSWM 1;
BA_ "GenSigSendType" SG_ 1291 DSM_Network_Mgmt 3;
BA_ "U_CD4_MY13_Diesel_Rx" SG_ 1291 DSM_Network_Mgmt 1;
BA_ "U_CD4_MY13_Gas_Rx" SG_ 1291 DSM_Network_Mgmt 1;
BA_ "U_CD4_MY13_Hev_Rx" SG_ 1291 DSM_Network_Mgmt 1;
BA_ "U_CD4_MY13_Phev_Rx" SG_ 1291 DSM_Network_Mgmt 1;
BA_ "U_CD42_MY14_Diesel_Rx" SG_ 1291 DSM_Network_Mgmt 1;
BA_ "U_CD42_MY14_Gas_Rx" SG_ 1291 DSM_Network_Mgmt 1;
BA_ "U_P552_MY15_Gas_Rx" SG_ 1291 DSM_Network_Mgmt 1;
BA_ "U_S550_MY15_Gas_Rx" SG_ 1291 DSM_Network_Mgmt 1;
BA_ "U_C489_MY14_Gas_Rx" SG_ 1291 DSM_Network_Mgmt 1;
BA_ "U_U502_MY15_Gas_Rx" SG_ 1291 DSM_Network_Mgmt 1;
BA_ "U_CD43_MY16_Gas_Rx" SG_ 1291 DSM_Network_Mgmt 1;
BA_ "U_CD4_MY14_Diesel_Rx" SG_ 1291 DSM_Network_Mgmt 1;
BA_ "U_CD4_MY14_Gas_Rx" SG_ 1291 DSM_Network_Mgmt 1;
BA_ "U_CD4_MY14_Hev_Rx" SG_ 1291 DSM_Network_Mgmt 1;
BA_ "U_CD4_MY14_Phev_Rx" SG_ 1291 DSM_Network_Mgmt 1;
BA_ "U_UP375_MY15_Gas_Rx" SG_ 1291 DSM_Network_Mgmt 1;
BA_ "U_UP375_MY15_Diesel_Rx" SG_ 1291 DSM_Network_Mgmt 1;
BA_ "U_CD4_MY13_Diesel_Tx" SG_ 1291 DSM_Network_Mgmt 1;
BA_ "U_CD4_MY13_Gas_Tx" SG_ 1291 DSM_Network_Mgmt 1;
BA_ "U_CD4_MY13_Hev_Tx" SG_ 1291 DSM_Network_Mgmt 1;
BA_ "U_CD4_MY13_Phev_Tx" SG_ 1291 DSM_Network_Mgmt 1;
BA_ "U_CD42_MY14_Diesel_Tx" SG_ 1291 DSM_Network_Mgmt 1;
BA_ "U_CD42_MY14_Gas_Tx" SG_ 1291 DSM_Network_Mgmt 1;
BA_ "U_P552_MY15_Gas_Tx" SG_ 1291 DSM_Network_Mgmt 1;
BA_ "U_S550_MY15_Gas_Tx" SG_ 1291 DSM_Network_Mgmt 1;
BA_ "U_C489_MY14_Gas_Tx" SG_ 1291 DSM_Network_Mgmt 1;
BA_ "U_U502_MY15_Gas_Tx" SG_ 1291 DSM_Network_Mgmt 1;
BA_ "U_CD43_MY16_Gas_Tx" SG_ 1291 DSM_Network_Mgmt 1;
BA_ "GenSigSendType" SG_ 1319 SCME_Network_Mgmt 3;
BA_ "U_CD4_MY13_Diesel_Rx" SG_ 1319 SCME_Network_Mgmt 1;
BA_ "U_CD4_MY13_Gas_Rx" SG_ 1319 SCME_Network_Mgmt 1;
BA_ "U_CD4_MY13_Hev_Rx" SG_ 1319 SCME_Network_Mgmt 1;
BA_ "U_CD4_MY13_Phev_Rx" SG_ 1319 SCME_Network_Mgmt 1;
BA_ "U_CD42_MY14_Diesel_Rx" SG_ 1319 SCME_Network_Mgmt 1;
BA_ "U_CD42_MY14_Gas_Rx" SG_ 1319 SCME_Network_Mgmt 1;
BA_ "U_P552_MY15_Gas_Rx" SG_ 1319 SCME_Network_Mgmt 1;
BA_ "U_S550_MY15_Gas_Rx" SG_ 1319 SCME_Network_Mgmt 1;
BA_ "U_C489_MY14_Gas_Rx" SG_ 1319 SCME_Network_Mgmt 1;
BA_ "U_U502_MY15_Gas_Rx" SG_ 1319 SCME_Network_Mgmt 1;
BA_ "U_UP375_MY15_Gas_Rx" SG_ 1319 SCME_Network_Mgmt 1;
BA_ "U_UP375_MY15_Diesel_Rx" SG_ 1319 SCME_Network_Mgmt 1;
BA_ "U_CD43_MY16_Gas_Rx" SG_ 1319 SCME_Network_Mgmt 1;
BA_ "U_CD4_MY14_Diesel_Rx" SG_ 1319 SCME_Network_Mgmt 1;
BA_ "U_CD4_MY14_Gas_Rx" SG_ 1319 SCME_Network_Mgmt 1;
BA_ "U_CD4_MY14_Hev_Rx" SG_ 1319 SCME_Network_Mgmt 1;
BA_ "U_CD4_MY14_Phev_Rx" SG_ 1319 SCME_Network_Mgmt 1;
BA_ "U_CD4_MY13_Diesel_Tx" SG_ 1319 SCME_Network_Mgmt 1;
BA_ "U_CD4_MY13_Gas_Tx" SG_ 1319 SCME_Network_Mgmt 1;
BA_ "U_CD4_MY13_Hev_Tx" SG_ 1319 SCME_Network_Mgmt 1;
BA_ "U_CD4_MY13_Phev_Tx" SG_ 1319 SCME_Network_Mgmt 1;
BA_ "U_CD42_MY14_Diesel_Tx" SG_ 1319 SCME_Network_Mgmt 1;
BA_ "U_CD42_MY14_Gas_Tx" SG_ 1319 SCME_Network_Mgmt 1;
BA_ "U_P552_MY15_Gas_Tx" SG_ 1319 SCME_Network_Mgmt 1;
BA_ "U_S550_MY15_Gas_Tx" SG_ 1319 SCME_Network_Mgmt 1;
BA_ "U_C489_MY14_Gas_Tx" SG_ 1319 SCME_Network_Mgmt 1;
BA_ "U_U502_MY15_Gas_Tx" SG_ 1319 SCME_Network_Mgmt 1;
BA_ "U_CD43_MY16_Gas_Tx" SG_ 1319 SCME_Network_Mgmt 1;
BA_ "U_CD4_MY14_Diesel_Tx" SG_ 1319 SCME_Network_Mgmt 1;
BA_ "U_CD4_MY14_Gas_Tx" SG_ 1319 SCME_Network_Mgmt 1;
BA_ "U_CD4_MY14_Hev_Tx" SG_ 1319 SCME_Network_Mgmt 1;
BA_ "U_CD4_MY14_Phev_Tx" SG_ 1319 SCME_Network_Mgmt 1;
BA_ "GenSigSendType" SG_ 1388 GPSM_Network_Mgmt 3;
BA_ "U_CD4_MY13_Diesel_Rx" SG_ 1388 GPSM_Network_Mgmt 1;
BA_ "U_CD4_MY13_Gas_Rx" SG_ 1388 GPSM_Network_Mgmt 1;
BA_ "U_CD4_MY13_Hev_Rx" SG_ 1388 GPSM_Network_Mgmt 1;
BA_ "U_CD4_MY13_Phev_Rx" SG_ 1388 GPSM_Network_Mgmt 1;
BA_ "U_P552_MY15_Gas_Rx" SG_ 1388 GPSM_Network_Mgmt 1;
BA_ "U_CD42_MY14_Diesel_Rx" SG_ 1388 GPSM_Network_Mgmt 1;
BA_ "U_CD42_MY14_Gas_Rx" SG_ 1388 GPSM_Network_Mgmt 1;
BA_ "U_S550_MY15_Gas_Rx" SG_ 1388 GPSM_Network_Mgmt 1;
BA_ "U_C489_MY14_Gas_Rx" SG_ 1388 GPSM_Network_Mgmt 1;
BA_ "U_U502_MY15_Gas_Rx" SG_ 1388 GPSM_Network_Mgmt 1;
BA_ "U_CD43_MY16_Gas_Rx" SG_ 1388 GPSM_Network_Mgmt 1;
BA_ "U_UP375_MY15_Gas_Rx" SG_ 1388 GPSM_Network_Mgmt 1;
BA_ "U_UP375_MY15_Diesel_Rx" SG_ 1388 GPSM_Network_Mgmt 1;
BA_ "U_CD4_MY14_Diesel_Rx" SG_ 1388 GPSM_Network_Mgmt 1;
BA_ "U_CD4_MY14_Gas_Rx" SG_ 1388 GPSM_Network_Mgmt 1;
BA_ "U_CD4_MY14_Hev_Rx" SG_ 1388 GPSM_Network_Mgmt 1;
BA_ "U_CD4_MY14_Phev_Rx" SG_ 1388 GPSM_Network_Mgmt 1;
BA_ "U_CD4_MY13_Diesel_Tx" SG_ 1388 GPSM_Network_Mgmt 1;
BA_ "U_CD4_MY13_Gas_Tx" SG_ 1388 GPSM_Network_Mgmt 1;
BA_ "U_CD4_MY13_Hev_Tx" SG_ 1388 GPSM_Network_Mgmt 1;
BA_ "U_CD4_MY13_Phev_Tx" SG_ 1388 GPSM_Network_Mgmt 1;
BA_ "U_CD42_MY14_Diesel_Tx" SG_ 1388 GPSM_Network_Mgmt 1;
BA_ "U_CD42_MY14_Gas_Tx" SG_ 1388 GPSM_Network_Mgmt 1;
BA_ "U_P552_MY15_Gas_Tx" SG_ 1388 GPSM_Network_Mgmt 1;
BA_ "U_S550_MY15_Gas_Tx" SG_ 1388 GPSM_Network_Mgmt 1;
BA_ "U_C489_MY14_Gas_Tx" SG_ 1388 GPSM_Network_Mgmt 1;
BA_ "U_U502_MY15_Gas_Tx" SG_ 1388 GPSM_Network_Mgmt 1;
BA_ "U_UP375_MY15_Gas_Tx" SG_ 1388 GPSM_Network_Mgmt 1;
BA_ "U_UP375_MY15_Diesel_Tx" SG_ 1388 GPSM_Network_Mgmt 1;
BA_ "U_CD43_MY16_Gas_Tx" SG_ 1388 GPSM_Network_Mgmt 1;
BA_ "GenSigSendType" SG_ 1801 TesterPhysicalResGPSM 3;
BA_ "U_CD4_MY13_Diesel_Tx" SG_ 1801 TesterPhysicalResGPSM 1;
BA_ "U_CD4_MY13_Gas_Tx" SG_ 1801 TesterPhysicalResGPSM 1;
BA_ "U_CD4_MY13_Hev_Tx" SG_ 1801 TesterPhysicalResGPSM 1;
BA_ "U_CD4_MY13_Phev_Tx" SG_ 1801 TesterPhysicalResGPSM 1;
BA_ "U_CD42_MY14_Diesel_Tx" SG_ 1801 TesterPhysicalResGPSM 1;
BA_ "U_CD42_MY14_Gas_Tx" SG_ 1801 TesterPhysicalResGPSM 1;
BA_ "U_P552_MY15_Gas_Tx" SG_ 1801 TesterPhysicalResGPSM 1;
BA_ "U_S550_MY15_Gas_Tx" SG_ 1801 TesterPhysicalResGPSM 1;
BA_ "U_C489_MY14_Gas_Tx" SG_ 1801 TesterPhysicalResGPSM 1;
BA_ "U_U502_MY15_Gas_Tx" SG_ 1801 TesterPhysicalResGPSM 1;
BA_ "U_UP375_MY15_Gas_Tx" SG_ 1801 TesterPhysicalResGPSM 1;
BA_ "U_UP375_MY15_Diesel_Tx" SG_ 1801 TesterPhysicalResGPSM 1;
BA_ "U_CD43_MY16_Gas_Tx" SG_ 1801 TesterPhysicalResGPSM 1;
BA_ "GenSigSendType" SG_ 1793 TesterPhysicalReqGPSM 3;
BA_ "U_CD4_MY13_Diesel_Rx" SG_ 1793 TesterPhysicalReqGPSM 1;
BA_ "U_CD4_MY13_Gas_Rx" SG_ 1793 TesterPhysicalReqGPSM 1;
BA_ "U_CD4_MY13_Hev_Rx" SG_ 1793 TesterPhysicalReqGPSM 1;
BA_ "U_CD4_MY13_Phev_Rx" SG_ 1793 TesterPhysicalReqGPSM 1;
BA_ "U_CD42_MY14_Diesel_Rx" SG_ 1793 TesterPhysicalReqGPSM 1;
BA_ "U_CD42_MY14_Gas_Rx" SG_ 1793 TesterPhysicalReqGPSM 1;
BA_ "U_P552_MY15_Gas_Rx" SG_ 1793 TesterPhysicalReqGPSM 1;
BA_ "U_S550_MY15_Gas_Rx" SG_ 1793 TesterPhysicalReqGPSM 1;
BA_ "U_C489_MY14_Gas_Rx" SG_ 1793 TesterPhysicalReqGPSM 1;
BA_ "U_U502_MY15_Gas_Rx" SG_ 1793 TesterPhysicalReqGPSM 1;
BA_ "U_UP375_MY15_Gas_Rx" SG_ 1793 TesterPhysicalReqGPSM 1;
BA_ "U_UP375_MY15_Diesel_Rx" SG_ 1793 TesterPhysicalReqGPSM 1;
BA_ "U_CD43_MY16_Gas_Rx" SG_ 1793 TesterPhysicalReqGPSM 1;
VAL_ 292 ClmtCtrlSeat_SetCmd_Psgr 128 "H3_High_Heat__MAX" 64 "H2_Medium_Heat" 32 "H1_Low_Heat" 16 "C3_High_Cool__MAX" 8 "C2_Medium_Cool" 4 "C1_Low_Cool" 2 "Off" ;
VAL_ 292 ClmtCtrlSeat_SetCmd_Dvr 128 "H3_High_Heat__MAX" 64 "H2_Medium_Heat" 32 "H1_Low_Heat" 16 "C3_High_Cool__MAX" 8 "C2_Medium_Cool" 4 "C1_Low_Cool" 2 "Off" ;
VAL_ 1126 GpsUtcYr_No_Actl 31 "Fault" ;
VAL_ 1126 GpsUtcMnth_No_Actl 15 "Fault" ;
VAL_ 1126 GPS_UTC_seconds 63 "Fault" 62 "Unknown" ;
VAL_ 1126 GPS_UTC_minutes 63 "Fault" 62 "Unknown" ;
VAL_ 1126 GPS_UTC_hours 31 "Invalid" 30 "Unknown" ;
VAL_ 1126 GPS_Pdop 31 "Invalid" 30 "Unknown" ;
VAL_ 1126 GPS_Compass_direction 7 "NorthWest" 6 "West" 5 "SouthWest" 4 "South" 3 "SouthEast" 2 "East" 1 "NorthEast" 0 "North" ;
VAL_ 1126 GPS_Actual_vs_Infer_pos 1 "Inferred_Position" 0 "Actual_Postition" ;
VAL_ 1126 Gps_B_Falt 1 "Yes" 0 "No" ;
VAL_ 1125 GpsHsphLongEast_D_Actl 0 "Invalid" 1 "Eastern" 2 "Western" 3 "Fault" ;
VAL_ 1125 GpsHsphLattSth_D_Actl 3 "Fault" 2 "Northern" 1 "Southern" 0 "Invalid" ;
VAL_ 1125 GPS_Longitude_Minutes 63 "Fault" 62 "Unknown" ;
VAL_ 1125 GPS_Longitude_Min_dec 16383 "Invalid" 16382 "Unknown" ;
VAL_ 1125 GPS_Longitude_Degrees 511 "Fault" 510 "Unknown" ;
VAL_ 1125 GPS_Latitude_Minutes 63 "Fault" 62 "Unknown" ;
VAL_ 1125 GPS_Latitude_Min_dec 16383 "Invalid" 16382 "Unknown" ;
VAL_ 1125 GPS_Latitude_Degrees 255 "Invalid" 254 "Unknown" ;
VAL_ 992 MsgCntrPersIndex_D_Rq 7 "Unused_3" 6 "Unused_2" 5 "Unused_1" 4 "Vehicle" 3 "PERS_4" 2 "PERS_3" 1 "PERS_2" 0 "PERS_1" ;
VAL_ 992 MsgCntrDsplyOp_D_Rq 7 "Unused_2" 6 "Unused_1" 5 "Copy" 4 "Restore" 3 "Upload" 2 "Set" 1 "Query" 0 "Null" ;
VAL_ 1127 GPS_Vdop 31 "Invalid" 30 "Unknown" ;
VAL_ 1127 GPS_Speed 255 "Invalid" 254 "Unknown" ;
VAL_ 1127 GPS_Sat_num_in_view 31 "Invalid" 30 "Unknown" ;
VAL_ 1127 GPS_MSL_altitude 4095 "Fault" 4094 "Unknown" ;
VAL_ 1127 GPS_Heading 65535 "Fault" 65534 "Unknown" ;
VAL_ 1127 GPS_Hdop 31 "Invalid" 30 "Unknown" ;
VAL_ 1127 GPS_dimension 2 "_3D" 1 "_2D" 0 "No_Fix" ;
VAL_ 861 SteWhlHeat_D_Stat 15 "NotUsed6" 14 "NotUsed5" 13 "NotUsed4" 12 "NotUsed3" 11 "NotUsed2" 10 "NotUsed1" 9 "Reserved_3" 8 "Reserved_2" 7 "Reserved_1" 6 "Level_3_Heating" 5 "Level_3_Heating_LS" 4 "Level_2_Heating" 3 "Level_2_Heating_LS" 2 "Level_1_Heating" 1 "Level_1_Heating_LS" 0 "Off" ;
VAL_ 999 PersIndexFcim_D_Actl 7 "Unused_3" 6 "Unused_2" 5 "Unused_1" 4 "Vehicle" 3 "PERS_4" 2 "PERS_3" 1 "PERS_2" 0 "PERS_1" ;
VAL_ 862 TwHlGrdAsst_B_RqTrn 1 "On" 0 "Off" ;
VAL_ 862 ApaSwtch_D_RqDrv 3 "Faulty" 2 "Stuck" 1 "Pressed" 0 "NotPressed" ;
VAL_ 862 HvacBlwrFront_D_Stat 31 "Not_Used" 20 "Full_On" 19 "95_Percent" 18 "90_Percent" 17 "85_Percent" 16 "80_Percent" 15 "75_Percent" 14 "70_Percent" 13 "65_Percent" 12 "60_Percent" 11 "55_Percent" 10 "50_Percent" 9 "45_Percent" 8 "40_Percent" 7 "35_Percent" 6 "30_Percent" 5 "25_Percent" 4 "20_Percent" 3 "15_Percent" 2 "10_Percent" 1 "5_Percent" 0 "Off" ;
VAL_ 862 HvacBlwrRear_D_Stat 31 "Not_Used" 20 "Full_On" 19 "95_Percent" 18 "90_Percent" 17 "85_Percent" 16 "80_Percent" 15 "75_Percent" 14 "70_Percent" 13 "65_Percent" 12 "60_Percent" 11 "55_Percent" 10 "50_Percent" 9 "45_Percent" 8 "40_Percent" 7 "35_Percent" 6 "30_Percent" 5 "25_Percent" 4 "20_Percent" 3 "15_Percent" 2 "10_Percent" 1 "5_Percent" 0 "Off" ;
VAL_ 862 ClimtThrmlLoad_No_Actl 255 "Fault" ;
VAL_ 862 AutoStpHvacDelta_I_Est 255 "Fault" ;
VAL_ 828 RearPassWindowPos 7 "Unused2" 6 "Unused1" 5 "Fully_Open" 4 "Bet60Percent_FullyOpen" 3 "Bet10Percent_60Percent" 2 "BetFully_10PercentOpen" 1 "Fully_Closed" 0 "Undefined" ;
VAL_ 828 PassWindowPosition 7 "Unused2" 6 "Unused1" 5 "Fully_Open" 4 "Bet60Percent_FullyOpen" 3 "Bet10Percent_60Percent" 2 "BetFully_10PercentOpen" 1 "Fully_Closed" 0 "Undefined" ;
VAL_ 826 Memory_3_Sw_Stat 1 "Pressed" 0 "Null" ;
VAL_ 826 Memory_2_Sw_Stat 1 "Pressed" 0 "Null" ;
VAL_ 826 Memory_1_Sw_Stat 1 "Pressed" 0 "Null" ;
VAL_ 826 Mirror_Manual_Override 1 "Override" 0 "Null" ;
VAL_ 853 RHS_Cond_Seat_Status 7 "Unused" 6 "Level_3_Heating" 5 "Level_2_Heating" 4 "Level_1_Heating" 3 "Level_3_Cooling" 2 "Level_2_Cooling" 1 "Level_1_Cooling" 0 "Off" ;
VAL_ 853 LHS_Cond_Seat_Status 7 "Unused" 6 "Level_3_Heating" 5 "Level_2_Heating" 4 "Level_1_Heating" 3 "Level_3_Cooling" 2 "Level_2_Cooling" 1 "Level_1_Cooling" 0 "Off" ;
VAL_ 853 Htd_Strg_Whl_Status 3 "Level_3_Heating" 2 "Level_2_Heating" 1 "Level_1_Heating" 0 "Off" ;
VAL_ 853 Htd_Strg_Whl_Btn_Stt 3 "Unused" 2 "Disabled" 1 "Active" 0 "Enabled_Inactive" ;
VAL_ 853 Defrost_Btn_Stt 3 "Unused" 2 "Disabled" 1 "Active" 0 "Enabled_Inactive" ;
VAL_ 853 CC_Fr_Btn_User_Adj 31 "Unused15" 30 "Unused14" 29 "Unused13" 28 "Unused12" 27 "Unused11" 26 "Unused10" 25 "Unused9" 24 "Unused8" 23 "Unused7" 22 "Unused6" 21 "Unused5" 20 "Unused4" 19 "Unused3" 18 "Unused2" 17 "Unused1" 16 "Htd_WS_Selection" 15 "FLR_Cnd_St_Selection" 14 "FLH_Cnd_St_Selection" 13 "HSW_Selection" 12 "Dual_Selection" 11 "Rear_Defrost_Selection" 10 "Max_Defrost_Selection" 9 "Defrost_Selection" 8 "Fr_Air_Dist_Selection" 7 "Max_AC_Selection" 6 "Fr_Power_Selection" 5 "Recirc_Selection" 4 "AC_Selection" 3 "Fr_Auto_Selection" 2 "Use_MyTemp_Selection" 1 "Save_MyTemp_Selection" 0 "None" ;
VAL_ 853 RHS_Htd_Seat_Btn_Stt 3 "Unused" 2 "Disabled" 1 "Active" 0 "Enabled_Inactive" ;
VAL_ 853 RHS_Cld_Seat_Btn_Stt 3 "Unused" 2 "Disabled" 1 "Active" 0 "Enabled_Inactive" ;
VAL_ 853 Outside_Btn_Stt 3 "Unused" 2 "Disabled" 1 "Active" 0 "Enabled_Inactive" ;
VAL_ 853 LHS_Htd_Seat_Btn_Stt 3 "Unused" 2 "Disabled" 1 "Active" 0 "Enabled_Inactive" ;
VAL_ 853 LHS_Cld_Seat_Btn_Stt 3 "Unused" 2 "Disabled" 1 "Active" 0 "Enabled_Inactive" ;
VAL_ 853 Htd_Frt_Wsh_Btn_Stt 3 "Unused" 2 "Disabled" 1 "Active" 0 "Enabled_Inactive" ;
VAL_ 853 Auto_Recirc_Btn_Stt 3 "Unused" 2 "Disabled" 1 "Active" 0 "Enabled_Inactive" ;
VAL_ 853 Recirc_Btn_Stt 3 "Unused" 2 "Disabled" 1 "Active" 0 "Enabled_Inactive" ;
VAL_ 853 Rear_Defrost_Btn_Stt 3 "Unused" 2 "Disabled" 1 "Active" 0 "Enabled_Inactive" ;
VAL_ 853 My_Temp_Btn_Stt 3 "Unused" 2 "Disabled" 1 "Active" 0 "Enabled_Inactive" ;
VAL_ 853 Max_Defrost_Btn_Stt 3 "Unused" 2 "Disabled" 1 "Active" 0 "Enabled_Inactive" ;
VAL_ 853 Max_AC_Btn_Stt 3 "Unused" 2 "Disabled" 1 "Active" 0 "Enabled_Inactive" ;
VAL_ 853 Front_AUTO_Label 3 "Full" 2 "Mode" 1 "Blower" 0 "Off" ;
VAL_ 853 Windscreen_Btn_Stt 3 "Unused" 2 "Disabled" 1 "Active" 0 "Enabled_Inactive" ;
VAL_ 853 Panel_Btn_Stt 3 "Unused" 2 "Disabled" 1 "Active" 0 "Enabled_Inactive" ;
VAL_ 853 Front_Power_Btn_Stt 3 "Unused" 2 "Disabled" 1 "Active" 0 "Enabled_Inactive" ;
VAL_ 853 Front_AUTO_Btn_Stt 3 "Unused" 2 "Disabled" 1 "Active" 0 "Enabled_Inactive" ;
VAL_ 853 Floor_Btn_Stt 3 "Unused" 2 "Disabled" 1 "Active" 0 "Enabled_Inactive" ;
VAL_ 853 Dual_Button_Stt 3 "Unused" 2 "Disabled" 1 "Active" 0 "Enabled_Inactive" ;
VAL_ 853 AC_Btn_Stt 3 "Unused" 2 "Disabled" 1 "Active" 0 "Enabled_Inactive" ;
VAL_ 956 PwSrcULoFalt_D_Stat_UB 1 "Fresh_data" 0 "Unchanged_data" ;
VAL_ 956 PwSrcULo_Pc_Mx_UB 1 "Fresh_data" 0 "Unchanged_data" ;
VAL_ 956 PwSrcULo_Pc_Mx 255 "Fault" ;
VAL_ 956 SAPPStatusCoding_UB 1 "Fresh_data" 0 "Unchanged_data" ;
VAL_ 956 PwSrcULoFalt_D_Stat 3 "Fault_No_Output" 2 "Fault_Reduced_Output" 1 "Fault_NonSpecific" 0 "No_Fault" ;
VAL_ 956 PrkBrkStatus 7 "GeneralFault_MaintenceMode" 6 "ECD_by_Brake_ECU_Active" 5 "EPB_Limphome_Active" 4 "Rear_Caliper_Open" 3 "RWU_By_EPB_Active" 2 "Rear_Caliper_Transition" 1 "Rear_Caliper_Closed" 0 "Not_Supported" ;
VAL_ 956 GearLvrPos_D_Actl_UB 1 "Fresh_data" 0 "Unchanged_data" ;
VAL_ 956 PrkBrkStatus_UB 1 "Fresh_data" 0 "Unchanged_data" ;
VAL_ 956 ApedPos_Pc_ActlArb_UB 1 "Fresh_data" 0 "Unchanged_data" ;
VAL_ 956 GearLvrPos_D_Actl 15 "Fault" 14 "Unknown_Position" 13 "Undefined_Treat_as__Fault" 12 "Undefined_Treat_as_Fault" 11 "sixth" 10 "fifth" 9 "fourth" 8 "third" 7 "second" 6 "first" 5 "Low" 4 "Sport_DriveSport" 3 "Drive" 2 "Neutral" 1 "Reverse" 0 "Park" ;
VAL_ 831 RearPassWindowLockCmd 1 "Enable" 0 "Disable" ;
VAL_ 831 RearPassWindowCmd 7 "Unused2" 6 "Unused1" 5 "NotDefined" 4 "Audo_Down" 3 "Manual_Down" 2 "Auto_Up" 1 "Manual_Up" 0 "Idle" ;
VAL_ 831 PassWindowCmd 7 "Unused2" 6 "Unused1" 5 "NotDefined" 4 "Audo_Down" 3 "Manual_Down" 2 "Auto_Up" 1 "Manual_Up" 0 "Idle" ;
VAL_ 831 PassMirrorCmd 7 "Unused" 6 "Unfold" 5 "Fold" 4 "Right" 3 "Left" 2 "Down" 1 "Up" 0 "Idle" ;
VAL_ 831 DipMirrorPosPassenger 1 "Dipped" 0 "Off" ;
VAL_ 831 ActiveStoragePassenger 7 "Unused3" 6 "Unused2" 5 "Unused1" 4 "StoreDipMemoryButton4" 3 "StoreDipMemoryButton3" 2 "StoreDipMemoryButton2" 1 "StoreDipMemoryButton1" 0 "Off" ;
VAL_ 831 RearDriverWindowPos 7 "Unused2" 6 "Unused1" 5 "Fully_Open" 4 "Bet60Percent_FullyOpen" 3 "Bet10Percent_60Percent" 2 "BetFully_10PercentOpen" 1 "Fully_Closed" 0 "Undefined" ;
VAL_ 831 DriverWindowPosition 7 "Unused2" 6 "Unused1" 5 "Fully_Open" 4 "Bet60Percent_FullyOpen" 3 "Bet10Percent_60Percent" 2 "BetFully_10PercentOpen" 1 "Fully_Closed" 0 "Undefined" ;
